CM_ "AUTOGENERATED MERGED FILE FROM MULTIPLE DBC FILES";

VERSION ""

NS_ :

BS_:

BU_: AAF AAF_Tester ABS ACU ADRV AEMC AFLS AHLS APRK AVM BCM CAMERA CGW CLU CUBIS DATC DI_BOX Dummy ECS EMS EPB ESC EVP FATC FPCM FRONT_RADAR HUD IAP IBOX LCA LDWS_LKAS LPI LVR MDPS MTS ODS OPI PGS PSB REA SAS SCC SMK SNV SPAS TCU TMU TPMS _4WD

VAL_TABLE_
    SIG_GROUP_
    SIG_VALTYPE_
    SIGTYPE_VALTYPE_
    BO_TX_BU_
    BA_DEF_REL_
    BA_REL_
    BA_DEF_DEF_REL_
    BU_SG_REL_
    BU_EV_REL_
    BU_BO_REL_
    SG_MUL_VAL_

BS_:

BU_: XXX CAMERA FRONT_RADAR ADRV APRK

BO_ 53 ACCELERATOR: 32 XXX
 SG_ CHECKSUM : 0|16@1+ (1,0) [0|65535] "" XXX
 SG_ COUNTER : 16|8@1+ (1,0) [0|255] "" XXX
 SG_ GEAR : 192|3@1+ (1,0) [0|7] "" XXX
 SG_ ACCELERATOR_PEDAL : 40|8@1+ (1,0) [0|255] "" XXX

BO_ 64 GEAR_ALT: 32 XXX
 SG_ CHECKSUM : 0|16@1+ (1,0) [0|65535] "" XXX
 SG_ COUNTER : 16|8@1+ (1,0) [0|255] "" XXX
 SG_ GEAR : 32|3@1+ (1,0) [0|7] "" XXX

BO_ 69 GEAR: 24 XXX
 SG_ CHECKSUM : 0|16@1+ (1,0) [0|65535] "" XXX
 SG_ COUNTER : 16|8@1+ (1,0) [0|255] "" XXX
 SG_ GEAR : 44|3@1+ (1,0) [0|7] "" XXX

BO_ 80 LKAS: 16 XXX
 SG_ STEER_REQ : 52|1@1+ (1,0) [0|1] "" XXX
 SG_ TORQUE_REQUEST : 41|11@1+ (1,-1024) [0|4095] "" XXX
 SG_ LKA_ICON : 38|2@1+ (1,0) [0|255] "" XXX
 SG_ NEW_SIGNAL_1 : 27|2@1+ (1,0) [0|255] "" XXX
 SG_ LFA_BUTTON : 56|1@1+ (1,0) [0|255] "" XXX
 SG_ COUNTER : 16|8@1+ (1,0) [0|255] "" XXX
 SG_ CHECKSUM : 0|16@1+ (1,0) [0|65535] "" XXX
 SG_ STEER_MODE : 65|3@1+ (1,0) [0|1] "" XXX
 SG_ LKA_WARNING : 32|1@1+ (1,0) [0|1] "" XXX
 SG_ LKA_ASSIST : 62|1@1+ (1,0) [0|1] "" XXX
 SG_ LKA_MODE : 24|3@1+ (1,0) [0|7] "" XXX
 SG_ NEW_SIGNAL_2 : 70|2@0+ (1,0) [0|3] "" XXX
 SG_ HAS_LANE_SAFETY : 80|1@0+ (1,0) [0|1] "" XXX
 SG_ NEW_SIGNAL_3 : 111|8@0+ (1,0) [0|255] "" XXX
 SG_ FCA_SYSWARN : 40|1@0+ (1,0) [0|1] "" XXX

BO_ 81 ADRV_0x51: 32 ADRV
 SG_ COUNTER : 16|8@1+ (1,0) [0|255] "" XXX
 SG_ CHECKSUM : 0|16@1+ (1,0) [0|65535] "" XXX

BO_ 96 ESP_STATUS: 32 XXX
 SG_ CHECKSUM : 0|16@1+ (1,0) [0|65535] "" XXX
 SG_ COUNTER : 16|8@1+ (1,0) [0|255] "" XXX
 SG_ TRACTION_AND_STABILITY_CONTROL : 42|3@1+ (1,0) [0|63] "" XXX
 SG_ BRAKE_PRESSURE : 128|10@1+ (1,0) [0|65535] "" XXX
 SG_ BRAKE_PRESSED : 148|1@1+ (1,0) [0|3] "" XXX

BO_ 101 BRAKE: 32 XXX
 SG_ CHECKSUM : 0|16@1+ (1,0) [0|65535] "" XXX
 SG_ COUNTER : 16|8@1+ (1,0) [0|255] "" XXX
 SG_ BRAKE_POSITION : 40|16@1- (1,0) [0|65535] "" XXX
 SG_ BRAKE_PRESSED : 57|1@1+ (1,0) [0|3] "" XXX

BO_ 112 GEAR_ALT_2: 32 XXX
 SG_ CHECKSUM : 0|16@1+ (1,0) [0|65535] "" XXX
 SG_ COUNTER : 16|8@1+ (1,0) [0|255] "" XXX
 SG_ GEAR : 60|3@1+ (1,0) [0|7] "" XXX

BO_ 160 WHEEL_SPEEDS: 24 XXX
 SG_ CHECKSUM : 0|16@1+ (1,0) [0|65535] "" XXX
 SG_ COUNTER : 16|8@1+ (1,0) [0|255] "" XXX
 SG_ MOVING_FORWARD : 56|1@0+ (1,0) [0|1] "" XXX
 SG_ MOVING_BACKWARD : 57|1@0+ (1,0) [0|1] "" XXX
 SG_ MOVING_FORWARD2 : 58|1@0+ (1,0) [0|1] "" XXX
 SG_ MOVING_BACKWARD2 : 59|1@0+ (1,0) [0|1] "" XXX
 SG_ WHEEL_SPEED_1 : 64|16@1+ (0.03125,0) [0|65535] "kph" XXX
 SG_ WHEEL_SPEED_2 : 80|16@1+ (0.03125,0) [0|65535] "kph" XXX
 SG_ WHEEL_SPEED_3 : 96|16@1+ (0.03125,0) [0|65535] "kph" XXX
 SG_ WHEEL_SPEED_4 : 112|16@1+ (0.03125,0) [0|65535] "kph" XXX

BO_ 234 MDPS: 24 XXX
 SG_ CHECKSUM : 0|16@1+ (1,0) [0|65535] "" XXX
 SG_ COUNTER : 16|8@1+ (1,0) [0|255] "" XXX
 SG_ LKA_ACTIVE : 48|1@0+ (1,0) [0|16777215] "" XXX
 SG_ LKA_FAULT : 54|1@0+ (1,0) [0|1] "" XXX
 SG_ STEERING_OUT_TORQUE : 64|12@1+ (0.1,-204.8) [0|65535] "" XXX
 SG_ STEERING_COL_TORQUE : 80|13@1+ (1,-4095) [0|4095] "" XXX
 SG_ STEERING_ANGLE : 96|16@1- (-0.1,0) [0|255] "deg" XXX
 SG_ STEERING_ANGLE_2 : 128|16@1- (-0.1,0) [0|65535] "deg" XXX

BO_ 256 ACCELERATOR_BRAKE_ALT: 32 XXX
 SG_ CHECKSUM : 0|16@1+ (1,0) [0|65535] "" XXX
 SG_ COUNTER : 16|8@1+ (1,0) [0|255] "" XXX
 SG_ BRAKE_PRESSED : 32|1@1+ (1,0) [0|1] "" XXX
 SG_ ACCELERATOR_PEDAL_PRESSED : 176|1@1+ (1,0) [0|1] "" XXX

BO_ 261 ACCELERATOR_ALT: 32 XXX
 SG_ CHECKSUM : 0|16@1+ (1,0) [0|65535] "" XXX
 SG_ COUNTER : 16|8@1+ (1,0) [0|255] "" XXX
 SG_ ACCELERATOR_PEDAL : 103|10@1+ (0.25,0) [0|1022] "" XXX

BO_ 272 LKAS_ALT: 32 XXX
 SG_ STEER_REQ : 52|1@1+ (1,0) [0|1] "" XXX
 SG_ TORQUE_REQUEST : 41|11@1+ (1,-1024) [0|4095] "" XXX
 SG_ LKA_ICON : 38|2@1+ (1,0) [0|255] "" XXX
 SG_ NEW_SIGNAL_1 : 27|2@1+ (1,0) [0|255] "" XXX
 SG_ LFA_BUTTON : 56|1@1+ (1,0) [0|255] "" XXX
 SG_ COUNTER : 16|8@1+ (1,0) [0|255] "" XXX
 SG_ CHECKSUM : 0|16@1+ (1,0) [0|65535] "" XXX
 SG_ STEER_MODE : 65|3@1+ (1,0) [0|1] "" XXX
 SG_ LKA_WARNING : 32|1@1+ (1,0) [0|1] "" XXX
 SG_ LKA_ASSIST : 62|1@1+ (1,0) [0|1] "" XXX
 SG_ LKA_MODE : 24|3@1+ (1,0) [0|7] "" XXX
 SG_ NEW_SIGNAL_2 : 70|2@0+ (1,0) [0|3] "" XXX
 SG_ HAS_LANE_SAFETY : 80|1@0+ (1,0) [0|1] "" XXX
 SG_ NEW_SIGNAL_3 : 111|8@0+ (1,0) [0|255] "" XXX
 SG_ FCA_SYSWARN : 40|1@0+ (1,0) [0|1] "" XXX

BO_ 293 STEERING_SENSORS: 16 XXX
 SG_ CHECKSUM : 0|16@1+ (1,0) [0|65535] "" XXX
 SG_ COUNTER : 16|8@1+ (1,0) [0|255] "" XXX
 SG_ STEERING_RATE : 40|8@1+ (4,0) [0|1016] "deg/s" XXX
 SG_ STEERING_ANGLE : 24|16@1- (-0.1,0) [0|255] "deg" XXX

BO_ 298 LFA: 16 ADRV
 SG_ STEER_REQ : 52|1@1+ (1,0) [0|1] "" XXX
 SG_ TORQUE_REQUEST : 41|11@1+ (1,-1024) [0|4095] "" XXX
 SG_ LKA_ICON : 38|2@1+ (1,0) [0|255] "" XXX
 SG_ NEW_SIGNAL_1 : 27|2@1+ (1,0) [0|255] "" XXX
 SG_ LFA_BUTTON : 56|1@1+ (1,0) [0|255] "" XXX
 SG_ COUNTER : 16|8@1+ (1,0) [0|255] "" XXX
 SG_ CHECKSUM : 0|16@1+ (1,0) [0|65535] "" XXX
 SG_ STEER_MODE : 65|3@1+ (1,0) [0|1] "" XXX
 SG_ LKA_WARNING : 32|1@1+ (1,0) [0|1] "" XXX
 SG_ LKA_ASSIST : 62|1@1+ (1,0) [0|1] "" XXX
 SG_ LKA_MODE : 24|3@1+ (1,0) [0|7] "" XXX
 SG_ NEW_SIGNAL_2 : 70|2@0+ (1,0) [0|3] "" XXX
 SG_ HAS_LANE_SAFETY : 80|1@0+ (1,0) [0|1] "" XXX
 SG_ NEW_SIGNAL_3 : 111|8@0+ (1,0) [0|255] "" XXX

BO_ 304 GEAR_SHIFTER: 16 XXX
 SG_ CHECKSUM : 0|16@1+ (1,0) [0|65535] "" XXX
 SG_ COUNTER : 16|8@1+ (1,0) [0|255] "" XXX
 SG_ PARK_BUTTON : 32|2@1+ (1,0) [0|3] "" XXX
 SG_ GEAR : 64|3@1+ (1,0) [0|7] "" XXX
 SG_ KNOB_POSITION : 40|3@1+ (1,0) [0|3] "" XXX

BO_ 357 SPAS1: 24 APRK
 SG_ CHECKSUM : 0|16@1+ (1,0) [0|65535] "" XXX
 SG_ COUNTER : 16|8@1+ (1,0) [0|0] "" XXX
 SG_ NEW_SIGNAL_1 : 96|16@1- (0.1,0) [0|0] "" XXX
 SG_ NEW_SIGNAL_2 : 90|3@1+ (1,0) [0|0] "" XXX

BO_ 362 SPAS2: 32 APRK
 SG_ CHECKSUM : 0|16@1+ (1,0) [0|65535] "" XXX
 SG_ COUNTER : 16|8@1+ (1,0) [0|0] "" XXX
 SG_ BLINKER_CONTROL : 133|3@1+ (1,0) [0|0] "" XXX

BO_ 373 TCS: 24 XXX
 SG_ CHECKSUM : 0|16@1+ (1,0) [0|65535] "" XXX
 SG_ COUNTER : 16|8@1+ (1,0) [0|255] "" XXX
 SG_ NEW_SIGNAL_1 : 80|1@0+ (1,0) [0|1] "" XXX
 SG_ NEW_SIGNAL_2 : 74|1@0+ (1,0) [0|1] "" XXX
 SG_ NEW_SIGNAL_3 : 76|1@0+ (1,0) [0|1] "" XXX
 SG_ NEW_SIGNAL_4 : 24|7@1+ (1,0) [0|127] "" XXX
 SG_ aBasis : 32|11@1+ (0.01,-10.23) [0|7] "m/s^2" XXX
 SG_ NEW_SIGNAL_5 : 72|1@0+ (1,0) [0|1] "" XXX
 SG_ NEW_SIGNAL_6 : 128|4@1+ (1,0) [0|15] "" XXX
 SG_ NEW_SIGNAL_7 : 135|2@0+ (1,0) [0|3] "" XXX
 SG_ PROBABLY_EQUIP : 136|2@1+ (1,0) [0|3] "" XXX
 SG_ AEB_EQUIP_MAYBE : 96|1@0+ (1,0) [0|1] "" XXX
 SG_ EQUIP_MAYBE : 64|1@0+ (1,0) [0|1] "" XXX
 SG_ DriverBraking : 81|1@0+ (1,0) [0|1] "" XXX
 SG_ DriverBrakingLowSens : 84|1@1+ (1,0) [0|1] "" XXX
 SG_ ACC_REQ : 68|1@0+ (1,0) [0|1] "" XXX
 SG_ ACCEL_REF_ACC : 48|11@1- (1,0) [0|1023] "" XXX
 SG_ ACCEnable : 67|2@0+ (1,0) [0|3] "" XXX

BO_ 352 ADRV_0x160: 16 ADRV
 SG_ CHECKSUM : 0|16@1+ (1,0) [0|65535] "" XXX
 SG_ COUNTER : 16|8@1+ (1,0) [0|255] "" XXX
 SG_ SET_ME_FF : 64|8@1+ (1,0) [0|255] "" XXX
 SG_ SET_ME_FC : 72|8@1+ (1,0) [0|255] "" XXX
 SG_ SET_ME_2 : 56|8@1+ (1,0) [0|1] "" XXX
 SG_ AEB_SETTING : 24|2@1+ (1,0) [0|255] "" XXX
 SG_ SET_ME_9 : 80|8@1+ (1,0) [0|255] "" XXX

BO_ 384 CAM_0x180: 32 CAMERA
 SG_ CHECKSUM : 0|16@1+ (1,0) [0|65535] "" XXX
 SG_ COUNTER : 16|8@1+ (1,0) [0|255] "" XXX

BO_ 385 CAM_0x181: 32 CAMERA
 SG_ CHECKSUM : 0|16@1+ (1,0) [0|65535] "" XXX
 SG_ COUNTER : 16|8@1+ (1,0) [0|255] "" XXX

BO_ 386 CAM_0x182: 32 CAMERA
 SG_ CHECKSUM : 0|16@1+ (1,0) [0|65535] "" XXX
 SG_ COUNTER : 16|8@1+ (1,0) [0|255] "" XXX

BO_ 387 CAM_0x183: 32 CAMERA
 SG_ CHECKSUM : 0|16@1+ (1,0) [0|65535] "" XXX
 SG_ COUNTER : 16|8@1+ (1,0) [0|255] "" XXX

BO_ 388 CAM_0x184: 32 CAMERA
 SG_ CHECKSUM : 0|16@1+ (1,0) [0|65535] "" XXX
 SG_ COUNTER : 16|8@1+ (1,0) [0|255] "" XXX

BO_ 389 CAM_0x185: 8 CAMERA
 SG_ CHECKSUM : 0|16@1+ (1,0) [0|65535] "" XXX
 SG_ COUNTER : 16|8@1+ (1,0) [0|255] "" XXX

BO_ 416 SCC_CONTROL: 32 ADRV
 SG_ CHECKSUM : 0|16@1+ (1,0) [0|65535] "" XXX
 SG_ NEW_SIGNAL_1 : 64|2@1+ (1,0) [0|3] "" XXX
 SG_ NEW_SIGNAL_8 : 170|4@1+ (1,0) [0|15] "" XXX
 SG_ ZEROS : 215|48@0+ (1,0) [0|281474976710655] "" XXX
 SG_ ZEROS_3 : 191|7@0+ (1,0) [0|127] "" XXX
 SG_ ZEROS_4 : 183|4@0+ (1,0) [0|63] "" XXX
 SG_ ZEROS_6 : 119|16@0+ (1,0) [0|65535] "" XXX
 SG_ ZEROS_8 : 95|5@0+ (1,0) [0|31] "" XXX
 SG_ NEW_SIGNAL_3 : 109|2@0+ (1,0) [0|1] "" XXX
 SG_ SET_ME_TMP_64 : 55|8@0+ (1,0) [0|63] "" XXX
 SG_ SET_ME_2 : 105|3@1+ (1,0) [0|7] "" XXX
 SG_ NEW_SIGNAL_6 : 104|1@0+ (1,0) [0|1] "" XXX
 SG_ COUNTER : 16|8@1+ (1,0) [0|255] "" XXX
 SG_ ZEROS_9 : 71|5@1+ (1,0) [0|15] "" XXX
 SG_ ZEROS_10 : 111|2@0+ (1,0) [0|3] "" XXX
 SG_ SET_ME_3 : 45|2@0+ (1,0) [0|3] "" XXX
 SG_ ObjValid : 46|1@0+ (1,0) [0|3] "" XXX
 SG_ NEW_SIGNAL_2 : 168|2@1+ (1,0) [0|3] "" XXX
 SG_ OBJ_STATUS : 176|3@1+ (1,0) [0|7] "" XXX
 SG_ ACC_ObjDist : 24|11@1+ (0.1,0) [0|204.7] "m" XXX
 SG_ ZEROS_5 : 77|11@1+ (1,0) [0|2047] "" XXX
 SG_ DISTANCE_SETTING : 88|3@1+ (1,0) [0|3] "" XXX
 SG_ ZEROS_2 : 207|5@0+ (1,0) [0|63] "" XXX
 SG_ CRUISE_STANDSTILL : 76|1@1+ (1,0) [0|1] "" XXX
 SG_ aReqRaw : 140|11@1+ (0.01,-10.23) [-10.23|10.24] "m/s^2" XXX
 SG_ aReqValue : 128|11@1+ (0.01,-10.23) [-10.23|10.24] "m/s^2" XXX
 SG_ ZEROS_7 : 63|8@0+ (1,0) [0|255] "" XXX
 SG_ ACCMode : 68|3@1+ (1,0) [0|7] "" XXX
 SG_ ACC_ObjRelSpd : 35|9@1+ (0.1,-16.4) [-16.4|34.7] "m/s" XXX
 SG_ JerkLowerLimit : 166|7@0+ (0.1,0) [0|12.7] "m/s^3" XXX
 SG_ StopReq : 184|1@0+ (1,0) [0|1] "" XXX
 SG_ NEW_SIGNAL_15 : 192|11@1+ (0.1,0) [0|204.7] "m" XXX
 SG_ VSetDis : 103|8@0+ (1,0) [0|255] "km/h or mph" XXX
 SG_ MainMode_ACC : 66|1@1+ (1,0) [0|1] "" XXX
 SG_ JerkUpperLimit : 158|7@0+ (0.1,0) [0|0] "" XXX

BO_ 426 CRUISE_BUTTONS_ALT: 16 XXX
 SG_ CHECKSUM : 0|16@1+ (1,0) [0|65535] "" XXX
 SG_ COUNTER : 16|8@1+ (1,0) [0|255] "" XXX
 SG_ NEW_SIGNAL_1 : 24|4@1+ (1,0) [0|15] "" XXX
 SG_ SET_ME_1 : 28|2@1+ (1,0) [0|3] "" XXX
 SG_ DISTANCE_UNIT : 30|1@1+ (1,0) [0|1] "" XXX
 SG_ NEW_SIGNAL_2 : 31|3@1+ (1,0) [0|7] "" XXX
 SG_ ADAPTIVE_CRUISE_MAIN_BTN : 34|1@1+ (1,0) [0|1] "" XXX
 SG_ NEW_SIGNAL_3 : 35|1@1+ (1,0) [0|1] "" XXX
 SG_ LFA_BTN : 39|1@1+ (1,0) [0|1] "" XXX
 SG_ CRUISE_BUTTONS : 36|3@1+ (1,0) [0|4] "" XXX
 SG_ NEW_SIGNAL_4 : 40|1@1+ (1,0) [0|1] "" XXX
 SG_ NORMAL_CRUISE_MAIN_BTN : 41|1@1+ (1,0) [0|1] "" XXX
 SG_ NEW_SIGNAL_5 : 42|2@1+ (1,0) [0|3] "" XXX
 SG_ SET_ME_2 : 44|3@1+ (1,0) [0|7] "" XXX
 SG_ NEW_SIGNAL_6 : 47|1@1+ (1,0) [0|1] "" XXX
 SG_ BYTE6 : 48|8@1+ (1,0) [0|255] "" XXX
 SG_ BYTE7 : 56|8@1+ (1,0) [0|255] "" XXX
 SG_ BYTE8 : 64|8@1+ (1,0) [0|255] "" XXX
 SG_ BYTE9 : 72|8@1+ (1,0) [0|255] "" XXX
 SG_ BYTE10 : 80|8@1+ (1,0) [0|255] "" XXX
 SG_ BYTE11 : 88|8@1+ (1,0) [0|255] "" XXX
 SG_ BYTE12 : 96|8@1+ (1,0) [0|255] "" XXX
 SG_ BYTE13 : 104|8@1+ (1,0) [0|255] "" XXX
 SG_ BYTE14 : 112|8@1+ (1,0) [0|255] "" XXX
 SG_ BYTE15 : 120|8@1+ (1,0) [0|255] "" XXX

BO_ 438 CAM_0x1b6: 32 CAMERA
 SG_ CHECKSUM : 0|16@1+ (1,0) [0|65535] "" XXX
 SG_ COUNTER : 16|8@1+ (1,0) [0|255] "" XXX

BO_ 439 CAM_0x1b7: 32 CAMERA
 SG_ CHECKSUM : 0|16@1+ (1,0) [0|65535] "" XXX
 SG_ COUNTER : 16|8@1+ (1,0) [0|255] "" XXX

BO_ 440 CAM_0x1b8: 32 CAMERA
 SG_ CHECKSUM : 0|16@1+ (1,0) [0|65535] "" XXX
 SG_ COUNTER : 16|8@1+ (1,0) [0|255] "" XXX

BO_ 441 CAM_0x1b9: 32 CAMERA
 SG_ CHECKSUM : 0|16@1+ (1,0) [0|65535] "" XXX
 SG_ COUNTER : 16|8@1+ (1,0) [0|255] "" XXX

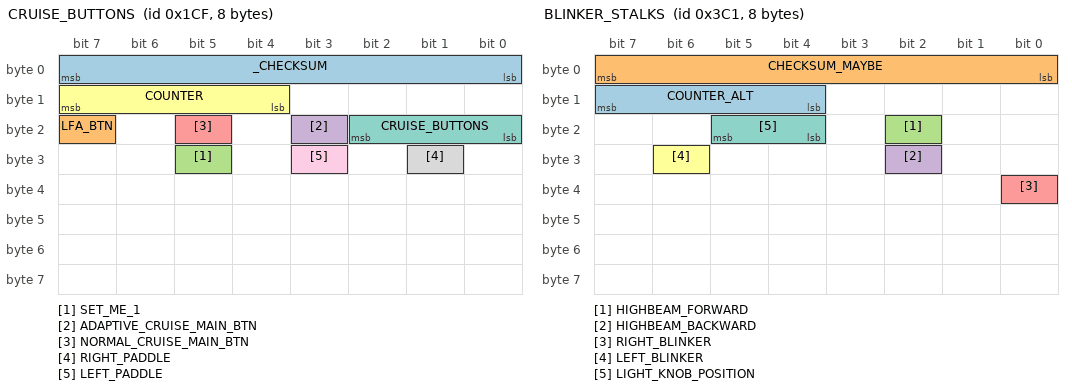
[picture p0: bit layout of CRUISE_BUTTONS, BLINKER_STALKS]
BO_ 463 CRUISE_BUTTONS: 8 XXX
 SG_ _CHECKSUM : 0|8@1+ (1,0) [0|65535] "" XXX
 SG_ LFA_BTN : 23|1@1+ (1,0) [0|1] "" XXX
 SG_ SET_ME_1 : 29|1@1+ (1,0) [0|1] "" XXX
 SG_ ADAPTIVE_CRUISE_MAIN_BTN : 19|1@1+ (1,0) [0|1] "" XXX
 SG_ NORMAL_CRUISE_MAIN_BTN : 21|1@1+ (1,0) [0|1] "" XXX
 SG_ COUNTER : 12|4@1+ (1,0) [0|255] "" XXX
 SG_ CRUISE_BUTTONS : 16|3@1+ (1,0) [0|3] "" XXX
 SG_ RIGHT_PADDLE : 25|1@1+ (1,0) [0|1] "" XXX
 SG_ LEFT_PADDLE : 27|1@1+ (1,0) [0|1] "" XXX

BO_ 474 ADRV_0x1da: 32 ADRV
 SG_ CHECKSUM : 0|16@1+ (1,0) [0|65535] "" XXX
 SG_ COUNTER : 16|8@1+ (1,0) [0|255] "" XXX
 SG_ SET_ME_22 : 31|8@0+ (1,0) [0|255] "" XXX
 SG_ SET_ME_41 : 47|8@0+ (1,0) [0|255] "" XXX

BO_ 480 LFAHDA_CLUSTER: 16 ADRV
 SG_ CHECKSUM : 0|16@1+ (1,0) [0|65535] "" XXX
 SG_ COUNTER : 16|8@1+ (1,0) [0|255] "" XXX
 SG_ HDA_ICON : 31|1@1+ (1,0) [0|1] "" XXX
 SG_ LFA_ICON : 47|2@1+ (1,0) [0|3] "" XXX
 SG_ NEW_SIGNAL_1 : 32|3@1+ (1,0) [0|7] "" XXX
 SG_ NEW_SIGNAL_2 : 30|1@0+ (1,0) [0|1] "" XXX
 SG_ NEW_SIGNAL_3 : 49|1@0+ (1,0) [0|1] "" XXX
 SG_ NEW_SIGNAL_4 : 24|1@0+ (1,0) [0|1] "" XXX

BO_ 490 ADRV_0x1ea: 32 ADRV
 SG_ CHECKSUM : 0|16@1+ (1,0) [0|65535] "" XXX
 SG_ COUNTER : 16|8@1+ (1,0) [0|255] "" XXX
 SG_ SET_ME_1C : 31|8@0+ (1,0) [0|255] "" XXX
 SG_ NEW_SIGNAL_1 : 32|2@1+ (1,0) [0|3] "" XXX
 SG_ NEW_SIGNAL_2 : 47|2@0+ (1,0) [0|3] "" XXX
 SG_ NEW_SIGNAL_3 : 55|8@0+ (1,0) [0|255] "" XXX
 SG_ NEW_SIGNAL_4 : 64|6@1+ (1,0) [0|31] "" XXX
 SG_ NEW_SIGNAL_5 : 72|2@1+ (1,0) [0|3] "" XXX
 SG_ NEW_SIGNAL_6 : 75|5@1+ (1,0) [0|31] "" XXX
 SG_ NEW_SIGNAL_7 : 80|5@1+ (1,0) [0|31] "" XXX
 SG_ NEW_SIGNAL_8 : 88|7@1+ (1,0) [0|127] "" XXX
 SG_ NEW_SIGNAL_9 : 96|1@0+ (1,0) [0|1] "" XXX
 SG_ NEW_SIGNAL_10 : 143|5@0+ (1,0) [0|31] "" XXX
 SG_ NEW_SIGNAL_11 : 144|3@1+ (1,0) [0|7] "" XXX
 SG_ NEW_SIGNAL_12 : 152|6@1+ (1,0) [0|63] "" XXX
 SG_ NEW_SIGNAL_13 : 160|1@0+ (1,0) [0|1] "" XXX
 SG_ NEW_SIGNAL_14 : 163|5@1+ (1,0) [0|31] "" XXX
 SG_ NEW_SIGNAL_15 : 175|4@0+ (1,0) [0|63] "" XXX
 SG_ NEW_SIGNAL_16 : 168|3@1+ (1,0) [0|7] "" XXX
 SG_ NEW_SIGNAL_17 : 176|2@1+ (1,0) [0|3] "" XXX
 SG_ NEW_SIGNAL_18 : 184|1@0+ (1,0) [0|1] "" XXX
 SG_ NEW_SIGNAL_19 : 208|3@1+ (1,0) [0|7] "" XXX
 SG_ NEW_SIGNAL_20 : 212|1@0+ (1,0) [0|1] "" XXX
 SG_ SET_ME_FF : 120|8@1+ (1,0) [0|255] "" XXX
 SG_ SET_ME_TMP_F : 232|5@1+ (1,0) [0|31] "" XXX
 SG_ SET_ME_TMP_F_2 : 240|5@1+ (1,0) [0|31] "" XXX

BO_ 507 CAM_0x1fb: 32 CAMERA
 SG_ CHECKSUM : 0|16@1+ (1,0) [0|65535] "" XXX
 SG_ COUNTER : 16|8@1+ (1,0) [0|255] "" XXX

BO_ 512 ADRV_0x200: 8 ADRV
 SG_ CHECKSUM : 0|16@1+ (1,0) [0|65535] "" XXX
 SG_ COUNTER : 16|8@1+ (1,0) [0|255] "" XXX
 SG_ SET_ME_E1 : 24|8@1+ (1,0) [0|255] "" XXX
 SG_ SET_ME_3A : 32|8@1+ (1,0) [0|255] "" XXX

BO_ 513 RADAR_0x201: 32 FRONT_RADAR
 SG_ CHECKSUM : 0|16@1+ (1,0) [0|65535] "" XXX
 SG_ COUNTER : 16|8@1+ (1,0) [0|255] "" XXX

BO_ 528 RADAR_0x210: 32 FRONT_RADAR
 SG_ CHECKSUM : 0|16@1+ (1,0) [0|65535] "" XXX
 SG_ COUNTER : 16|8@1+ (1,0) [0|255] "" XXX

BO_ 529 RADAR_0x211: 32 FRONT_RADAR
 SG_ CHECKSUM : 0|16@1+ (1,0) [0|65535] "" XXX
 SG_ COUNTER : 16|8@1+ (1,0) [0|255] "" XXX

BO_ 530 RADAR_0x212: 32 FRONT_RADAR
 SG_ CHECKSUM : 0|16@1+ (1,0) [0|65535] "" XXX
 SG_ COUNTER : 16|8@1+ (1,0) [0|255] "" XXX

BO_ 531 RADAR_0x213: 32 FRONT_RADAR
 SG_ CHECKSUM : 0|16@1+ (1,0) [0|65535] "" XXX
 SG_ COUNTER : 16|8@1+ (1,0) [0|255] "" XXX

BO_ 532 RADAR_0x214: 32 FRONT_RADAR
 SG_ CHECKSUM : 0|16@1+ (1,0) [0|65535] "" XXX
 SG_ COUNTER : 16|8@1+ (1,0) [0|255] "" XXX

BO_ 533 RADAR_0x215: 32 FRONT_RADAR
 SG_ CHECKSUM : 0|16@1+ (1,0) [0|65535] "" XXX
 SG_ COUNTER : 16|8@1+ (1,0) [0|255] "" XXX

BO_ 534 RADAR_0x216: 32 FRONT_RADAR
 SG_ CHECKSUM : 0|16@1+ (1,0) [0|65535] "" XXX
 SG_ COUNTER : 16|8@1+ (1,0) [0|255] "" XXX

BO_ 535 RADAR_0x217: 32 FRONT_RADAR
 SG_ CHECKSUM : 0|16@1+ (1,0) [0|65535] "" XXX
 SG_ COUNTER : 16|8@1+ (1,0) [0|255] "" XXX

BO_ 536 RADAR_0x218: 32 FRONT_RADAR
 SG_ CHECKSUM : 0|16@1+ (1,0) [0|65535] "" XXX
 SG_ COUNTER : 16|8@1+ (1,0) [0|255] "" XXX

BO_ 537 RADAR_0x219: 32 FRONT_RADAR
 SG_ CHECKSUM : 0|16@1+ (1,0) [0|65535] "" XXX
 SG_ COUNTER : 16|8@1+ (1,0) [0|255] "" XXX

BO_ 538 RADAR_0x21a: 32 FRONT_RADAR
 SG_ CHECKSUM : 0|16@1+ (1,0) [0|65535] "" XXX
 SG_ COUNTER : 16|8@1+ (1,0) [0|255] "" XXX

BO_ 539 RADAR_0x21b: 32 FRONT_RADAR
 SG_ CHECKSUM : 0|16@1+ (1,0) [0|65535] "" XXX
 SG_ COUNTER : 16|8@1+ (1,0) [0|255] "" XXX

BO_ 540 RADAR_0x21c: 32 FRONT_RADAR
 SG_ CHECKSUM : 0|16@1+ (1,0) [0|65535] "" XXX
 SG_ COUNTER : 16|8@1+ (1,0) [0|255] "" XXX

BO_ 541 RADAR_0x21d: 32 FRONT_RADAR
 SG_ CHECKSUM : 0|16@1+ (1,0) [0|65535] "" XXX
 SG_ COUNTER : 16|8@1+ (1,0) [0|255] "" XXX

BO_ 542 RADAR_0x21e: 32 FRONT_RADAR
 SG_ CHECKSUM : 0|16@1+ (1,0) [0|65535] "" XXX
 SG_ COUNTER : 16|8@1+ (1,0) [0|255] "" XXX

BO_ 543 RADAR_0x21f: 32 FRONT_RADAR
 SG_ CHECKSUM : 0|16@1+ (1,0) [0|65535] "" XXX
 SG_ COUNTER : 16|8@1+ (1,0) [0|255] "" XXX

BO_ 576 RADAR_0x240: 16 FRONT_RADAR
 SG_ CHECKSUM : 0|16@1+ (1,0) [0|65535] "" XXX
 SG_ COUNTER : 16|8@1+ (1,0) [0|255] "" XXX

BO_ 593 RADAR_0x251: 16 FRONT_RADAR
 SG_ CHECKSUM : 0|16@1+ (1,0) [0|65535] "" XXX
 SG_ COUNTER : 16|8@1+ (1,0) [0|255] "" XXX

BO_ 674 CAM_0x2a2: 32 CAMERA
 SG_ CHECKSUM : 0|16@1+ (1,0) [0|65535] "" XXX
 SG_ COUNTER : 16|8@1+ (1,0) [0|255] "" XXX

BO_ 675 CAM_0x2a3: 32 CAMERA
 SG_ CHECKSUM : 0|16@1+ (1,0) [0|65535] "" XXX
 SG_ COUNTER : 16|8@1+ (1,0) [0|255] "" XXX

BO_ 676 CAM_0x2a4: 24 XXX
 SG_ CHECKSUM : 0|16@1+ (1,0) [0|65535] "" XXX
 SG_ COUNTER : 16|8@1+ (1,0) [0|255] "" XXX
 SG_ BYTE3 : 24|8@1+ (1,0) [0|255] "" XXX
 SG_ BYTE4 : 32|8@1+ (1,0) [0|255] "" XXX
 SG_ BYTE5 : 40|8@1+ (1,0) [0|255] "" XXX
 SG_ BYTE6 : 48|8@1+ (1,0) [0|255] "" XXX
 SG_ LEFT_LANE_LINE : 56|2@1+ (1,0) [0|3] "" XXX
 SG_ SET_ME_0 : 58|2@1+ (1,0) [0|3] "" XXX
 SG_ RIGHT_LANE_LINE : 60|2@1+ (1,0) [0|3] "" XXX
 SG_ SET_ME_0_2 : 62|2@1+ (1,0) [0|3] "" XXX
 SG_ BYTE8 : 64|8@1+ (1,0) [0|255] "" XXX
 SG_ BYTE9 : 72|8@1+ (1,0) [0|255] "" XXX
 SG_ BYTE10 : 80|8@1+ (1,0) [0|255] "" XXX
 SG_ BYTE11 : 88|8@1+ (1,0) [0|255] "" XXX
 SG_ BYTE12 : 96|8@1+ (1,0) [0|255] "" XXX
 SG_ BYTE13 : 104|8@1+ (1,0) [0|255] "" XXX
 SG_ BYTE14 : 112|8@1+ (1,0) [0|255] "" XXX
 SG_ BYTE15 : 120|8@1+ (1,0) [0|255] "" XXX
 SG_ BYTE16 : 128|8@1+ (1,0) [0|255] "" XXX
 SG_ BYTE17 : 136|8@1+ (1,0) [0|255] "" XXX
 SG_ BYTE18 : 144|8@1+ (1,0) [0|255] "" XXX
 SG_ BYTE19 : 152|8@1+ (1,0) [0|255] "" XXX
 SG_ BYTE20 : 160|8@1+ (1,0) [0|255] "" XXX
 SG_ BYTE21 : 168|8@1+ (1,0) [0|255] "" XXX
 SG_ BYTE22 : 176|8@1+ (1,0) [0|255] "" XXX
 SG_ BYTE23 : 184|8@1+ (1,0) [0|255] "" XXX

BO_ 699 CAM_0x2bb: 32 CAMERA
 SG_ CHECKSUM : 0|16@1+ (1,0) [0|65535] "" XXX
 SG_ COUNTER : 16|8@1+ (1,0) [0|255] "" XXX

BO_ 700 CAM_0x2bc: 32 CAMERA
 SG_ CHECKSUM : 0|16@1+ (1,0) [0|65535] "" XXX
 SG_ COUNTER : 16|8@1+ (1,0) [0|255] "" XXX

BO_ 701 CAM_0x2bd: 32 CAMERA
 SG_ CHECKSUM : 0|16@1+ (1,0) [0|65535] "" XXX
 SG_ COUNTER : 16|8@1+ (1,0) [0|255] "" XXX

BO_ 702 CAM_0x2be: 32 CAMERA
 SG_ CHECKSUM : 0|16@1+ (1,0) [0|65535] "" XXX
 SG_ COUNTER : 16|8@1+ (1,0) [0|255] "" XXX

BO_ 736 MANUAL_SPEED_LIMIT_ASSIST: 32 XXX
 SG_ CHECKSUM : 0|16@1+ (1,0) [0|65535] "" XXX
 SG_ COUNTER : 16|8@1+ (1,0) [0|255] "" XXX
 SG_ MSLA_STATUS : 26|2@1+ (1,0) [0|3] "" XXX
 SG_ MSLA_ENABLED : 38|1@1+ (1,0) [0|1] "" XXX
 SG_ MAX_SPEED : 55|8@0+ (1,0) [0|255] "" XXX
 SG_ MAX_SPEED_COPY : 144|8@1+ (1,0) [0|255] "" XXX

BO_ 837 ADRV_0x345: 8 ADRV
 SG_ CHECKSUM : 0|16@1+ (1,0) [0|65535] "" XXX
 SG_ COUNTER : 16|8@1+ (1,0) [0|255] "" XXX
 SG_ SET_ME_15 : 24|8@1+ (1,0) [0|255] "" XXX

BO_ 866 CAM_0x362: 32 CAMERA
 SG_ CHECKSUM : 0|16@1+ (1,0) [0|65535] "" XXX
 SG_ COUNTER : 16|8@1+ (1,0) [0|255] "" XXX
 SG_ BYTE3 : 24|8@1+ (1,0) [0|255] "" XXX
 SG_ BYTE4 : 32|8@1+ (1,0) [0|255] "" XXX
 SG_ BYTE5 : 40|8@1+ (1,0) [0|255] "" XXX
 SG_ BYTE6 : 48|8@1+ (1,0) [0|255] "" XXX
 SG_ LEFT_LANE_LINE : 56|2@1+ (1,0) [0|3] "" XXX
 SG_ SET_ME_0 : 58|2@1+ (1,0) [0|3] "" XXX
 SG_ RIGHT_LANE_LINE : 60|2@1+ (1,0) [0|3] "" XXX
 SG_ SET_ME_0_2 : 62|2@1+ (1,0) [0|3] "" XXX
 SG_ BYTE8 : 64|8@1+ (1,0) [0|255] "" XXX
 SG_ BYTE9 : 72|8@1+ (1,0) [0|255] "" XXX
 SG_ BYTE10 : 80|8@1+ (1,0) [0|255] "" XXX
 SG_ BYTE11 : 88|8@1+ (1,0) [0|255] "" XXX
 SG_ BYTE12 : 96|8@1+ (1,0) [0|255] "" XXX
 SG_ BYTE13 : 104|8@1+ (1,0) [0|255] "" XXX
 SG_ BYTE14 : 112|8@1+ (1,0) [0|255] "" XXX
 SG_ BYTE15 : 120|8@1+ (1,0) [0|255] "" XXX
 SG_ BYTE16 : 128|8@1+ (1,0) [0|255] "" XXX
 SG_ BYTE17 : 136|8@1+ (1,0) [0|255] "" XXX
 SG_ BYTE18 : 144|8@1+ (1,0) [0|255] "" XXX
 SG_ BYTE19 : 152|8@1+ (1,0) [0|255] "" XXX
 SG_ BYTE20 : 160|8@1+ (1,0) [0|255] "" XXX
 SG_ BYTE21 : 168|8@1+ (1,0) [0|255] "" XXX
 SG_ BYTE22 : 176|8@1+ (1,0) [0|255] "" XXX
 SG_ BYTE23 : 184|8@1+ (1,0) [0|255] "" XXX
 SG_ BYTE24 : 192|8@1+ (1,0) [0|255] "" XXX
 SG_ BYTE25 : 200|8@1+ (1,0) [0|255] "" XXX
 SG_ BYTE26 : 208|8@1+ (1,0) [0|255] "" XXX
 SG_ BYTE27 : 216|8@1+ (1,0) [0|255] "" XXX
 SG_ BYTE28 : 224|8@1+ (1,0) [0|255] "" XXX
 SG_ BYTE29 : 232|8@1+ (1,0) [0|255] "" XXX
 SG_ BYTE30 : 240|8@1+ (1,0) [0|255] "" XXX
 SG_ BYTE31 : 248|8@1+ (1,0) [0|255] "" XXX

BO_ 961 BLINKER_STALKS: 8 XXX
 SG_ COUNTER_ALT : 15|4@0+ (1,0) [0|15] "" XXX
 SG_ CHECKSUM_MAYBE : 7|8@0+ (1,0) [0|255] "" XXX
 SG_ HIGHBEAM_FORWARD : 18|1@0+ (1,0) [0|1] "" XXX
 SG_ HIGHBEAM_BACKWARD : 26|1@0+ (1,0) [0|1] "" XXX
 SG_ RIGHT_BLINKER : 32|1@0+ (1,0) [0|1] "" XXX
 SG_ LEFT_BLINKER : 30|1@0+ (1,0) [0|1] "" XXX
 SG_ LIGHT_KNOB_POSITION : 21|2@0+ (1,0) [0|3] "" XXX

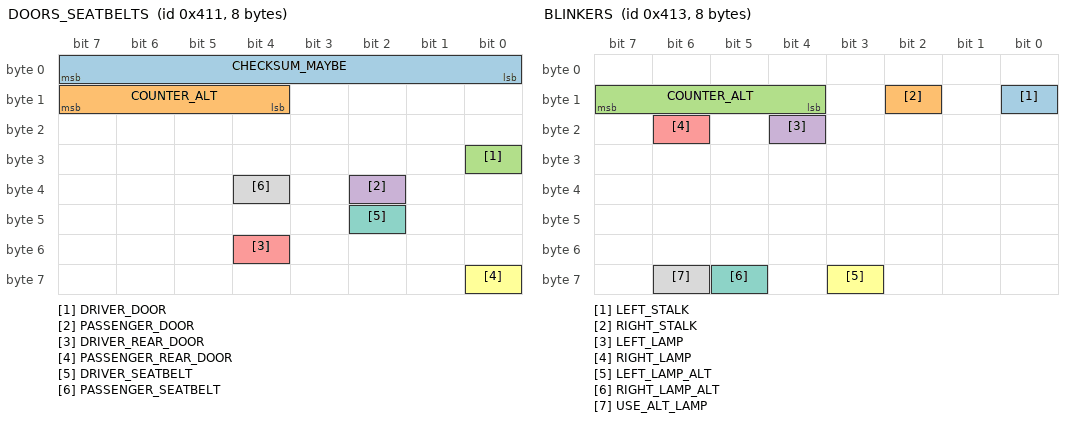
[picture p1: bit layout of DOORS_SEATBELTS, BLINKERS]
BO_ 1041 DOORS_SEATBELTS: 8 XXX
 SG_ CHECKSUM_MAYBE : 7|8@0+ (1,0) [0|65535] "" XXX
 SG_ COUNTER_ALT : 15|4@0+ (1,0) [0|15] "" XXX
 SG_ DRIVER_DOOR : 24|1@1+ (1,0) [0|1] "" XXX
 SG_ PASSENGER_DOOR : 34|1@0+ (1,0) [0|1] "" XXX
 SG_ DRIVER_REAR_DOOR : 52|1@0+ (1,0) [0|1] "" XXX
 SG_ PASSENGER_REAR_DOOR : 56|1@0+ (1,0) [0|1] "" XXX
 SG_ DRIVER_SEATBELT : 42|1@0+ (1,0) [0|1] "" XXX
 SG_ PASSENGER_SEATBELT : 36|1@0+ (1,0) [0|1] "" XXX

BO_ 1043 BLINKERS: 8 XXX
 SG_ LEFT_STALK : 8|1@0+ (1,0) [0|1] "" XXX
 SG_ RIGHT_STALK : 10|1@0+ (1,0) [0|1] "" XXX
 SG_ COUNTER_ALT : 15|4@0+ (1,0) [0|15] "" XXX
 SG_ LEFT_LAMP : 20|1@0+ (1,0) [0|1] "" XXX
 SG_ RIGHT_LAMP : 22|1@0+ (1,0) [0|1] "" XXX
 SG_ LEFT_LAMP_ALT : 59|1@0+ (1,0) [0|1] "" XXX
 SG_ RIGHT_LAMP_ALT : 61|1@0+ (1,0) [0|1] "" XXX
 SG_ USE_ALT_LAMP : 62|1@0+ (1,0) [0|1] "" XXX

BO_ 1240 CLUSTER_INFO: 8 XXX
 SG_ DISTANCE_UNIT : 0|1@1+ (1,0) [0|1] "" XXX

BO_ 442 BLINDSPOTS_REAR_CORNERS: 24 XXX
 SG_ COUNTER : 16|8@1+ (1,0) [0|255] "" XXX
 SG_ CHECKSUM : 0|16@1+ (1,0) [0|65535] "" XXX
 SG_ NEW_SIGNAL_2 : 96|1@0+ (1,0) [0|1] "" XXX
 SG_ COLLISION_AVOIDANCE_ACTIVE : 68|1@0+ (1,0) [0|1] "" XXX
 SG_ LEFT_MB : 30|1@0+ (1,0) [0|3] "" XXX
 SG_ LEFT_BLOCKED : 24|1@0+ (1,0) [0|1] "" XXX
 SG_ MORE_LEFT_PROB : 32|1@1+ (1,0) [0|3] "" XXX
 SG_ FL_INDICATOR : 46|6@0+ (1,0) [0|1] "" XXX
 SG_ FR_INDICATOR : 54|6@0+ (1,0) [0|63] "" XXX
 SG_ RIGHT_BLOCKED : 64|1@0+ (1,0) [0|1] "" XXX
 SG_ FL_INDICATOR_ALT : 138|1@0+ (1,0) [0|1] "" XXX
 SG_ FR_INDICATOR_ALT : 141|1@0+ (1,0) [0|1] "" XXX

BO_ 874 BLINDSPOTS_FRONT_CORNER_2: 16 XXX
 SG_ COUNTER : 16|8@1+ (1,0) [0|255] "" XXX
 SG_ CHECKSUM : 0|16@1+ (1,0) [0|65535] "" XXX

BO_ 485 BLINDSPOTS_FRONT_CORNER_1: 16 XXX
 SG_ COUNTER : 16|8@1+ (1,0) [0|255] "" XXX
 SG_ CHECKSUM : 0|16@1+ (1,0) [0|65535] "" XXX
 SG_ NEW_SIGNAL_1 : 108|2@0+ (1,0) [0|3] "" XXX
 SG_ NEW_SIGNAL_2 : 96|1@0+ (1,0) [0|1] "" XXX
 SG_ NEW_SIGNAL_3 : 88|1@0+ (1,0) [0|1] "" XXX
 SG_ NEW_SIGNAL_4 : 80|1@0+ (1,0) [0|1] "" XXX
 SG_ NEW_SIGNAL_5 : 31|2@0+ (1,0) [0|3] "" XXX
 SG_ REVERSING : 24|1@0+ (1,0) [0|1] "" XXX
 SG_ NEW_SIGNAL_7 : 32|2@1+ (1,0) [0|3] "" XXX
 SG_ NEW_SIGNAL_8 : 47|8@0+ (1,0) [0|255] "" XXX
 SG_ NEW_SIGNAL_9 : 55|8@0+ (1,0) [0|255] "" XXX

BO_ 506 CLUSTER_SPEED_LIMIT: 32 XXX
 SG_ SPEED_LIMIT_3 : 119|8@0+ (1,0) [0|255] "" XXX
 SG_ SPEED_LIMIT_2 : 47|7@0+ (1,0) [0|255] "" XXX
 SG_ SPEED_LIMIT_1 : 39|7@0+ (1,0) [0|255] "" XXX
 SG_ SPEED_CHANGE_BLINKING : 129|1@1+ (1,0) [0|3] "" XXX
 SG_ CHIME_2 : 122|2@1+ (1,0) [0|7] "" XXX
 SG_ CHIME_1 : 133|1@0+ (1,0) [0|1] "" XXX
 SG_ ARROW_DOWN : 120|1@0+ (1,0) [0|1] "" XXX
 SG_ ARROW_UP : 121|1@0+ (1,0) [0|1] "" XXX
 SG_ SECONDARY_LIMIT_1 : 79|8@0+ (1,0) [0|127] "" XXX
 SG_ SECONDARY_LIMIT_2 : 103|8@0+ (1,0) [0|127] "" XXX
 SG_ SCHOOL_ZONE : 155|1@0+ (1,0) [0|1] "" XXX

BO_ 1144 DRIVE_MODE: 8 XXX
 SG_ DRIVE_MODE : 0|16@1+ (1,-61611) [0|61611] "" XXX
 SG_ DRIVE_MODE2 : 28|3@1+ (1,0) [1|3] "" XXX

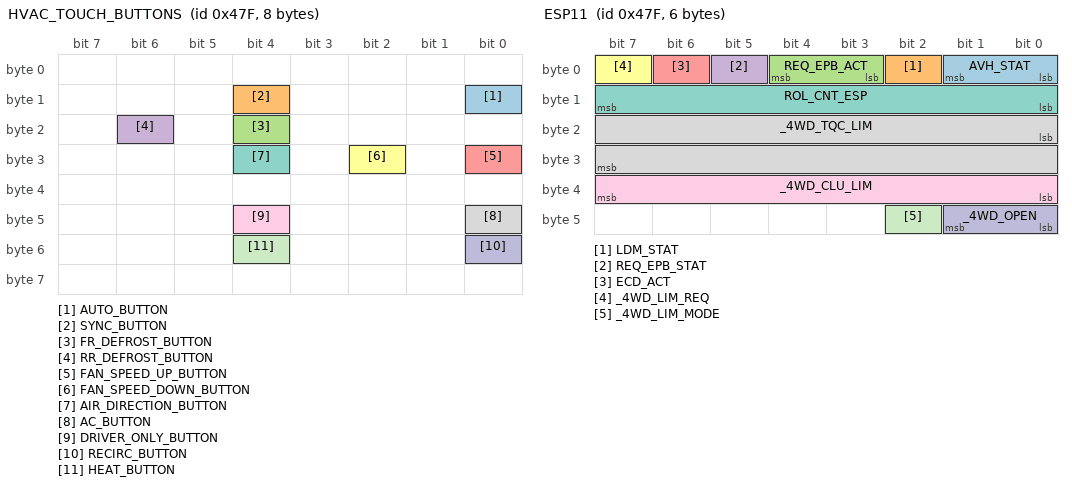
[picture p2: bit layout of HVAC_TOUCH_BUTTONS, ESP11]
BO_ 1151 HVAC_TOUCH_BUTTONS: 8 XXX
 SG_ AUTO_BUTTON : 8|1@0+ (1,0) [0|1] "" XXX
 SG_ SYNC_BUTTON : 12|1@0+ (1,0) [0|1] "" XXX
 SG_ FR_DEFROST_BUTTON : 20|1@0+ (1,0) [0|1] "" XXX
 SG_ RR_DEFROST_BUTTON : 22|1@0+ (1,0) [0|1] "" XXX
 SG_ FAN_SPEED_UP_BUTTON : 24|1@0+ (1,0) [0|1] "" XXX
 SG_ FAN_SPEED_DOWN_BUTTON : 26|1@0+ (1,0) [0|1] "" XXX
 SG_ AIR_DIRECTION_BUTTON : 28|1@0+ (1,0) [0|1] "" XXX
 SG_ AC_BUTTON : 40|1@0+ (1,0) [0|1] "" XXX
 SG_ DRIVER_ONLY_BUTTON : 44|1@0+ (1,0) [0|1] "" XXX
 SG_ RECIRC_BUTTON : 48|1@0+ (1,0) [0|1] "" XXX
 SG_ HEAT_BUTTON : 52|1@0+ (1,0) [0|1] "" XXX

BO_ 1259 LOCAL_TIME2: 8 XXX
 SG_ HOURS : 15|5@0+ (1,0) [0|31] "" XXX
 SG_ MINUTES : 21|6@0+ (1,0) [0|63] "" XXX
 SG_ SECONDS : 24|6@1+ (1,0) [0|63] "" XXX
 SG_ NEW_SIGNAL_3 : 39|1@0+ (1,0) [0|1] "" XXX

BO_ 1264 LOCAL_TIME: 8 XXX
 SG_ HOURS : 12|5@0+ (1,0) [0|31] "" XXX
 SG_ MINUTES : 21|6@0+ (1,0) [0|63] "" XXX
 SG_ SECONDS : 31|8@0+ (1,0) [0|59] "" XXX

CM_ 272 "Alternative LKAS message, used on cars such as 2023 Ioniq 6, 2nd gen Kona. Matches LKAS except size is 32 bytes";
VAL_TABLE_
 SIG_GROUP_
 SIG_VALTYPE_
 SIGTYPE_VALTYPE_
 BO_TX_BU_
 BA_DEF_REL_
 BA_REL_
 BA_DEF_DEF_REL_
 BU_SG_REL_
 BU_EV_REL_
 BU_BO_REL_
 SG_MUL_VAL_

BS_:

BU_: IAP ODS _4WD BCM HUD DATC MDPS AAF_Tester AEMC SMK _4WD EPB CUBIS MTS TMU EVP CGW TPMS LPI DI_BOX SPAS EMS LCA TCU IBOX FATC AFLS FPCM SCC AHLS AVM ABS SNV OPI PGS SAS AAF Dummy LDWS_LKAS LVR ESC PSB CLU ECS ACU REA

BO_ 387 REA11: 8 REA
 SG_ CF_EndBst_PwmDuH : 0|1@1+ (1.0,0.0) [0.0|1.0] ""  EMS
 SG_ CF_EndBst_PwmDuL : 1|1@1+ (1.0,0.0) [0.0|1.0] ""  EMS
 SG_ CF_EndBst_PwmFqOutRng : 2|1@1+ (1.0,0.0) [0.0|1.0] ""  EMS
 SG_ CF_EndBst_HbriOverCur : 3|1@1+ (1.0,0.0) [0.0|1.0] ""  EMS
 SG_ CF_EndBst_HbriOverTemp : 4|1@1+ (1.0,0.0) [0.0|1.0] ""  EMS
 SG_ CF_EndBst_PosSnsKOR : 6|1@1+ (1.0,0.0) [0.0|1.0] ""  EMS
 SG_ CF_EndBst_PosSnsOSOR : 7|1@1+ (1.0,0.0) [0.0|1.0] ""  EMS
 SG_ CF_EndBst_EepFlt : 8|1@1+ (1.0,0.0) [0.0|1.0] ""  EMS
 SG_ CF_EndBst_RomFlt : 9|1@1+ (1.0,0.0) [0.0|1.0] ""  EMS
 SG_ CF_EndBst_RamFlt : 10|1@1+ (1.0,0.0) [0.0|1.0] ""  EMS
 SG_ CF_EndBst_CanFlt : 11|1@1+ (1.0,0.0) [0.0|1.0] ""  EMS
 SG_ CF_EndBst_AgH : 12|1@1+ (1.0,0.0) [0.0|1.0] ""  EMS
 SG_ CF_EndBst_AgL : 13|1@1+ (1.0,0.0) [0.0|1.0] ""  EMS
 SG_ CF_EndBst_ORVol : 14|1@1+ (1.0,0.0) [0.0|1.0] ""  EMS
 SG_ CR_EndBst_ActPos : 16|16@1+ (0.117,0.0) [1.989|118.053] ""  EMS
 SG_ CR_EndBst_DemPos : 32|16@1+ (0.117,0.0) [0.0|119.691] ""  EMS
 SG_ CR_EndBst_HbriPwr : 48|16@1+ (0.045,0.0) [0.0|99.99] "%"  EMS

BO_ 1151 ESP11: 6 ESC
 SG_ AVH_STAT : 0|2@1+ (1.0,0.0) [0.0|3.0] ""  EMS,EPB,TCU
 SG_ LDM_STAT : 2|1@1+ (1.0,0.0) [0.0|1.0] ""  EPB,TCU
 SG_ REQ_EPB_ACT : 3|2@1+ (1.0,0.0) [0.0|3.0] ""  EPB,TCU
 SG_ REQ_EPB_STAT : 5|1@1+ (1.0,0.0) [0.0|1.0] ""  EPB
 SG_ ECD_ACT : 6|1@1+ (1.0,0.0) [0.0|1.0] ""  EPB
 SG_ _4WD_LIM_REQ : 7|1@1+ (1.0,0.0) [0.0|1.0] ""  _4WD,EMS
 SG_ ROL_CNT_ESP : 8|8@1+ (1.0,0.0) [0.0|255.0] ""  EPB,TCU
 SG_ _4WD_TQC_LIM : 16|16@1+ (1.0,0.0) [0.0|65535.0] "Nm"  _4WD,EMS
 SG_ _4WD_CLU_LIM : 32|8@1+ (0.390625,0.0) [0.0|99.609375] "%"  _4WD,EMS
 SG_ _4WD_OPEN : 40|2@1+ (1.0,0.0) [0.0|3.0] ""  _4WD,EMS
 SG_ _4WD_LIM_MODE : 42|1@1+ (1.0,0.0) [0.0|1.0] ""  _4WD

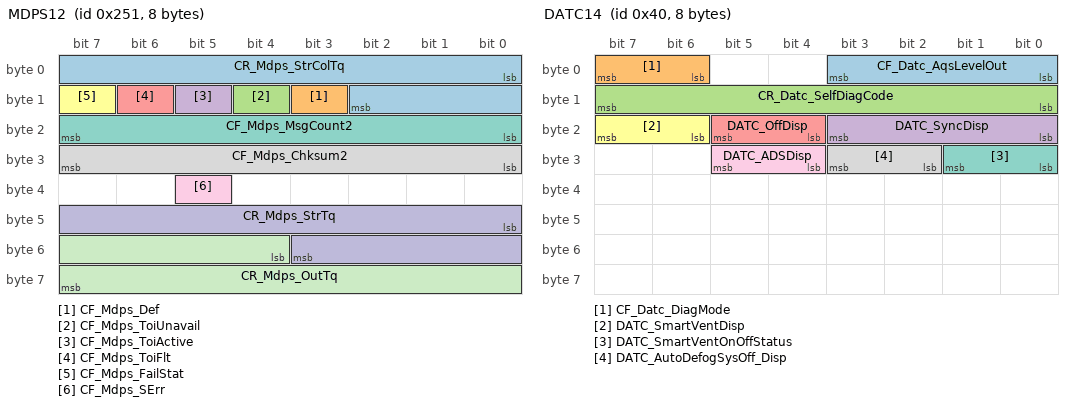
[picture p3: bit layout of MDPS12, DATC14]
BO_ 593 MDPS12: 8 MDPS
 SG_ CR_Mdps_StrColTq : 0|11@1+ (1.0,-1024.0) [-1024.0|1024.0] ""  LDWS_LKAS
 SG_ CF_Mdps_Def : 11|1@1+ (1.0,0.0) [0.0|1.0] ""  ESC
 SG_ CF_Mdps_ToiUnavail : 12|1@1+ (1.0,0.0) [0.0|1.0] ""  LDWS_LKAS
 SG_ CF_Mdps_ToiActive : 13|1@1+ (1.0,0.0) [0.0|1.0] ""  LDWS_LKAS
 SG_ CF_Mdps_ToiFlt : 14|1@1+ (1.0,0.0) [0.0|1.0] ""  LDWS_LKAS
 SG_ CF_Mdps_FailStat : 15|1@1+ (1.0,0.0) [0.0|1.0] ""  LDWS_LKAS
 SG_ CF_Mdps_MsgCount2 : 16|8@1+ (1.0,0.0) [0.0|255.0] ""  ESC,LDWS_LKAS
 SG_ CF_Mdps_Chksum2 : 24|8@1+ (1.0,0.0) [0.0|255.0] ""  ESC,LDWS_LKAS
 SG_ CF_Mdps_SErr : 37|1@1+ (1.0,0.0) [0.0|1.0] ""  ESC
 SG_ CR_Mdps_StrTq : 40|12@1+ (0.01,-20.48) [-20.48|20.47] "Nm"  ESC
 SG_ CR_Mdps_OutTq : 52|12@1+ (0.1,-204.8) [-204.8|204.7] ""  ESC,LDWS_LKAS

BO_ 64 DATC14: 8 DATC
 SG_ CF_Datc_AqsLevelOut : 0|4@1+ (1.0,0.0) [0.0|3.0] ""  CLU
 SG_ CF_Datc_DiagMode : 6|2@1+ (1.0,0.0) [0.0|3.0] ""  CLU
 SG_ CR_Datc_SelfDiagCode : 8|8@1+ (1.0,-1.0) [0.0|254.0] ""  CLU
 SG_ DATC_SyncDisp : 16|4@1+ (1.0,0.0) [0.0|3.0] ""  CLU
 SG_ DATC_OffDisp : 20|2@1+ (1.0,0.0) [0.0|3.0] ""  CLU
 SG_ DATC_SmartVentDisp : 22|2@1+ (1.0,0.0) [0.0|3.0] ""  CLU
 SG_ DATC_SmartVentOnOffStatus : 24|2@1+ (1.0,0.0) [0.0|3.0] ""  CLU
 SG_ DATC_AutoDefogSysOff_Disp : 26|2@1+ (1.0,0.0) [0.0|3.0] ""  CLU
 SG_ DATC_ADSDisp : 28|2@1+ (1.0,0.0) [0.0|3.0] ""  CLU

BO_ 512 EMS20: 6 EMS
 SG_ FCO : 0|16@1+ (0.128,0.0) [0.0|8388.48] "ul"  CLU,CUBIS,FPCM,IBOX
 SG_ CF_Ems_PumpTPres : 16|8@1+ (3.137254902,0.0) [0.0|800.0] "kPa"  FPCM,IBOX
 SG_ Split_Stat : 32|1@1+ (1.0,0.0) [0.0|1.0] ""  FPCM

BO_ 357 S_MDPS12: 8 XXX
 SG_ NEW_SIGNAL_1 : 0|12@1+ (1,0) [0|4095] "" XXX
 SG_ NEW_SIGNAL_2 : 12|12@1+ (1,0) [0|4095] "" XXX
 SG_ Counter : 48|4@1+ (1,0) [0|15] "" XXX
 SG_ Checksum : 63|8@0+ (1,0) [0|255] "" XXX

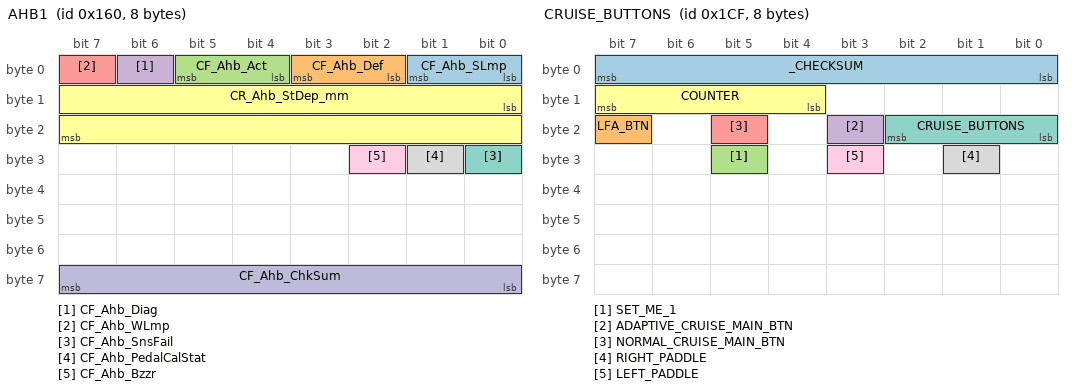
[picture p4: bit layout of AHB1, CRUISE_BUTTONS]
BO_ 352 AHB1: 8 iBAU
 SG_ CF_Ahb_SLmp : 0|2@1+ (1,0) [0|3] "" CLU
 SG_ CF_Ahb_Def : 2|2@1+ (1,0) [0|3] "" CGW
 SG_ CF_Ahb_Act : 4|2@1+ (1,0) [0|3] "" Vector__XXX
 SG_ CF_Ahb_Diag : 6|1@1+ (1,0) [0|1] "" Vector__XXX
 SG_ CF_Ahb_WLmp : 7|1@1+ (1,0) [0|1] "" CLU
 SG_ CR_Ahb_StDep_mm : 8|16@1- (0.1,0) [-3276.8|3276.7] "mm" Vector__XXX
 SG_ CF_Ahb_SnsFail : 24|1@1+ (1,0) [0|1] "" Vector__XXX
 SG_ CF_Ahb_PedalCalStat : 25|1@1+ (1,0) [0|1] "" Vector__XXX
 SG_ CF_Ahb_Bzzr : 26|1@1+ (1,0) [0|1] "" Vector__XXX
 SG_ CF_Ahb_ChkSum : 56|8@1+ (1,0) [0|255] "" Vector__XXX

BO_ 304 YRS11: 8 ACU
 SG_ CR_Yrs_Yr : 0|16@1+ (0.005,-163.84) [-163.84|163.83] "deg/s" CGW,iBAU
 SG_ CR_Yrs_LatAc : 16|16@1+ (0.000127465,-4.17677312) [-4.17677312|4.17651819] "g" iBAU
 SG_ CF_Yrs_YrStat : 32|4@1+ (1,0) [0|15] "" iBAU
 SG_ CF_Yrs_LatAcStat : 36|4@1+ (1,0) [0|15] "" iBAU
 SG_ CF_Yrs_MCUStat : 40|4@1+ (1,0) [0|15] "" iBAU
 SG_ CR_Yrs_MsgCnt1 : 48|4@1+ (1,0) [0|15] "" iBAU
 SG_ CR_Yrs_Crc1 : 56|8@1+ (1,0) [0|255] "" iBAU

CM_ "BO_ E_EMS11: All (plug-in) hybrids use this gas signal: CR_Vcu_AccPedDep_Pos, and all EVs use the Accel_Pedal_Pos signal. See hyundai/values.py for a specific car list";

BO_ 53 ACCELERATOR: 32 XXX
 SG_ CHECKSUM : 0|16@1+ (1,0) [0|65535] "" XXX
 SG_ COUNTER : 16|8@1+ (1,0) [0|255] "" XXX
 SG_ GEAR : 192|3@1+ (1,0) [0|7] "" XXX
 SG_ ACCELERATOR_PEDAL : 40|8@1+ (1,0) [0|255] "" XXX

BO_ 64 GEAR_ALT: 32 XXX
 SG_ CHECKSUM : 0|16@1+ (1,0) [0|65535] "" XXX
 SG_ COUNTER : 16|8@1+ (1,0) [0|255] "" XXX
 SG_ GEAR : 32|3@1+ (1,0) [0|7] "" XXX

BO_ 69 GEAR: 24 XXX
 SG_ CHECKSUM : 0|16@1+ (1,0) [0|65535] "" XXX
 SG_ COUNTER : 16|8@1+ (1,0) [0|255] "" XXX
 SG_ GEAR : 44|3@1+ (1,0) [0|7] "" XXX

BO_ 80 LKAS: 16 XXX
 SG_ STEER_REQ : 52|1@1+ (1,0) [0|1] "" XXX
 SG_ TORQUE_REQUEST : 41|11@1+ (1,-1024) [0|4095] "" XXX
 SG_ LKA_ICON : 38|2@1+ (1,0) [0|255] "" XXX
 SG_ NEW_SIGNAL_1 : 27|2@1+ (1,0) [0|255] "" XXX
 SG_ LFA_BUTTON : 56|1@1+ (1,0) [0|255] "" XXX
 SG_ COUNTER : 16|8@1+ (1,0) [0|255] "" XXX
 SG_ CHECKSUM : 0|16@1+ (1,0) [0|65535] "" XXX
 SG_ STEER_MODE : 65|3@1+ (1,0) [0|1] "" XXX
 SG_ LKA_WARNING : 32|1@1+ (1,0) [0|1] "" XXX
 SG_ LKA_ASSIST : 62|1@1+ (1,0) [0|1] "" XXX
 SG_ LKA_MODE : 24|3@1+ (1,0) [0|7] "" XXX
 SG_ NEW_SIGNAL_2 : 70|2@0+ (1,0) [0|3] "" XXX
 SG_ HAS_LANE_SAFETY : 80|1@0+ (1,0) [0|1] "" XXX
 SG_ NEW_SIGNAL_3 : 111|8@0+ (1,0) [0|255] "" XXX
 SG_ FCA_SYSWARN : 40|1@0+ (1,0) [0|1] "" XXX

BO_ 81 ADRV_0x51: 32 ADRV
 SG_ COUNTER : 16|8@1+ (1,0) [0|255] "" XXX
 SG_ CHECKSUM : 0|16@1+ (1,0) [0|65535] "" XXX

BO_ 96 ESP_STATUS: 32 XXX
 SG_ CHECKSUM : 0|16@1+ (1,0) [0|65535] "" XXX
 SG_ COUNTER : 16|8@1+ (1,0) [0|255] "" XXX
 SG_ TRACTION_AND_STABILITY_CONTROL : 42|3@1+ (1,0) [0|63] "" XXX
 SG_ BRAKE_PRESSURE : 128|10@1+ (1,0) [0|65535] "" XXX
 SG_ BRAKE_PRESSED : 148|1@1+ (1,0) [0|3] "" XXX

BO_ 101 BRAKE: 32 XXX
 SG_ CHECKSUM : 0|16@1+ (1,0) [0|65535] "" XXX
 SG_ COUNTER : 16|8@1+ (1,0) [0|255] "" XXX
 SG_ BRAKE_POSITION : 40|16@1- (1,0) [0|65535] "" XXX
 SG_ BRAKE_PRESSED : 57|1@1+ (1,0) [0|3] "" XXX

BO_ 112 GEAR_ALT_2: 32 XXX
 SG_ CHECKSUM : 0|16@1+ (1,0) [0|65535] "" XXX
 SG_ COUNTER : 16|8@1+ (1,0) [0|255] "" XXX
 SG_ GEAR : 60|3@1+ (1,0) [0|7] "" XXX

BO_ 160 WHEEL_SPEEDS: 24 XXX
 SG_ CHECKSUM : 0|16@1+ (1,0) [0|65535] "" XXX
 SG_ COUNTER : 16|8@1+ (1,0) [0|255] "" XXX
 SG_ MOVING_FORWARD : 56|1@0+ (1,0) [0|1] "" XXX
 SG_ MOVING_BACKWARD : 57|1@0+ (1,0) [0|1] "" XXX
 SG_ MOVING_FORWARD2 : 58|1@0+ (1,0) [0|1] "" XXX
 SG_ MOVING_BACKWARD2 : 59|1@0+ (1,0) [0|1] "" XXX
 SG_ WHEEL_SPEED_1 : 64|16@1+ (0.03125,0) [0|65535] "kph" XXX
 SG_ WHEEL_SPEED_2 : 80|16@1+ (0.03125,0) [0|65535] "kph" XXX
 SG_ WHEEL_SPEED_3 : 96|16@1+ (0.03125,0) [0|65535] "kph" XXX
 SG_ WHEEL_SPEED_4 : 112|16@1+ (0.03125,0) [0|65535] "kph" XXX

BO_ 234 MDPS: 24 XXX
 SG_ CHECKSUM : 0|16@1+ (1,0) [0|65535] "" XXX
 SG_ COUNTER : 16|8@1+ (1,0) [0|255] "" XXX
 SG_ LKA_ACTIVE : 48|1@0+ (1,0) [0|16777215] "" XXX
 SG_ LKA_FAULT : 54|1@0+ (1,0) [0|1] "" XXX
 SG_ STEERING_OUT_TORQUE : 64|12@1+ (0.1,-204.8) [0|65535] "" XXX
 SG_ STEERING_COL_TORQUE : 80|13@1+ (1,-4095) [0|4095] "" XXX
 SG_ STEERING_ANGLE : 96|16@1- (-0.1,0) [0|255] "deg" XXX
 SG_ STEERING_ANGLE_2 : 128|16@1- (-0.1,0) [0|65535] "deg" XXX

BO_ 256 RADAR_POINTS_METADATA_0x100: 64 RADAR
 SG_ SIGNAL_1 : 0|32@1+ (1,0) [0|255] "" XXX
 SG_ SIGNAL_2 : 32|32@1+ (1,0) [0|65535] "" XXX
 SG_ SIGNAL_3 : 64|4@1+ (1,0) [0|15] "" XXX
 SG_ SIGNAL_4 : 68|4@1+ (1,0) [0|15] "" XXX
 SG_ RADAR_POINT_COUNT : 72|8@1+ (1,0) [0|255] "" XXX
 SG_ SIGNAL_6 : 80|7@1+ (0.015625,0) [0|3] "" XXX
 SG_ SIGNAL_7 : 87|1@1+ (1,0) [0|1] "" XXX
 SG_ SIGNAL_8 : 88|3@1+ (1,0) [0|7] "" XXX
 SG_ SIGNAL_9 : 91|5@1+ (0.0625,0) [0|31] "" XXX
 SG_ SIGNAL_10 : 96|8@1+ (1,0) [0|255] "" XXX
 SG_ SIGNAL_11 : 104|7@1+ (0.015625,0) [0|127] "" XXX
 SG_ SIGNAL_12 : 111|2@1+ (1,0) [0|65535] "" XXX
 SG_ SIGNAL_13 : 113|7@1+ (0.015625,0) [0|127] "" XXX
 SG_ SIGNAL_14 : 120|7@1+ (0.015625,0) [0|127] "" XXX
 SG_ SIGNAL_15 : 127|3@1+ (1,0) [0|3] "" XXX
 SG_ SIGNAL_16 : 130|2@1+ (1,0) [0|3] "" XXX
 SG_ SIGNAL_17 : 133|2@0+ (1,0) [0|3] "" XXX
 SG_ SIGNAL_18 : 134|1@0+ (1,0) [0|3] "" XXX
 SG_ SIGNAL_19 : 135|3@1+ (1,0) [0|3] "" XXX
 SG_ SIGNAL_20 : 138|8@1+ (1,0) [0|63] "" XXX
 SG_ SIGNAL_21 : 146|2@1+ (1,0) [0|3] "" XXX
 SG_ SIGNAL_22 : 148|1@1+ (1,0) [0|3] "" XXX
 SG_ SIGNAL_23 : 149|4@1+ (1,0) [0|7] "" XXX
 SG_ SIGNAL_24 : 153|1@1+ (1,0) [0|3] "" XXX
 SG_ SIGNAL_25 : 154|2@1+ (1,0) [0|3] "" XXX
 SG_ SIGNAL_26 : 157|2@0+ (1,0) [0|3] "" XXX
 SG_ SIGNAL_27 : 158|7@1+ (0.125,0) [0|3] "" XXX
 SG_ SIGNAL_28 : 165|7@1+ (0.015625,0) [0|31] "" XXX
 SG_ SIGNAL_29 : 172|7@1+ (0.125,0) [0|3] "" XXX
 SG_ SIGNAL_30 : 179|7@1+ (0.015625,0) [0|1] "" XXX
 SG_ SIGNAL_31 : 186|4@1+ (1,0) [0|7] "" XXX
 SG_ SIGNAL_32 : 190|14@1+ (0.015625,0) [0|15] "" XXX
 SG_ SIGNAL_33 : 204|11@1+ (0.03125,0) [0|8191] "" XXX
 SG_ SIGNAL_34 : 215|2@1+ (1,0) [0|3] "" XXX
 SG_ SIGNAL_35 : 217|7@1+ (1,0) [0|127] "" XXX
 SG_ SIGNAL_36 : 224|6@1+ (1,0) [0|63] "" XXX
 SG_ SIGNAL_37 : 230|6@1+ (0.2,0) [0|31] "" XXX
 SG_ SIGNAL_38 : 236|6@1+ (0.2,0) [0|7] "" XXX
 SG_ SIGNAL_39 : 242|8@1+ (1,-90) [0|255] "" XXX
 SG_ SIGNAL_40 : 250|6@1+ (1,0) [0|63] "" XXX
 SG_ SIGNAL_41 : 256|8@1+ (0.25,0) [0|255] "" XXX
 SG_ SIGNAL_42 : 264|3@1+ (1,0) [0|3] "" XXX
 SG_ SIGNAL_43 : 267|12@1+ (0.01,0) [0|31] "" XXX
 SG_ SIGNAL_44 : 279|32@1+ (1,0) [0|63] "" XXX
 SG_ SIGNAL_45 : 311|1@1+ (1,0) [0|1] "" XXX
 SG_ SIGNAL_46 : 312|2@1+ (1,0) [0|3] "" XXX
 SG_ SIGNAL_47 : 314|32@1+ (1,0) [0|255] "" XXX
 SG_ SIGNAL_48 : 346|6@1+ (1,0) [0|63] "" XXX
 SG_ SIGNAL_49 : 352|7@1+ (0.25,0) [0|127] "" XXX
 SG_ SIGNAL_50 : 359|6@1+ (0.03125,0) [0|31] "" XXX
 SG_ SIGNAL_51 : 365|10@1+ (0.125,0) [0|3] "" XXX
 SG_ SIGNAL_52 : 375|10@1+ (0.125,0) [0|63] "" XXX
 SG_ SIGNAL_53 : 385|7@1+ (1,0) [0|127] "" XXX
 SG_ SIGNAL_54 : 392|7@1+ (1,0) [0|127] "" XXX
 SG_ SIGNAL_55 : 399|8@1+ (0.00390625,0) [0|31] "" XXX
 SG_ SIGNAL_56 : 407|10@1+ (0.125,0) [0|63] "" XXX
 SG_ SIGNAL_57 : 417|1@1+ (1,0) [0|3] "" XXX
 SG_ SIGNAL_58 : 418|1@1+ (1,0) [0|3] "" XXX

BO_ 261 ACCELERATOR_ALT: 32 XXX
 SG_ CHECKSUM : 0|16@1+ (1,0) [0|65535] "" XXX
 SG_ COUNTER : 16|8@1+ (1,0) [0|255] "" XXX
 SG_ ACCELERATOR_PEDAL : 103|10@1+ (0.25,0) [0|1022] "" XXX

BO_ 272 LKAS_ALT: 32 XXX
 SG_ STEER_REQ : 52|1@1+ (1,0) [0|1] "" XXX
 SG_ TORQUE_REQUEST : 41|11@1+ (1,-1024) [0|4095] "" XXX
 SG_ LKA_ICON : 38|2@1+ (1,0) [0|255] "" XXX
 SG_ NEW_SIGNAL_1 : 27|2@1+ (1,0) [0|255] "" XXX
 SG_ LFA_BUTTON : 56|1@1+ (1,0) [0|255] "" XXX
 SG_ COUNTER : 16|8@1+ (1,0) [0|255] "" XXX
 SG_ CHECKSUM : 0|16@1+ (1,0) [0|65535] "" XXX
 SG_ STEER_MODE : 65|3@1+ (1,0) [0|1] "" XXX
 SG_ LKA_WARNING : 32|1@1+ (1,0) [0|1] "" XXX
 SG_ LKA_ASSIST : 62|1@1+ (1,0) [0|1] "" XXX
 SG_ LKA_MODE : 24|3@1+ (1,0) [0|7] "" XXX
 SG_ NEW_SIGNAL_2 : 70|2@0+ (1,0) [0|3] "" XXX
 SG_ HAS_LANE_SAFETY : 80|1@0+ (1,0) [0|1] "" XXX
 SG_ NEW_SIGNAL_3 : 111|8@0+ (1,0) [0|255] "" XXX
 SG_ FCA_SYSWARN : 40|1@0+ (1,0) [0|1] "" XXX

BO_ 293 STEERING_SENSORS: 16 XXX
 SG_ CHECKSUM : 0|16@1+ (1,0) [0|65535] "" XXX
 SG_ COUNTER : 16|8@1+ (1,0) [0|255] "" XXX
 SG_ STEERING_RATE : 40|8@1+ (4,0) [0|1016] "deg/s" XXX
 SG_ STEERING_ANGLE : 24|16@1- (-0.1,0) [0|255] "deg" XXX

BO_ 298 LFA: 16 ADRV
 SG_ STEER_REQ : 52|1@1+ (1,0) [0|1] "" XXX
 SG_ TORQUE_REQUEST : 41|11@1+ (1,-1024) [0|4095] "" XXX
 SG_ LKA_ICON : 38|2@1+ (1,0) [0|255] "" XXX
 SG_ NEW_SIGNAL_1 : 27|2@1+ (1,0) [0|255] "" XXX
 SG_ LFA_BUTTON : 56|1@1+ (1,0) [0|255] "" XXX
 SG_ COUNTER : 16|8@1+ (1,0) [0|255] "" XXX
 SG_ CHECKSUM : 0|16@1+ (1,0) [0|65535] "" XXX
 SG_ STEER_MODE : 65|3@1+ (1,0) [0|1] "" XXX
 SG_ LKA_WARNING : 32|1@1+ (1,0) [0|1] "" XXX
 SG_ LKA_ASSIST : 62|1@1+ (1,0) [0|1] "" XXX
 SG_ LKA_MODE : 24|3@1+ (1,0) [0|7] "" XXX
 SG_ NEW_SIGNAL_2 : 70|2@0+ (1,0) [0|3] "" XXX
 SG_ HAS_LANE_SAFETY : 80|1@0+ (1,0) [0|1] "" XXX
 SG_ NEW_SIGNAL_3 : 111|8@0+ (1,0) [0|255] "" XXX

BO_ 304 GEAR_SHIFTER: 16 XXX
 SG_ CHECKSUM : 0|16@1+ (1,0) [0|65535] "" XXX
 SG_ COUNTER : 16|8@1+ (1,0) [0|255] "" XXX
 SG_ PARK_BUTTON : 32|2@1+ (1,0) [0|3] "" XXX
 SG_ GEAR : 64|3@1+ (1,0) [0|7] "" XXX
 SG_ KNOB_POSITION : 40|3@1+ (1,0) [0|3] "" XXX

BO_ 352 ADRV_0x160: 16 ADRV
 SG_ CHECKSUM : 0|16@1+ (1,0) [0|65535] "" XXX
 SG_ COUNTER : 16|8@1+ (1,0) [0|255] "" XXX
 SG_ SET_ME_FF : 64|8@1+ (1,0) [0|255] "" XXX
 SG_ SET_ME_FC : 72|8@1+ (1,0) [0|255] "" XXX
 SG_ SET_ME_2 : 56|8@1+ (1,0) [0|1] "" XXX
 SG_ AEB_SETTING : 24|2@1+ (1,0) [0|255] "" XXX
 SG_ SET_ME_9 : 80|8@1+ (1,0) [0|255] "" XXX

BO_ 357 SPAS1: 24 APRK
 SG_ CHECKSUM : 0|16@1+ (1,0) [0|65535] "" XXX
 SG_ COUNTER : 16|8@1+ (1,0) [0|0] "" XXX
 SG_ NEW_SIGNAL_1 : 96|16@1- (0.1,0) [0|0] "" XXX
 SG_ NEW_SIGNAL_2 : 90|3@1+ (1,0) [0|0] "" XXX

BO_ 362 SPAS2: 32 APRK
 SG_ CHECKSUM : 0|16@1+ (1,0) [0|65535] "" XXX
 SG_ COUNTER : 16|8@1+ (1,0) [0|0] "" XXX
 SG_ BLINKER_CONTROL : 133|3@1+ (1,0) [0|0] "" XXX

BO_ 373 TCS: 24 XXX
 SG_ CHECKSUM : 0|16@1+ (1,0) [0|65535] "" XXX
 SG_ COUNTER : 16|8@1+ (1,0) [0|255] "" XXX
 SG_ NEW_SIGNAL_1 : 80|1@0+ (1,0) [0|1] "" XXX
 SG_ NEW_SIGNAL_2 : 74|1@0+ (1,0) [0|1] "" XXX
 SG_ NEW_SIGNAL_3 : 76|1@0+ (1,0) [0|1] "" XXX
 SG_ NEW_SIGNAL_4 : 24|7@1+ (1,0) [0|127] "" XXX
 SG_ aBasis : 32|11@1+ (0.01,-10.23) [0|7] "m/s^2" XXX
 SG_ NEW_SIGNAL_5 : 72|1@0+ (1,0) [0|1] "" XXX
 SG_ NEW_SIGNAL_6 : 128|4@1+ (1,0) [0|15] "" XXX
 SG_ NEW_SIGNAL_7 : 135|2@0+ (1,0) [0|3] "" XXX
 SG_ PROBABLY_EQUIP : 136|2@1+ (1,0) [0|3] "" XXX
 SG_ AEB_EQUIP_MAYBE : 96|1@0+ (1,0) [0|1] "" XXX
 SG_ EQUIP_MAYBE : 64|1@0+ (1,0) [0|1] "" XXX
 SG_ DriverBraking : 81|1@0+ (1,0) [0|1] "" XXX
 SG_ DriverBrakingLowSens : 84|1@1+ (1,0) [0|1] "" XXX
 SG_ ACC_REQ : 68|1@0+ (1,0) [0|1] "" XXX
 SG_ ACCEL_REF_ACC : 48|11@1- (1,0) [0|1023] "" XXX
 SG_ ACCEnable : 67|2@0+ (1,0) [0|3] "" XXX

BO_ 384 CAM_0x180: 32 CAMERA
 SG_ CHECKSUM : 0|16@1+ (1,0) [0|65535] "" XXX
 SG_ COUNTER : 16|8@1+ (1,0) [0|255] "" XXX

BO_ 385 CAM_0x181: 32 CAMERA
 SG_ CHECKSUM : 0|16@1+ (1,0) [0|65535] "" XXX
 SG_ COUNTER : 16|8@1+ (1,0) [0|255] "" XXX

BO_ 386 CAM_0x182: 32 CAMERA
 SG_ CHECKSUM : 0|16@1+ (1,0) [0|65535] "" XXX
 SG_ COUNTER : 16|8@1+ (1,0) [0|255] "" XXX

BO_ 387 CAM_0x183: 32 CAMERA
 SG_ CHECKSUM : 0|16@1+ (1,0) [0|65535] "" XXX
 SG_ COUNTER : 16|8@1+ (1,0) [0|255] "" XXX

BO_ 388 CAM_0x184: 32 CAMERA
 SG_ CHECKSUM : 0|16@1+ (1,0) [0|65535] "" XXX
 SG_ COUNTER : 16|8@1+ (1,0) [0|255] "" XXX

BO_ 389 CAM_0x185: 8 CAMERA
 SG_ CHECKSUM : 0|16@1+ (1,0) [0|65535] "" XXX
 SG_ COUNTER : 16|8@1+ (1,0) [0|255] "" XXX

BO_ 416 SCC_CONTROL: 32 ADRV
 SG_ CHECKSUM : 0|16@1+ (1,0) [0|65535] "" XXX
 SG_ NEW_SIGNAL_1 : 64|2@1+ (1,0) [0|3] "" XXX
 SG_ NEW_SIGNAL_8 : 170|4@1+ (1,0) [0|15] "" XXX
 SG_ ZEROS : 215|48@0+ (1,0) [0|281474976710655] "" XXX
 SG_ ZEROS_3 : 191|7@0+ (1,0) [0|127] "" XXX
 SG_ ZEROS_4 : 183|4@0+ (1,0) [0|63] "" XXX
 SG_ ZEROS_6 : 119|16@0+ (1,0) [0|65535] "" XXX
 SG_ ZEROS_8 : 95|5@0+ (1,0) [0|31] "" XXX
 SG_ NEW_SIGNAL_3 : 109|2@0+ (1,0) [0|1] "" XXX
 SG_ SET_ME_TMP_64 : 55|8@0+ (1,0) [0|63] "" XXX
 SG_ SET_ME_2 : 105|3@1+ (1,0) [0|7] "" XXX
 SG_ NEW_SIGNAL_6 : 104|1@0+ (1,0) [0|1] "" XXX
 SG_ COUNTER : 16|8@1+ (1,0) [0|255] "" XXX
 SG_ ZEROS_9 : 71|5@1+ (1,0) [0|15] "" XXX
 SG_ ZEROS_10 : 111|2@0+ (1,0) [0|3] "" XXX
 SG_ SET_ME_3 : 45|2@0+ (1,0) [0|3] "" XXX
 SG_ ObjValid : 46|1@0+ (1,0) [0|3] "" XXX
 SG_ NEW_SIGNAL_2 : 168|2@1+ (1,0) [0|3] "" XXX
 SG_ OBJ_STATUS : 176|3@1+ (1,0) [0|7] "" XXX
 SG_ ACC_ObjDist : 24|11@1+ (0.1,0) [0|204.7] "m" XXX
 SG_ ZEROS_5 : 77|11@1+ (1,0) [0|2047] "" XXX
 SG_ DISTANCE_SETTING : 88|3@1+ (1,0) [0|3] "" XXX
 SG_ ZEROS_2 : 207|5@0+ (1,0) [0|63] "" XXX
 SG_ CRUISE_STANDSTILL : 76|1@1+ (1,0) [0|1] "" XXX
 SG_ aReqRaw : 140|11@1+ (0.01,-10.23) [-10.23|10.24] "m/s^2" XXX
 SG_ aReqValue : 128|11@1+ (0.01,-10.23) [-10.23|10.24] "m/s^2" XXX
 SG_ ZEROS_7 : 63|8@0+ (1,0) [0|255] "" XXX
 SG_ ACCMode : 68|3@1+ (1,0) [0|7] "" XXX
 SG_ ACC_ObjRelSpd : 35|9@1+ (0.1,-16.4) [-16.4|34.7] "m/s" XXX
 SG_ JerkLowerLimit : 166|7@0+ (0.1,0) [0|12.7] "m/s^3" XXX
 SG_ StopReq : 184|1@0+ (1,0) [0|1] "" XXX
 SG_ NEW_SIGNAL_15 : 192|11@1+ (0.1,0) [0|204.7] "m" XXX
 SG_ VSetDis : 103|8@0+ (1,0) [0|255] "km/h or mph" XXX
 SG_ MainMode_ACC : 66|1@1+ (1,0) [0|1] "" XXX
 SG_ JerkUpperLimit : 158|7@0+ (0.1,0) [0|0] "" XXX

BO_ 426 CRUISE_BUTTONS_ALT: 16 XXX
 SG_ CHECKSUM : 0|16@1+ (1,0) [0|65535] "" XXX
 SG_ COUNTER : 16|8@1+ (1,0) [0|255] "" XXX
 SG_ NEW_SIGNAL_1 : 24|4@1+ (1,0) [0|15] "" XXX
 SG_ SET_ME_1 : 28|2@1+ (1,0) [0|3] "" XXX
 SG_ DISTANCE_UNIT : 30|1@1+ (1,0) [0|1] "" XXX
 SG_ NEW_SIGNAL_2 : 31|3@1+ (1,0) [0|7] "" XXX
 SG_ ADAPTIVE_CRUISE_MAIN_BTN : 34|1@1+ (1,0) [0|1] "" XXX
 SG_ NEW_SIGNAL_3 : 35|1@1+ (1,0) [0|1] "" XXX
 SG_ LFA_BTN : 39|1@1+ (1,0) [0|1] "" XXX
 SG_ CRUISE_BUTTONS : 36|3@1+ (1,0) [0|4] "" XXX
 SG_ NEW_SIGNAL_4 : 40|1@1+ (1,0) [0|1] "" XXX
 SG_ NORMAL_CRUISE_MAIN_BTN : 41|1@1+ (1,0) [0|1] "" XXX
 SG_ NEW_SIGNAL_5 : 42|2@1+ (1,0) [0|3] "" XXX
 SG_ SET_ME_2 : 44|3@1+ (1,0) [0|7] "" XXX
 SG_ NEW_SIGNAL_6 : 47|1@1+ (1,0) [0|1] "" XXX
 SG_ BYTE6 : 48|8@1+ (1,0) [0|255] "" XXX
 SG_ BYTE7 : 56|8@1+ (1,0) [0|255] "" XXX
 SG_ BYTE8 : 64|8@1+ (1,0) [0|255] "" XXX
 SG_ BYTE9 : 72|8@1+ (1,0) [0|255] "" XXX
 SG_ BYTE10 : 80|8@1+ (1,0) [0|255] "" XXX
 SG_ BYTE11 : 88|8@1+ (1,0) [0|255] "" XXX
 SG_ BYTE12 : 96|8@1+ (1,0) [0|255] "" XXX
 SG_ BYTE13 : 104|8@1+ (1,0) [0|255] "" XXX
 SG_ BYTE14 : 112|8@1+ (1,0) [0|255] "" XXX
 SG_ BYTE15 : 120|8@1+ (1,0) [0|255] "" XXX

BO_ 438 CAM_0x1b6: 32 CAMERA
 SG_ CHECKSUM : 0|16@1+ (1,0) [0|65535] "" XXX
 SG_ COUNTER : 16|8@1+ (1,0) [0|255] "" XXX

BO_ 439 CAM_0x1b7: 32 CAMERA
 SG_ CHECKSUM : 0|16@1+ (1,0) [0|65535] "" XXX
 SG_ COUNTER : 16|8@1+ (1,0) [0|255] "" XXX

BO_ 440 CAM_0x1b8: 32 CAMERA
 SG_ CHECKSUM : 0|16@1+ (1,0) [0|65535] "" XXX
 SG_ COUNTER : 16|8@1+ (1,0) [0|255] "" XXX

BO_ 441 CAM_0x1b9: 32 CAMERA
 SG_ CHECKSUM : 0|16@1+ (1,0) [0|65535] "" XXX
 SG_ COUNTER : 16|8@1+ (1,0) [0|255] "" XXX

BO_ 442 BLINDSPOTS_REAR_CORNERS: 24 XXX
 SG_ COUNTER : 16|8@1+ (1,0) [0|255] "" XXX
 SG_ CHECKSUM : 0|16@1+ (1,0) [0|65535] "" XXX
 SG_ NEW_SIGNAL_2 : 96|1@0+ (1,0) [0|1] "" XXX
 SG_ COLLISION_AVOIDANCE_ACTIVE : 68|1@0+ (1,0) [0|1] "" XXX
 SG_ LEFT_MB : 30|1@0+ (1,0) [0|3] "" XXX
 SG_ LEFT_BLOCKED : 24|1@0+ (1,0) [0|1] "" XXX
 SG_ MORE_LEFT_PROB : 32|1@1+ (1,0) [0|3] "" XXX
 SG_ FL_INDICATOR : 46|6@0+ (1,0) [0|1] "" XXX
 SG_ FR_INDICATOR : 54|6@0+ (1,0) [0|63] "" XXX
 SG_ RIGHT_BLOCKED : 64|1@0+ (1,0) [0|1] "" XXX
 SG_ FL_INDICATOR_ALT : 138|1@0+ (1,0) [0|1] "" XXX
 SG_ FR_INDICATOR_ALT : 141|1@0+ (1,0) [0|1] "" XXX

BO_ 463 CRUISE_BUTTONS: 8 XXX
 SG_ _CHECKSUM : 0|8@1+ (1,0) [0|65535] "" XXX
 SG_ LFA_BTN : 23|1@1+ (1,0) [0|1] "" XXX
 SG_ SET_ME_1 : 29|1@1+ (1,0) [0|1] "" XXX
 SG_ ADAPTIVE_CRUISE_MAIN_BTN : 19|1@1+ (1,0) [0|1] "" XXX
 SG_ NORMAL_CRUISE_MAIN_BTN : 21|1@1+ (1,0) [0|1] "" XXX
 SG_ COUNTER : 12|4@1+ (1,0) [0|255] "" XXX
 SG_ CRUISE_BUTTONS : 16|3@1+ (1,0) [0|3] "" XXX
 SG_ RIGHT_PADDLE : 25|1@1+ (1,0) [0|1] "" XXX
 SG_ LEFT_PADDLE : 27|1@1+ (1,0) [0|1] "" XXX

BO_ 474 ADRV_0x1da: 32 ADRV
 SG_ CHECKSUM : 0|16@1+ (1,0) [0|65535] "" XXX
 SG_ COUNTER : 16|8@1+ (1,0) [0|255] "" XXX
 SG_ SET_ME_22 : 31|8@0+ (1,0) [0|255] "" XXX
 SG_ SET_ME_41 : 47|8@0+ (1,0) [0|255] "" XXX

BO_ 480 LFAHDA_CLUSTER: 16 ADRV
 SG_ CHECKSUM : 0|16@1+ (1,0) [0|65535] "" XXX
 SG_ COUNTER : 16|8@1+ (1,0) [0|255] "" XXX
 SG_ HDA_ICON : 31|1@1+ (1,0) [0|1] "" XXX
 SG_ LFA_ICON : 47|2@1+ (1,0) [0|3] "" XXX
 SG_ NEW_SIGNAL_1 : 32|3@1+ (1,0) [0|7] "" XXX
 SG_ NEW_SIGNAL_2 : 30|1@0+ (1,0) [0|1] "" XXX
 SG_ NEW_SIGNAL_3 : 49|1@0+ (1,0) [0|1] "" XXX
 SG_ NEW_SIGNAL_4 : 24|1@0+ (1,0) [0|1] "" XXX

BO_ 485 BLINDSPOTS_FRONT_CORNER_1: 16 XXX
 SG_ COUNTER : 16|8@1+ (1,0) [0|255] "" XXX
 SG_ CHECKSUM : 0|16@1+ (1,0) [0|65535] "" XXX
 SG_ NEW_SIGNAL_1 : 108|2@0+ (1,0) [0|3] "" XXX
 SG_ NEW_SIGNAL_2 : 96|1@0+ (1,0) [0|1] "" XXX
 SG_ NEW_SIGNAL_3 : 88|1@0+ (1,0) [0|1] "" XXX
 SG_ NEW_SIGNAL_4 : 80|1@0+ (1,0) [0|1] "" XXX
 SG_ NEW_SIGNAL_5 : 31|2@0+ (1,0) [0|3] "" XXX
 SG_ REVERSING : 24|1@0+ (1,0) [0|1] "" XXX
 SG_ NEW_SIGNAL_7 : 32|2@1+ (1,0) [0|3] "" XXX
 SG_ NEW_SIGNAL_8 : 47|8@0+ (1,0) [0|255] "" XXX
 SG_ NEW_SIGNAL_9 : 55|8@0+ (1,0) [0|255] "" XXX

BO_ 490 ADRV_0x1ea: 32 ADRV
 SG_ CHECKSUM : 0|16@1+ (1,0) [0|65535] "" XXX
 SG_ COUNTER : 16|8@1+ (1,0) [0|255] "" XXX
 SG_ SET_ME_1C : 31|8@0+ (1,0) [0|255] "" XXX
 SG_ NEW_SIGNAL_1 : 32|2@1+ (1,0) [0|3] "" XXX
 SG_ NEW_SIGNAL_2 : 47|2@0+ (1,0) [0|3] "" XXX
 SG_ NEW_SIGNAL_3 : 55|8@0+ (1,0) [0|255] "" XXX
 SG_ NEW_SIGNAL_4 : 64|6@1+ (1,0) [0|31] "" XXX
 SG_ NEW_SIGNAL_5 : 72|2@1+ (1,0) [0|3] "" XXX
 SG_ NEW_SIGNAL_6 : 75|5@1+ (1,0) [0|31] "" XXX
 SG_ NEW_SIGNAL_7 : 80|5@1+ (1,0) [0|31] "" XXX
 SG_ NEW_SIGNAL_8 : 88|7@1+ (1,0) [0|127] "" XXX
 SG_ NEW_SIGNAL_9 : 96|1@0+ (1,0) [0|1] "" XXX
 SG_ NEW_SIGNAL_10 : 143|5@0+ (1,0) [0|31] "" XXX
 SG_ NEW_SIGNAL_11 : 144|3@1+ (1,0) [0|7] "" XXX
 SG_ NEW_SIGNAL_12 : 152|6@1+ (1,0) [0|63] "" XXX
 SG_ NEW_SIGNAL_13 : 160|1@0+ (1,0) [0|1] "" XXX
 SG_ NEW_SIGNAL_14 : 163|5@1+ (1,0) [0|31] "" XXX
 SG_ NEW_SIGNAL_15 : 175|4@0+ (1,0) [0|63] "" XXX
 SG_ NEW_SIGNAL_16 : 168|3@1+ (1,0) [0|7] "" XXX
 SG_ NEW_SIGNAL_17 : 176|2@1+ (1,0) [0|3] "" XXX
 SG_ NEW_SIGNAL_18 : 184|1@0+ (1,0) [0|1] "" XXX
 SG_ NEW_SIGNAL_19 : 208|3@1+ (1,0) [0|7] "" XXX
 SG_ NEW_SIGNAL_20 : 212|1@0+ (1,0) [0|1] "" XXX
 SG_ SET_ME_FF : 120|8@1+ (1,0) [0|255] "" XXX
 SG_ SET_ME_TMP_F : 232|5@1+ (1,0) [0|31] "" XXX
 SG_ SET_ME_TMP_F_2 : 240|5@1+ (1,0) [0|31] "" XXX

BO_ 506 CLUSTER_SPEED_LIMIT: 32 XXX
 SG_ SPEED_LIMIT_3 : 119|8@0+ (1,0) [0|255] "" XXX
 SG_ SPEED_LIMIT_2 : 47|7@0+ (1,0) [0|255] "" XXX
 SG_ SPEED_LIMIT_1 : 39|7@0+ (1,0) [0|255] "" XXX
 SG_ SPEED_CHANGE_BLINKING : 129|1@1+ (1,0) [0|3] "" XXX
 SG_ CHIME_2 : 122|2@1+ (1,0) [0|7] "" XXX
 SG_ CHIME_1 : 133|1@0+ (1,0) [0|1] "" XXX
 SG_ ARROW_DOWN : 120|1@0+ (1,0) [0|1] "" XXX
 SG_ ARROW_UP : 121|1@0+ (1,0) [0|1] "" XXX
 SG_ SECONDARY_LIMIT_1 : 79|8@0+ (1,0) [0|127] "" XXX
 SG_ SECONDARY_LIMIT_2 : 103|8@0+ (1,0) [0|127] "" XXX
 SG_ SCHOOL_ZONE : 155|1@0+ (1,0) [0|1] "" XXX

BO_ 507 CAM_0x1fb: 32 CAMERA
 SG_ CHECKSUM : 0|16@1+ (1,0) [0|65535] "" XXX
 SG_ COUNTER : 16|8@1+ (1,0) [0|255] "" XXX

BO_ 512 RADAR_POINTS_METADATA_0x200: 64 RADAR
 SG_ SIGNAL_1 : 0|32@1+ (1,0) [0|255] "" XXX
 SG_ SIGNAL_2 : 32|32@1+ (1,0) [0|65535] "" XXX
 SG_ SIGNAL_3 : 64|4@1+ (1,0) [0|15] "" XXX
 SG_ SIGNAL_4 : 68|4@1+ (1,0) [0|15] "" XXX
 SG_ RADAR_POINT_COUNT : 72|8@1+ (1,0) [0|255] "" XXX
 SG_ SIGNAL_6 : 80|7@1+ (0.015625,0) [0|3] "" XXX
 SG_ SIGNAL_7 : 87|1@1+ (1,0) [0|1] "" XXX
 SG_ SIGNAL_8 : 88|3@1+ (1,0) [0|7] "" XXX
 SG_ SIGNAL_9 : 91|5@1+ (0.0625,0) [0|31] "" XXX
 SG_ SIGNAL_10 : 96|8@1+ (1,0) [0|255] "" XXX
 SG_ SIGNAL_11 : 104|7@1+ (0.015625,0) [0|127] "" XXX
 SG_ SIGNAL_12 : 111|2@1+ (1,0) [0|65535] "" XXX
 SG_ SIGNAL_13 : 113|7@1+ (0.015625,0) [0|127] "" XXX
 SG_ SIGNAL_14 : 120|7@1+ (0.015625,0) [0|127] "" XXX
 SG_ SIGNAL_15 : 127|3@1+ (1,0) [0|3] "" XXX
 SG_ SIGNAL_16 : 130|2@1+ (1,0) [0|3] "" XXX
 SG_ SIGNAL_17 : 133|2@0+ (1,0) [0|3] "" XXX
 SG_ SIGNAL_18 : 134|1@0+ (1,0) [0|3] "" XXX
 SG_ SIGNAL_19 : 135|3@1+ (1,0) [0|3] "" XXX
 SG_ SIGNAL_20 : 138|8@1+ (1,0) [0|63] "" XXX
 SG_ SIGNAL_21 : 146|2@1+ (1,0) [0|3] "" XXX
 SG_ SIGNAL_22 : 148|1@1+ (1,0) [0|3] "" XXX
 SG_ SIGNAL_23 : 149|4@1+ (1,0) [0|7] "" XXX
 SG_ SIGNAL_24 : 153|1@1+ (1,0) [0|3] "" XXX
 SG_ SIGNAL_25 : 154|2@1+ (1,0) [0|3] "" XXX
 SG_ SIGNAL_26 : 157|2@0+ (1,0) [0|3] "" XXX
 SG_ SIGNAL_27 : 158|7@1+ (0.125,0) [0|3] "" XXX
 SG_ SIGNAL_28 : 165|7@1+ (0.015625,0) [0|31] "" XXX
 SG_ SIGNAL_29 : 172|7@1+ (0.125,0) [0|3] "" XXX
 SG_ SIGNAL_30 : 179|7@1+ (0.015625,0) [0|1] "" XXX
 SG_ SIGNAL_31 : 186|4@1+ (1,0) [0|7] "" XXX
 SG_ SIGNAL_32 : 190|14@1+ (0.015625,0) [0|15] "" XXX
 SG_ SIGNAL_33 : 204|11@1+ (0.03125,0) [0|8191] "" XXX
 SG_ SIGNAL_34 : 215|2@1+ (1,0) [0|3] "" XXX
 SG_ SIGNAL_35 : 217|7@1+ (1,0) [0|127] "" XXX
 SG_ SIGNAL_36 : 224|6@1+ (1,0) [0|63] "" XXX
 SG_ SIGNAL_37 : 230|6@1+ (0.2,0) [0|31] "" XXX
 SG_ SIGNAL_38 : 236|6@1+ (0.2,0) [0|7] "" XXX
 SG_ SIGNAL_39 : 242|8@1+ (1,-90) [0|255] "" XXX
 SG_ SIGNAL_40 : 250|6@1+ (1,0) [0|63] "" XXX
 SG_ SIGNAL_41 : 256|8@1+ (0.25,0) [0|255] "" XXX
 SG_ SIGNAL_42 : 264|3@1+ (1,0) [0|3] "" XXX
 SG_ SIGNAL_43 : 267|12@1+ (0.01,0) [0|31] "" XXX
 SG_ SIGNAL_44 : 279|32@1+ (1,0) [0|63] "" XXX
 SG_ SIGNAL_45 : 311|1@1+ (1,0) [0|1] "" XXX
 SG_ SIGNAL_46 : 312|2@1+ (1,0) [0|3] "" XXX
 SG_ SIGNAL_47 : 314|32@1+ (1,0) [0|255] "" XXX
 SG_ SIGNAL_48 : 346|6@1+ (1,0) [0|63] "" XXX
 SG_ SIGNAL_49 : 352|7@1+ (0.25,0) [0|127] "" XXX
 SG_ SIGNAL_50 : 359|6@1+ (0.03125,0) [0|31] "" XXX
 SG_ SIGNAL_51 : 365|10@1+ (0.125,0) [0|3] "" XXX
 SG_ SIGNAL_52 : 375|10@1+ (0.125,0) [0|63] "" XXX
 SG_ SIGNAL_53 : 385|7@1+ (1,0) [0|127] "" XXX
 SG_ SIGNAL_54 : 392|7@1+ (1,0) [0|127] "" XXX
 SG_ SIGNAL_55 : 399|8@1+ (0.00390625,0) [0|31] "" XXX
 SG_ SIGNAL_56 : 407|10@1+ (0.125,0) [0|63] "" XXX
 SG_ SIGNAL_57 : 417|1@1+ (1,0) [0|3] "" XXX
 SG_ SIGNAL_58 : 418|1@1+ (1,0) [0|3] "" XXX

BO_ 513 RADAR_POINTS_0x201: 64 RADAR
 SG_ MESSAGE_ID : 0|5@1+ (1,0) [0|31] "" XXX
 SG_ LAYOUT_ID : 5|2@1+ (1,0) [0|3] "" XXX
 SG_ POINT_1_DISTANCE : 7|14@1+ (0.015625,0) [0|255.984375] "" XXX
 SG_ POINT_1_SIGNAL_2 : 21|2@1+ (1,0) [0|3] "" XXX
 SG_ POINT_1_SIGNAL_3 : 23|8@1+ (0.001953125,-0.248046875) [-0.248046875|0.25] "" XXX
 SG_ POINT_1_REL_VELOCITY : 31|13@1+ (0.03125,-66) [-66|189.96875] "" XXX
 SG_ POINT_1_SIGNAL_5 : 44|2@1+ (1,0) [0|3] "" XXX
 SG_ POINT_1_SIGNAL_6 : 46|2@1+ (1,0) [0|3] "" XXX
 SG_ POINT_1_AZIMUTH : 48|12@1+ (0.001953125,-3.998046875) [-3.998046875|4.0] "" XXX
 SG_ POINT_1_SIGNAL_8 : 60|2@1+ (1,0) [0|3] "" XXX
 SG_ POINT_1_SIGNAL_9 : 62|1@1+ (1,0) [0|1] "" XXX
 SG_ POINT_1_SIGNAL_10 : 63|7@1+ (1,0) [0|127] "" XXX
 SG_ POINT_1_SIGNAL_11 : 70|1@1+ (1,0) [0|1] "" XXX
 SG_ POINT_1_SIGNAL_12 : 71|6@1+ (1,0) [0|63] "" XXX
 SG_ POINT_1_SIGNAL_13 : 77|2@1+ (1,0) [0|3] "" XXX
 SG_ POINT_1_SIGNAL_14 : 79|8@1+ (0.001953125,-0.248046875) [-0.248046875|0.25] "" XXX
 SG_ POINT_1_SIGNAL_15 : 87|1@1+ (1,0) [0|1] "" XXX
 SG_ POINT_1_SIGNAL_16 : 88|2@1+ (1,0) [0|3] "" XXX
 SG_ POINT_1_SIGNAL_17 : 90|3@1+ (1,0) [0|7] "" XXX
 SG_ POINT_1_SIGNAL_18 : 93|6@1+ (1,0) [0|63] "" XXX
 SG_ POINT_1_SIGNAL_19 : 99|8@1+ (1,0) [0|255] "" XXX
 SG_ POINT_1_SIGNAL_20 : 107|1@1+ (1,0) [0|1] "" XXX
 SG_ POINT_2_DISTANCE : 108|14@1+ (0.015625,0) [0|255.984375] "" XXX
 SG_ POINT_2_SIGNAL_2 : 122|2@1+ (1,0) [0|3] "" XXX
 SG_ POINT_2_SIGNAL_3 : 124|8@1+ (0.001953125,-0.248046875) [-0.248046875|0.25] "" XXX
 SG_ POINT_2_REL_VELOCITY : 132|13@1+ (0.03125,-66) [-66|189.96875] "" XXX
 SG_ POINT_2_SIGNAL_5 : 145|2@1+ (1,0) [0|3] "" XXX
 SG_ POINT_2_SIGNAL_6 : 147|2@1+ (1,0) [0|3] "" XXX
 SG_ POINT_2_AZIMUTH : 149|12@1+ (0.001953125,-3.998046875) [-3.998046875|4.0] "" XXX
 SG_ POINT_2_SIGNAL_8 : 161|2@1+ (1,0) [0|3] "" XXX
 SG_ POINT_2_SIGNAL_9 : 163|1@1+ (1,0) [0|1] "" XXX
 SG_ POINT_2_SIGNAL_10 : 164|7@1+ (1,0) [0|127] "" XXX
 SG_ POINT_2_SIGNAL_11 : 171|1@1+ (1,0) [0|1] "" XXX
 SG_ POINT_2_SIGNAL_12 : 172|6@1+ (1,0) [0|63] "" XXX
 SG_ POINT_2_SIGNAL_13 : 178|2@1+ (1,0) [0|3] "" XXX
 SG_ POINT_2_SIGNAL_14 : 180|8@1+ (0.001953125,-0.248046875) [-0.248046875|0.25] "" XXX
 SG_ POINT_2_SIGNAL_15 : 188|1@1+ (1,0) [0|1] "" XXX
 SG_ POINT_2_SIGNAL_16 : 189|2@1+ (1,0) [0|3] "" XXX
 SG_ POINT_2_SIGNAL_17 : 191|3@1+ (1,0) [0|7] "" XXX
 SG_ POINT_2_SIGNAL_18 : 194|6@1+ (1,0) [0|63] "" XXX
 SG_ POINT_2_SIGNAL_19 : 200|8@1+ (1,0) [0|255] "" XXX
 SG_ POINT_2_SIGNAL_20 : 208|1@1+ (1,0) [0|1] "" XXX
 SG_ POINT_3_DISTANCE : 209|14@1+ (0.015625,0) [0|255.984375] "" XXX
 SG_ POINT_3_SIGNAL_2 : 223|2@1+ (1,0) [0|3] "" XXX
 SG_ POINT_3_SIGNAL_3 : 225|8@1+ (0.001953125,-0.248046875) [-0.248046875|0.25] "" XXX
 SG_ POINT_3_REL_VELOCITY : 233|13@1+ (0.03125,-66) [-66|189.96875] "" XXX
 SG_ POINT_3_SIGNAL_5 : 246|2@1+ (1,0) [0|3] "" XXX
 SG_ POINT_3_SIGNAL_6 : 248|2@1+ (1,0) [0|3] "" XXX
 SG_ POINT_3_AZIMUTH : 250|12@1+ (0.001953125,-3.998046875) [-3.998046875|4.0] "" XXX
 SG_ POINT_3_SIGNAL_8 : 262|2@1+ (1,0) [0|3] "" XXX
 SG_ POINT_3_SIGNAL_9 : 264|1@1+ (1,0) [0|1] "" XXX
 SG_ POINT_3_SIGNAL_10 : 265|7@1+ (1,0) [0|127] "" XXX
 SG_ POINT_3_SIGNAL_11 : 272|1@1+ (1,0) [0|1] "" XXX
 SG_ POINT_3_SIGNAL_12 : 273|6@1+ (1,0) [0|63] "" XXX
 SG_ POINT_3_SIGNAL_13 : 279|2@1+ (1,0) [0|3] "" XXX
 SG_ POINT_3_SIGNAL_14 : 281|8@1+ (0.001953125,-0.248046875) [-0.248046875|0.25] "" XXX
 SG_ POINT_3_SIGNAL_15 : 289|1@1+ (1,0) [0|1] "" XXX
 SG_ POINT_3_SIGNAL_16 : 290|2@1+ (1,0) [0|3] "" XXX
 SG_ POINT_3_SIGNAL_17 : 292|3@1+ (1,0) [0|7] "" XXX
 SG_ POINT_3_SIGNAL_18 : 295|6@1+ (1,0) [0|63] "" XXX
 SG_ POINT_3_SIGNAL_19 : 301|8@1+ (1,0) [0|255] "" XXX
 SG_ POINT_3_SIGNAL_20 : 309|1@1+ (1,0) [0|1] "" XXX
 SG_ POINT_4_DISTANCE : 310|14@1+ (0.015625,0) [0|255.984375] "" XXX
 SG_ POINT_4_SIGNAL_2 : 324|2@1+ (1,0) [0|3] "" XXX
 SG_ POINT_4_SIGNAL_3 : 326|8@1+ (0.001953125,-0.248046875) [-0.248046875|0.25] "" XXX
 SG_ POINT_4_REL_VELOCITY : 334|13@1+ (0.03125,-66) [-66|189.96875] "" XXX
 SG_ POINT_4_SIGNAL_5 : 347|2@1+ (1,0) [0|3] "" XXX
 SG_ POINT_4_SIGNAL_6 : 349|2@1+ (1,0) [0|3] "" XXX
 SG_ POINT_4_AZIMUTH : 351|12@1+ (0.001953125,-3.998046875) [-3.998046875|4.0] "" XXX
 SG_ POINT_4_SIGNAL_8 : 363|2@1+ (1,0) [0|3] "" XXX
 SG_ POINT_4_SIGNAL_9 : 365|1@1+ (1,0) [0|1] "" XXX
 SG_ POINT_4_SIGNAL_10 : 366|7@1+ (1,0) [0|127] "" XXX
 SG_ POINT_4_SIGNAL_11 : 373|1@1+ (1,0) [0|1] "" XXX
 SG_ POINT_4_SIGNAL_12 : 374|6@1+ (1,0) [0|63] "" XXX
 SG_ POINT_4_SIGNAL_13 : 380|2@1+ (1,0) [0|3] "" XXX
 SG_ POINT_4_SIGNAL_14 : 382|8@1+ (0.001953125,-0.248046875) [-0.248046875|0.25] "" XXX
 SG_ POINT_4_SIGNAL_15 : 390|1@1+ (1,0) [0|1] "" XXX
 SG_ POINT_4_SIGNAL_16 : 391|2@1+ (1,0) [0|3] "" XXX
 SG_ POINT_4_SIGNAL_17 : 393|3@1+ (1,0) [0|7] "" XXX
 SG_ POINT_4_SIGNAL_18 : 396|6@1+ (1,0) [0|63] "" XXX
 SG_ POINT_4_SIGNAL_19 : 402|8@1+ (1,0) [0|255] "" XXX
 SG_ POINT_4_SIGNAL_20 : 410|1@1+ (1,0) [0|1] "" XXX
 SG_ POINT_5_DISTANCE : 411|14@1+ (0.015625,0) [0|255.984375] "" XXX
 SG_ POINT_5_SIGNAL_2 : 425|2@1+ (1,0) [0|3] "" XXX
 SG_ POINT_5_SIGNAL_3 : 427|8@1+ (0.001953125,-0.248046875) [-0.248046875|0.25] "" XXX
 SG_ POINT_5_REL_VELOCITY : 435|13@1+ (0.03125,-66) [-66|189.96875] "" XXX
 SG_ POINT_5_SIGNAL_5 : 448|2@1+ (1,0) [0|3] "" XXX
 SG_ POINT_5_SIGNAL_6 : 450|2@1+ (1,0) [0|3] "" XXX
 SG_ POINT_5_AZIMUTH : 452|12@1+ (0.001953125,-3.998046875) [-3.998046875|4.0] "" XXX
 SG_ POINT_5_SIGNAL_8 : 464|2@1+ (1,0) [0|3] "" XXX
 SG_ POINT_5_SIGNAL_9 : 466|1@1+ (1,0) [0|1] "" XXX
 SG_ POINT_5_SIGNAL_10 : 467|7@1+ (1,0) [0|127] "" XXX
 SG_ POINT_5_SIGNAL_11 : 474|1@1+ (1,0) [0|1] "" XXX
 SG_ POINT_5_SIGNAL_12 : 475|6@1+ (1,0) [0|63] "" XXX
 SG_ POINT_5_SIGNAL_13 : 481|2@1+ (1,0) [0|3] "" XXX
 SG_ POINT_5_SIGNAL_14 : 483|8@1+ (0.001953125,-0.248046875) [-0.248046875|0.25] "" XXX
 SG_ POINT_5_SIGNAL_15 : 491|1@1+ (1,0) [0|1] "" XXX
 SG_ POINT_5_SIGNAL_16 : 492|2@1+ (1,0) [0|3] "" XXX
 SG_ POINT_5_SIGNAL_17 : 494|3@1+ (1,0) [0|7] "" XXX
 SG_ POINT_5_SIGNAL_18 : 497|6@1+ (1,0) [0|63] "" XXX
 SG_ POINT_5_SIGNAL_19 : 503|8@1+ (1,0) [0|255] "" XXX
 SG_ POINT_5_SIGNAL_20 : 511|1@1+ (1,0) [0|1] "" XXX

BO_ 528 RADAR_0x210: 32 FRONT_RADAR
 SG_ CHECKSUM : 0|16@1+ (1,0) [0|65535] "" XXX
 SG_ COUNTER : 16|8@1+ (1,0) [0|255] "" XXX

BO_ 529 RADAR_0x211: 32 FRONT_RADAR
 SG_ CHECKSUM : 0|16@1+ (1,0) [0|65535] "" XXX
 SG_ COUNTER : 16|8@1+ (1,0) [0|255] "" XXX

BO_ 530 RADAR_0x212: 32 FRONT_RADAR
 SG_ CHECKSUM : 0|16@1+ (1,0) [0|65535] "" XXX
 SG_ COUNTER : 16|8@1+ (1,0) [0|255] "" XXX

BO_ 531 RADAR_0x213: 32 FRONT_RADAR
 SG_ CHECKSUM : 0|16@1+ (1,0) [0|65535] "" XXX
 SG_ COUNTER : 16|8@1+ (1,0) [0|255] "" XXX

BO_ 532 RADAR_0x214: 32 FRONT_RADAR
 SG_ CHECKSUM : 0|16@1+ (1,0) [0|65535] "" XXX
 SG_ COUNTER : 16|8@1+ (1,0) [0|255] "" XXX

BO_ 533 RADAR_0x215: 32 FRONT_RADAR
 SG_ CHECKSUM : 0|16@1+ (1,0) [0|65535] "" XXX
 SG_ COUNTER : 16|8@1+ (1,0) [0|255] "" XXX

BO_ 534 RADAR_0x216: 32 FRONT_RADAR
 SG_ CHECKSUM : 0|16@1+ (1,0) [0|65535] "" XXX
 SG_ COUNTER : 16|8@1+ (1,0) [0|255] "" XXX

BO_ 535 RADAR_0x217: 32 FRONT_RADAR
 SG_ CHECKSUM : 0|16@1+ (1,0) [0|65535] "" XXX
 SG_ COUNTER : 16|8@1+ (1,0) [0|255] "" XXX

BO_ 536 RADAR_0x218: 32 FRONT_RADAR
 SG_ CHECKSUM : 0|16@1+ (1,0) [0|65535] "" XXX
 SG_ COUNTER : 16|8@1+ (1,0) [0|255] "" XXX

BO_ 537 RADAR_0x219: 32 FRONT_RADAR
 SG_ CHECKSUM : 0|16@1+ (1,0) [0|65535] "" XXX
 SG_ COUNTER : 16|8@1+ (1,0) [0|255] "" XXX

BO_ 538 RADAR_0x21a: 32 FRONT_RADAR
 SG_ CHECKSUM : 0|16@1+ (1,0) [0|65535] "" XXX
 SG_ COUNTER : 16|8@1+ (1,0) [0|255] "" XXX

BO_ 539 RADAR_0x21b: 32 FRONT_RADAR
 SG_ CHECKSUM : 0|16@1+ (1,0) [0|65535] "" XXX
 SG_ COUNTER : 16|8@1+ (1,0) [0|255] "" XXX

BO_ 540 RADAR_0x21c: 32 FRONT_RADAR
 SG_ CHECKSUM : 0|16@1+ (1,0) [0|65535] "" XXX
 SG_ COUNTER : 16|8@1+ (1,0) [0|255] "" XXX

BO_ 541 RADAR_0x21d: 32 FRONT_RADAR
 SG_ CHECKSUM : 0|16@1+ (1,0) [0|65535] "" XXX
 SG_ COUNTER : 16|8@1+ (1,0) [0|255] "" XXX

BO_ 542 RADAR_0x21e: 32 FRONT_RADAR
 SG_ CHECKSUM : 0|16@1+ (1,0) [0|65535] "" XXX
 SG_ COUNTER : 16|8@1+ (1,0) [0|255] "" XXX

BO_ 543 RADAR_0x21f: 32 FRONT_RADAR
 SG_ CHECKSUM : 0|16@1+ (1,0) [0|65535] "" XXX
 SG_ COUNTER : 16|8@1+ (1,0) [0|255] "" XXX

BO_ 576 RADAR_0x240: 16 FRONT_RADAR
 SG_ CHECKSUM : 0|16@1+ (1,0) [0|65535] "" XXX
 SG_ COUNTER : 16|8@1+ (1,0) [0|255] "" XXX

BO_ 593 RADAR_0x251: 16 FRONT_RADAR
 SG_ CHECKSUM : 0|16@1+ (1,0) [0|65535] "" XXX
 SG_ COUNTER : 16|8@1+ (1,0) [0|255] "" XXX

BO_ 674 CAM_0x2a2: 32 CAMERA
 SG_ CHECKSUM : 0|16@1+ (1,0) [0|65535] "" XXX
 SG_ COUNTER : 16|8@1+ (1,0) [0|255] "" XXX

BO_ 675 CAM_0x2a3: 32 CAMERA
 SG_ CHECKSUM : 0|16@1+ (1,0) [0|65535] "" XXX
 SG_ COUNTER : 16|8@1+ (1,0) [0|255] "" XXX

BO_ 676 CAM_0x2a4: 24 XXX
 SG_ CHECKSUM : 0|16@1+ (1,0) [0|65535] "" XXX
 SG_ COUNTER : 16|8@1+ (1,0) [0|255] "" XXX
 SG_ BYTE3 : 24|8@1+ (1,0) [0|255] "" XXX
 SG_ BYTE4 : 32|8@1+ (1,0) [0|255] "" XXX
 SG_ BYTE5 : 40|8@1+ (1,0) [0|255] "" XXX
 SG_ BYTE6 : 48|8@1+ (1,0) [0|255] "" XXX
 SG_ LEFT_LANE_LINE : 56|2@1+ (1,0) [0|3] "" XXX
 SG_ SET_ME_0 : 58|2@1+ (1,0) [0|3] "" XXX
 SG_ RIGHT_LANE_LINE : 60|2@1+ (1,0) [0|3] "" XXX
 SG_ SET_ME_0_2 : 62|2@1+ (1,0) [0|3] "" XXX
 SG_ BYTE8 : 64|8@1+ (1,0) [0|255] "" XXX
 SG_ BYTE9 : 72|8@1+ (1,0) [0|255] "" XXX
 SG_ BYTE10 : 80|8@1+ (1,0) [0|255] "" XXX
 SG_ BYTE11 : 88|8@1+ (1,0) [0|255] "" XXX
 SG_ BYTE12 : 96|8@1+ (1,0) [0|255] "" XXX
 SG_ BYTE13 : 104|8@1+ (1,0) [0|255] "" XXX
 SG_ BYTE14 : 112|8@1+ (1,0) [0|255] "" XXX
 SG_ BYTE15 : 120|8@1+ (1,0) [0|255] "" XXX
 SG_ BYTE16 : 128|8@1+ (1,0) [0|255] "" XXX
 SG_ BYTE17 : 136|8@1+ (1,0) [0|255] "" XXX
 SG_ BYTE18 : 144|8@1+ (1,0) [0|255] "" XXX
 SG_ BYTE19 : 152|8@1+ (1,0) [0|255] "" XXX
 SG_ BYTE20 : 160|8@1+ (1,0) [0|255] "" XXX
 SG_ BYTE21 : 168|8@1+ (1,0) [0|255] "" XXX
 SG_ BYTE22 : 176|8@1+ (1,0) [0|255] "" XXX
 SG_ BYTE23 : 184|8@1+ (1,0) [0|255] "" XXX

BO_ 699 CAM_0x2bb: 32 CAMERA
 SG_ CHECKSUM : 0|16@1+ (1,0) [0|65535] "" XXX
 SG_ COUNTER : 16|8@1+ (1,0) [0|255] "" XXX

BO_ 700 CAM_0x2bc: 32 CAMERA
 SG_ CHECKSUM : 0|16@1+ (1,0) [0|65535] "" XXX
 SG_ COUNTER : 16|8@1+ (1,0) [0|255] "" XXX

BO_ 701 CAM_0x2bd: 32 CAMERA
 SG_ CHECKSUM : 0|16@1+ (1,0) [0|65535] "" XXX
 SG_ COUNTER : 16|8@1+ (1,0) [0|255] "" XXX

BO_ 702 CAM_0x2be: 32 CAMERA
 SG_ CHECKSUM : 0|16@1+ (1,0) [0|65535] "" XXX
 SG_ COUNTER : 16|8@1+ (1,0) [0|255] "" XXX

BO_ 736 MANUAL_SPEED_LIMIT_ASSIST: 32 XXX
 SG_ CHECKSUM : 0|16@1+ (1,0) [0|65535] "" XXX
 SG_ COUNTER : 16|8@1+ (1,0) [0|255] "" XXX
 SG_ MSLA_STATUS : 26|2@1+ (1,0) [0|3] "" XXX
 SG_ MSLA_ENABLED : 38|1@1+ (1,0) [0|1] "" XXX
 SG_ MAX_SPEED : 55|8@0+ (1,0) [0|255] "" XXX
 SG_ MAX_SPEED_COPY : 144|8@1+ (1,0) [0|255] "" XXX

BO_ 837 ADRV_0x345: 8 ADRV
 SG_ CHECKSUM : 0|16@1+ (1,0) [0|65535] "" XXX
 SG_ COUNTER : 16|8@1+ (1,0) [0|255] "" XXX
 SG_ SET_ME_15 : 24|8@1+ (1,0) [0|255] "" XXX

BO_ 866 CAM_0x362: 32 CAMERA
 SG_ CHECKSUM : 0|16@1+ (1,0) [0|65535] "" XXX
 SG_ COUNTER : 16|8@1+ (1,0) [0|255] "" XXX
 SG_ BYTE3 : 24|8@1+ (1,0) [0|255] "" XXX
 SG_ BYTE4 : 32|8@1+ (1,0) [0|255] "" XXX
 SG_ BYTE5 : 40|8@1+ (1,0) [0|255] "" XXX
 SG_ BYTE6 : 48|8@1+ (1,0) [0|255] "" XXX
 SG_ LEFT_LANE_LINE : 56|2@1+ (1,0) [0|3] "" XXX
 SG_ SET_ME_0 : 58|2@1+ (1,0) [0|3] "" XXX
 SG_ RIGHT_LANE_LINE : 60|2@1+ (1,0) [0|3] "" XXX
 SG_ SET_ME_0_2 : 62|2@1+ (1,0) [0|3] "" XXX
 SG_ BYTE8 : 64|8@1+ (1,0) [0|255] "" XXX
 SG_ BYTE9 : 72|8@1+ (1,0) [0|255] "" XXX
 SG_ BYTE10 : 80|8@1+ (1,0) [0|255] "" XXX
 SG_ BYTE11 : 88|8@1+ (1,0) [0|255] "" XXX
 SG_ BYTE12 : 96|8@1+ (1,0) [0|255] "" XXX
 SG_ BYTE13 : 104|8@1+ (1,0) [0|255] "" XXX
 SG_ BYTE14 : 112|8@1+ (1,0) [0|255] "" XXX
 SG_ BYTE15 : 120|8@1+ (1,0) [0|255] "" XXX
 SG_ BYTE16 : 128|8@1+ (1,0) [0|255] "" XXX
 SG_ BYTE17 : 136|8@1+ (1,0) [0|255] "" XXX
 SG_ BYTE18 : 144|8@1+ (1,0) [0|255] "" XXX
 SG_ BYTE19 : 152|8@1+ (1,0) [0|255] "" XXX
 SG_ BYTE20 : 160|8@1+ (1,0) [0|255] "" XXX
 SG_ BYTE21 : 168|8@1+ (1,0) [0|255] "" XXX
 SG_ BYTE22 : 176|8@1+ (1,0) [0|255] "" XXX
 SG_ BYTE23 : 184|8@1+ (1,0) [0|255] "" XXX
 SG_ BYTE24 : 192|8@1+ (1,0) [0|255] "" XXX
 SG_ BYTE25 : 200|8@1+ (1,0) [0|255] "" XXX
 SG_ BYTE26 : 208|8@1+ (1,0) [0|255] "" XXX
 SG_ BYTE27 : 216|8@1+ (1,0) [0|255] "" XXX
 SG_ BYTE28 : 224|8@1+ (1,0) [0|255] "" XXX
 SG_ BYTE29 : 232|8@1+ (1,0) [0|255] "" XXX
 SG_ BYTE30 : 240|8@1+ (1,0) [0|255] "" XXX
 SG_ BYTE31 : 248|8@1+ (1,0) [0|255] "" XXX

BO_ 874 BLINDSPOTS_FRONT_CORNER_2: 16 XXX
 SG_ COUNTER : 16|8@1+ (1,0) [0|255] "" XXX
 SG_ CHECKSUM : 0|16@1+ (1,0) [0|65535] "" XXX

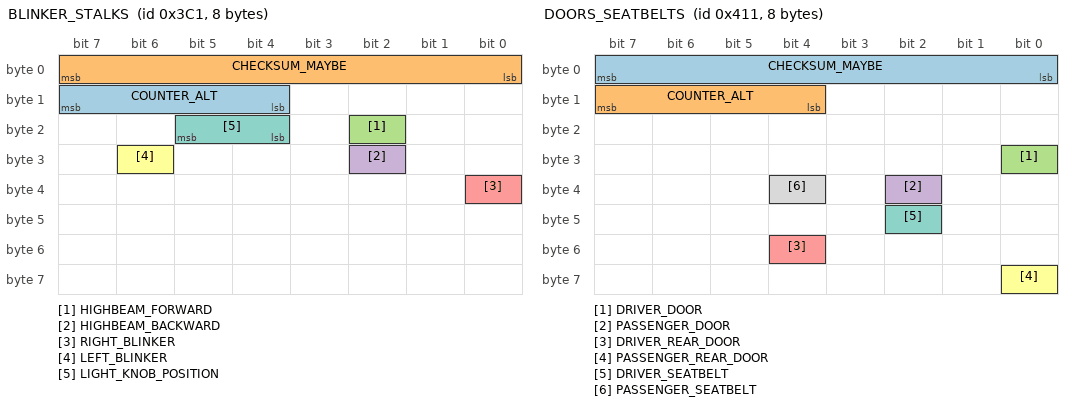
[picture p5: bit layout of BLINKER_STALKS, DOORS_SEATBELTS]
BO_ 961 BLINKER_STALKS: 8 XXX
 SG_ COUNTER_ALT : 15|4@0+ (1,0) [0|15] "" XXX
 SG_ CHECKSUM_MAYBE : 7|8@0+ (1,0) [0|255] "" XXX
 SG_ HIGHBEAM_FORWARD : 18|1@0+ (1,0) [0|1] "" XXX
 SG_ HIGHBEAM_BACKWARD : 26|1@0+ (1,0) [0|1] "" XXX
 SG_ RIGHT_BLINKER : 32|1@0+ (1,0) [0|1] "" XXX
 SG_ LEFT_BLINKER : 30|1@0+ (1,0) [0|1] "" XXX
 SG_ LIGHT_KNOB_POSITION : 21|2@0+ (1,0) [0|3] "" XXX

BO_ 1041 DOORS_SEATBELTS: 8 XXX
 SG_ CHECKSUM_MAYBE : 7|8@0+ (1,0) [0|65535] "" XXX
 SG_ COUNTER_ALT : 15|4@0+ (1,0) [0|15] "" XXX
 SG_ DRIVER_DOOR : 24|1@1+ (1,0) [0|1] "" XXX
 SG_ PASSENGER_DOOR : 34|1@0+ (1,0) [0|1] "" XXX
 SG_ DRIVER_REAR_DOOR : 52|1@0+ (1,0) [0|1] "" XXX
 SG_ PASSENGER_REAR_DOOR : 56|1@0+ (1,0) [0|1] "" XXX
 SG_ DRIVER_SEATBELT : 42|1@0+ (1,0) [0|1] "" XXX
 SG_ PASSENGER_SEATBELT : 36|1@0+ (1,0) [0|1] "" XXX

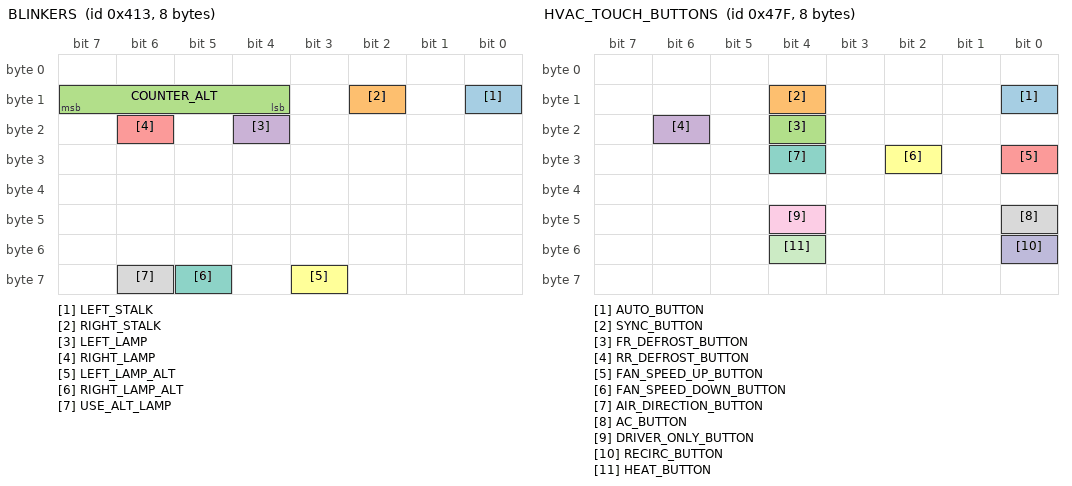
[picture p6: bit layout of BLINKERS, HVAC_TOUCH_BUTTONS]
BO_ 1043 BLINKERS: 8 XXX
 SG_ LEFT_STALK : 8|1@0+ (1,0) [0|1] "" XXX
 SG_ RIGHT_STALK : 10|1@0+ (1,0) [0|1] "" XXX
 SG_ COUNTER_ALT : 15|4@0+ (1,0) [0|15] "" XXX
 SG_ LEFT_LAMP : 20|1@0+ (1,0) [0|1] "" XXX
 SG_ RIGHT_LAMP : 22|1@0+ (1,0) [0|1] "" XXX
 SG_ LEFT_LAMP_ALT : 59|1@0+ (1,0) [0|1] "" XXX
 SG_ RIGHT_LAMP_ALT : 61|1@0+ (1,0) [0|1] "" XXX
 SG_ USE_ALT_LAMP : 62|1@0+ (1,0) [0|1] "" XXX

BO_ 1144 DRIVE_MODE: 8 XXX
 SG_ DRIVE_MODE : 0|16@1+ (1,-61611) [0|61611] "" XXX
 SG_ DRIVE_MODE2 : 28|3@1+ (1,0) [1|3] "" XXX

BO_ 1151 HVAC_TOUCH_BUTTONS: 8 XXX
 SG_ AUTO_BUTTON : 8|1@0+ (1,0) [0|1] "" XXX
 SG_ SYNC_BUTTON : 12|1@0+ (1,0) [0|1] "" XXX
 SG_ FR_DEFROST_BUTTON : 20|1@0+ (1,0) [0|1] "" XXX
 SG_ RR_DEFROST_BUTTON : 22|1@0+ (1,0) [0|1] "" XXX
 SG_ FAN_SPEED_UP_BUTTON : 24|1@0+ (1,0) [0|1] "" XXX
 SG_ FAN_SPEED_DOWN_BUTTON : 26|1@0+ (1,0) [0|1] "" XXX
 SG_ AIR_DIRECTION_BUTTON : 28|1@0+ (1,0) [0|1] "" XXX
 SG_ AC_BUTTON : 40|1@0+ (1,0) [0|1] "" XXX
 SG_ DRIVER_ONLY_BUTTON : 44|1@0+ (1,0) [0|1] "" XXX
 SG_ RECIRC_BUTTON : 48|1@0+ (1,0) [0|1] "" XXX
 SG_ HEAT_BUTTON : 52|1@0+ (1,0) [0|1] "" XXX

BO_ 1240 CLUSTER_INFO: 8 XXX
 SG_ DISTANCE_UNIT : 0|1@1+ (1,0) [0|1] "" XXX

BO_ 1259 LOCAL_TIME2: 8 XXX
 SG_ HOURS : 15|5@0+ (1,0) [0|31] "" XXX
 SG_ MINUTES : 21|6@0+ (1,0) [0|63] "" XXX
 SG_ SECONDS : 24|6@1+ (1,0) [0|63] "" XXX
 SG_ NEW_SIGNAL_3 : 39|1@0+ (1,0) [0|1] "" XXX

BO_ 1264 LOCAL_TIME: 8 XXX
 SG_ HOURS : 12|5@0+ (1,0) [0|31] "" XXX
 SG_ MINUTES : 21|6@0+ (1,0) [0|63] "" XXX
 SG_ SECONDS : 31|8@0+ (1,0) [0|59] "" XXX

VAL_ 1041 DRIVER_DOOR 0 "Closed" 1 "Opened";
VAL_ 1041 DRIVER_REAR_DOOR 0 "Closed" 1 "Opened";
VAL_ 1041 DRIVER_SEATBELT 0 "Unlatched" 1 "Latched";
VAL_ 1041 PASSENGER_DOOR 0 "Closed" 1 "Opened";
VAL_ 1041 PASSENGER_REAR_DOOR 0 "Closed" 1 "Opened";
VAL_ 1041 PASSENGER_SEATBELT 0 "Unlatched" 1 "Latched";
VAL_ 112 GEAR 0 "P" 5 "D" 6 "N" 7 "R" ;
VAL_ 1144 DRIVE_MODE2 3 "Set Sport" 1 "Set Normal" 2 "Set Eco";
VAL_ 1240 DISTANCE_UNIT 1 "Miles" 0 "Kilometers";
VAL_ 234 LKA_FAULT 0 "ok" 1 "lka fault" ;
VAL_ 272 LKA_ICON 0 "hidden" 1 "grey" 2 "green" 3 "flashing green" ;
VAL_ 272 LKA_MODE 1 "warning only" 2 "assist" 6 "off" ;
VAL_ 298 LKA_ICON 0 "hidden" 1 "grey" 2 "green" 3 "flashing green" ;
VAL_ 298 LKA_MODE 1 "warning only" 2 "assist" 6 "off" ;
VAL_ 304 GEAR 1 "P" 2 "R" 3 "N" 4 "D" ;
VAL_ 304 KNOB_POSITION 1 "R" 2 "N (on R side)" 3 "Centered" 4 "N (on D side)" 5 "D";
VAL_ 304 PARK_BUTTON 1 "Pressed" 2 "Not Pressed";
VAL_ 352 AEB_SETTING 1 "off" 2 "warning only" 3 "active assist" ;
VAL_ 362 BLINKER_CONTROL 1 "hazards" 2 "hazards button backlight" 3 "left blinkers" 4 "right blinkers";
VAL_ 373 ACCEnable 0 "SCC ready" 1 "SCC temp fault" 2 "SCC permanent fault" 3 "SCC permanent fault, communication issue";
VAL_ 416 ACCMode 0 "off" 1 "enabled" 2 "driver_override" 3 "off_maybe_fault" 4 "cancelled" ;
VAL_ 426 CRUISE_BUTTONS 0 "none" 1 "res_accel" 2 "set_decel" 3 "gap_distance" 4 "pause_resume" ;
VAL_ 463 CRUISE_BUTTONS 0 "none" 1 "res_accel" 2 "set_decel" 3 "gap_distance" 4 "pause_resume" ;
VAL_ 463 LEFT_PADDLE 0 "Not Pulled" 1 "Pulled";
VAL_ 463 RIGHT_PADDLE 0 "Not Pulled" 1 "Pulled";
VAL_ 53 GEAR 0 "P" 5 "D" 6 "N" 7 "R" ;
VAL_ 64 GEAR 0 "P" 5 "D" 6 "N" 7 "R" ;
VAL_ 676 LEFT_LANE_LINE 0 "Not Detected" 1 "Low Confidence" 2 "Medium Confidence" 3 "High Confidence";
VAL_ 676 RIGHT_LANE_LINE 0 "Not Detected" 1 "Low Confidence" 2 "Medium Confidence" 3 "High Confidence";
VAL_ 69 GEAR 0 "P" 5 "D" 6 "N" 7 "R" ;
VAL_ 736 MSLA_STATUS 0 "disabled" 1 "active" 2 "paused";
VAL_ 80 LKA_ICON 0 "hidden" 1 "grey" 2 "green" 3 "flashing green" ;
VAL_ 80 LKA_MODE 1 "warning only" 2 "assist" 6 "off" ;
VAL_ 866 LEFT_LANE_LINE 0 "Not Detected" 1 "Low Confidence" 2 "Medium Confidence" 3 "High Confidence";
VAL_ 866 RIGHT_LANE_LINE 0 "Not Detected" 1 "Low Confidence" 2 "Medium Confidence" 3 "High Confidence";
VAL_ 96 TRACTION_AND_STABILITY_CONTROL 0 "On" 5 "Limited" 1 "Off";

BA_
    CAT_DEF_
    CAT_
    FILTER
    BA_DEF_DEF_
    EV_DATA_
    ENVVAR_DATA_
    SGTYPE_
    SGTYPE_VAL_
    BA_DEF_SGTYPE_
    BA_SGTYPE_
    SIG_TYPE_REF_
    VAL_TABLE_
    SIG_GROUP_
    SIG_VALTYPE_
    SIGTYPE_VALTYPE_
    BO_TX_BU_
    BA_DEF_REL_
    BA_REL_
    BA_DEF_DEF_REL_
    BU_SG_REL_
    BU_EV_REL_
    BU_BO_REL_
    SG_MUL_VAL_

BS_:

BU_: XXX CAMERA FRONT_RADAR ADRV APRK

BO_ 53 ACCELERATOR: 32 XXX
 SG_ CHECKSUM : 0|16@1+ (1,0) [0|65535] "" XXX
 SG_ COUNTER : 16|8@1+ (1,0) [0|255] "" XXX
 SG_ GEAR : 192|3@1+ (1,0) [0|7] "" XXX
 SG_ ACCELERATOR_PEDAL : 40|8@1+ (1,0) [0|255] "" XXX

BO_ 64 GEAR_ALT: 32 XXX
 SG_ CHECKSUM : 0|16@1+ (1,0) [0|65535] "" XXX
 SG_ COUNTER : 16|8@1+ (1,0) [0|255] "" XXX
 SG_ GEAR : 32|3@1+ (1,0) [0|7] "" XXX

BO_ 69 GEAR: 24 XXX
 SG_ CHECKSUM : 0|16@1+ (1,0) [0|65535] "" XXX
 SG_ COUNTER : 16|8@1+ (1,0) [0|255] "" XXX
 SG_ GEAR : 44|3@1+ (1,0) [0|7] "" XXX

BO_ 80 LKAS: 16 XXX
 SG_ STEER_REQ : 52|1@1+ (1,0) [0|1] "" XXX
 SG_ TORQUE_REQUEST : 41|11@1+ (1,-1024) [0|4095] "" XXX
 SG_ LKA_ICON : 38|2@1+ (1,0) [0|255] "" XXX
 SG_ NEW_SIGNAL_1 : 27|2@1+ (1,0) [0|255] "" XXX
 SG_ LFA_BUTTON : 56|1@1+ (1,0) [0|255] "" XXX
 SG_ COUNTER : 16|8@1+ (1,0) [0|255] "" XXX
 SG_ CHECKSUM : 0|16@1+ (1,0) [0|65535] "" XXX
 SG_ STEER_MODE : 65|3@1+ (1,0) [0|1] "" XXX
 SG_ LKA_WARNING : 32|1@1+ (1,0) [0|1] "" XXX
 SG_ LKA_ASSIST : 62|1@1+ (1,0) [0|1] "" XXX
 SG_ LKA_MODE : 24|3@1+ (1,0) [0|7] "" XXX
 SG_ NEW_SIGNAL_2 : 70|2@0+ (1,0) [0|3] "" XXX
 SG_ HAS_LANE_SAFETY : 80|1@0+ (1,0) [0|1] "" XXX
 SG_ NEW_SIGNAL_3 : 111|8@0+ (1,0) [0|255] "" XXX
 SG_ FCA_SYSWARN : 40|1@0+ (1,0) [0|1] "" XXX

BO_ 81 ADRV_0x51: 32 ADRV
 SG_ COUNTER : 16|8@1+ (1,0) [0|255] "" XXX
 SG_ CHECKSUM : 0|16@1+ (1,0) [0|65535] "" XXX

BO_ 96 ESP_STATUS: 32 XXX
 SG_ CHECKSUM : 0|16@1+ (1,0) [0|65535] "" XXX
 SG_ COUNTER : 16|8@1+ (1,0) [0|255] "" XXX
 SG_ TRACTION_AND_STABILITY_CONTROL : 42|3@1+ (1,0) [0|63] "" XXX
 SG_ BRAKE_PRESSURE : 128|10@1+ (1,0) [0|65535] "" XXX
 SG_ BRAKE_PRESSED : 148|1@1+ (1,0) [0|3] "" XXX

BO_ 101 BRAKE: 32 XXX
 SG_ CHECKSUM : 0|16@1+ (1,0) [0|65535] "" XXX
 SG_ COUNTER : 16|8@1+ (1,0) [0|255] "" XXX
 SG_ BRAKE_POSITION : 40|16@1- (1,0) [0|65535] "" XXX
 SG_ BRAKE_PRESSED : 57|1@1+ (1,0) [0|3] "" XXX

BO_ 112 GEAR_ALT_2: 32 XXX
 SG_ CHECKSUM : 0|16@1+ (1,0) [0|65535] "" XXX
 SG_ COUNTER : 16|8@1+ (1,0) [0|255] "" XXX
 SG_ GEAR : 60|3@1+ (1,0) [0|7] "" XXX

BO_ 160 WHEEL_SPEEDS: 24 XXX
 SG_ CHECKSUM : 0|16@1+ (1,0) [0|65535] "" XXX
 SG_ COUNTER : 16|8@1+ (1,0) [0|255] "" XXX
 SG_ MOVING_FORWARD : 56|1@0+ (1,0) [0|1] "" XXX
 SG_ MOVING_BACKWARD : 57|1@0+ (1,0) [0|1] "" XXX
 SG_ MOVING_FORWARD2 : 58|1@0+ (1,0) [0|1] "" XXX
 SG_ MOVING_BACKWARD2 : 59|1@0+ (1,0) [0|1] "" XXX
 SG_ WHEEL_SPEED_1 : 64|16@1+ (0.03125,0) [0|65535] "kph" XXX
 SG_ WHEEL_SPEED_2 : 80|16@1+ (0.03125,0) [0|65535] "kph" XXX
 SG_ WHEEL_SPEED_3 : 96|16@1+ (0.03125,0) [0|65535] "kph" XXX
 SG_ WHEEL_SPEED_4 : 112|16@1+ (0.03125,0) [0|65535] "kph" XXX

BO_ 234 MDPS: 24 XXX
 SG_ CHECKSUM : 0|16@1+ (1,0) [0|65535] "" XXX
 SG_ COUNTER : 16|8@1+ (1,0) [0|255] "" XXX
 SG_ LKA_ACTIVE : 48|1@0+ (1,0) [0|16777215] "" XXX
 SG_ LKA_FAULT : 54|1@0+ (1,0) [0|1] "" XXX
 SG_ STEERING_OUT_TORQUE : 64|12@1+ (0.1,-204.8) [0|65535] "" XXX
 SG_ STEERING_COL_TORQUE : 80|13@1+ (1,-4095) [0|4095] "" XXX
 SG_ STEERING_ANGLE : 96|16@1- (-0.1,0) [0|255] "deg" XXX
 SG_ STEERING_ANGLE_2 : 128|16@1- (-0.1,0) [0|65535] "deg" XXX

BO_ 256 ACCELERATOR_BRAKE_ALT: 32 XXX
 SG_ CHECKSUM : 0|16@1+ (1,0) [0|65535] "" XXX
 SG_ COUNTER : 16|8@1+ (1,0) [0|255] "" XXX
 SG_ BRAKE_PRESSED : 32|1@1+ (1,0) [0|1] "" XXX
 SG_ ACCELERATOR_PEDAL_PRESSED : 176|1@1+ (1,0) [0|1] "" XXX

BO_ 261 ACCELERATOR_ALT: 32 XXX
 SG_ CHECKSUM : 0|16@1+ (1,0) [0|65535] "" XXX
 SG_ COUNTER : 16|8@1+ (1,0) [0|255] "" XXX
 SG_ ACCELERATOR_PEDAL : 103|10@1+ (0.25,0) [0|1022] "" XXX

BO_ 272 LKAS_ALT: 32 XXX
 SG_ STEER_REQ : 52|1@1+ (1,0) [0|1] "" XXX
 SG_ TORQUE_REQUEST : 41|11@1+ (1,-1024) [0|4095] "" XXX
 SG_ LKA_ICON : 38|2@1+ (1,0) [0|255] "" XXX
 SG_ NEW_SIGNAL_1 : 27|2@1+ (1,0) [0|255] "" XXX
 SG_ LFA_BUTTON : 56|1@1+ (1,0) [0|255] "" XXX
 SG_ COUNTER : 16|8@1+ (1,0) [0|255] "" XXX
 SG_ CHECKSUM : 0|16@1+ (1,0) [0|65535] "" XXX
 SG_ STEER_MODE : 65|3@1+ (1,0) [0|1] "" XXX
 SG_ LKA_WARNING : 32|1@1+ (1,0) [0|1] "" XXX
 SG_ LKA_ASSIST : 62|1@1+ (1,0) [0|1] "" XXX
 SG_ LKA_MODE : 24|3@1+ (1,0) [0|7] "" XXX
 SG_ NEW_SIGNAL_2 : 70|2@0+ (1,0) [0|3] "" XXX
 SG_ HAS_LANE_SAFETY : 80|1@0+ (1,0) [0|1] "" XXX
 SG_ NEW_SIGNAL_3 : 111|8@0+ (1,0) [0|255] "" XXX
 SG_ FCA_SYSWARN : 40|1@0+ (1,0) [0|1] "" XXX

BO_ 293 STEERING_SENSORS: 16 XXX
 SG_ CHECKSUM : 0|16@1+ (1,0) [0|65535] "" XXX
 SG_ COUNTER : 16|8@1+ (1,0) [0|255] "" XXX
 SG_ STEERING_RATE : 40|8@1+ (4,0) [0|1016] "deg/s" XXX
 SG_ STEERING_ANGLE : 24|16@1- (-0.1,0) [0|255] "deg" XXX

BO_ 298 LFA: 16 ADRV
 SG_ STEER_REQ : 52|1@1+ (1,0) [0|1] "" XXX
 SG_ TORQUE_REQUEST : 41|11@1+ (1,-1024) [0|4095] "" XXX
 SG_ LKA_ICON : 38|2@1+ (1,0) [0|255] "" XXX
 SG_ NEW_SIGNAL_1 : 27|2@1+ (1,0) [0|255] "" XXX
 SG_ LFA_BUTTON : 56|1@1+ (1,0) [0|255] "" XXX
 SG_ COUNTER : 16|8@1+ (1,0) [0|255] "" XXX
 SG_ CHECKSUM : 0|16@1+ (1,0) [0|65535] "" XXX
 SG_ STEER_MODE : 65|3@1+ (1,0) [0|1] "" XXX
 SG_ LKA_WARNING : 32|1@1+ (1,0) [0|1] "" XXX
 SG_ LKA_ASSIST : 62|1@1+ (1,0) [0|1] "" XXX
 SG_ LKA_MODE : 24|3@1+ (1,0) [0|7] "" XXX
 SG_ NEW_SIGNAL_2 : 70|2@0+ (1,0) [0|3] "" XXX
 SG_ HAS_LANE_SAFETY : 80|1@0+ (1,0) [0|1] "" XXX
 SG_ NEW_SIGNAL_3 : 111|8@0+ (1,0) [0|255] "" XXX

BO_ 304 GEAR_SHIFTER: 16 XXX
 SG_ CHECKSUM : 0|16@1+ (1,0) [0|65535] "" XXX
 SG_ COUNTER : 16|8@1+ (1,0) [0|255] "" XXX
 SG_ PARK_BUTTON : 32|2@1+ (1,0) [0|3] "" XXX
 SG_ GEAR : 64|3@1+ (1,0) [0|7] "" XXX
 SG_ KNOB_POSITION : 40|3@1+ (1,0) [0|3] "" XXX

BO_ 357 SPAS1: 24 APRK
 SG_ CHECKSUM : 0|16@1+ (1,0) [0|65535] "" XXX
 SG_ COUNTER : 16|8@1+ (1,0) [0|0] "" XXX
 SG_ NEW_SIGNAL_1 : 96|16@1- (0.1,0) [0|0] "" XXX
 SG_ NEW_SIGNAL_2 : 90|3@1+ (1,0) [0|0] "" XXX

BO_ 362 SPAS2: 32 APRK
 SG_ CHECKSUM : 0|16@1+ (1,0) [0|65535] "" XXX
 SG_ COUNTER : 16|8@1+ (1,0) [0|0] "" XXX
 SG_ BLINKER_CONTROL : 133|3@1+ (1,0) [0|0] "" XXX

BO_ 373 TCS: 24 XXX
 SG_ CHECKSUM : 0|16@1+ (1,0) [0|65535] "" XXX
 SG_ COUNTER : 16|8@1+ (1,0) [0|255] "" XXX
 SG_ NEW_SIGNAL_1 : 80|1@0+ (1,0) [0|1] "" XXX
 SG_ NEW_SIGNAL_2 : 74|1@0+ (1,0) [0|1] "" XXX
 SG_ NEW_SIGNAL_3 : 76|1@0+ (1,0) [0|1] "" XXX
 SG_ NEW_SIGNAL_4 : 24|7@1+ (1,0) [0|127] "" XXX
 SG_ aBasis : 32|11@1+ (0.01,-10.23) [0|7] "m/s^2" XXX
 SG_ NEW_SIGNAL_5 : 72|1@0+ (1,0) [0|1] "" XXX
 SG_ NEW_SIGNAL_6 : 128|4@1+ (1,0) [0|15] "" XXX
 SG_ NEW_SIGNAL_7 : 135|2@0+ (1,0) [0|3] "" XXX
 SG_ PROBABLY_EQUIP : 136|2@1+ (1,0) [0|3] "" XXX
 SG_ AEB_EQUIP_MAYBE : 96|1@0+ (1,0) [0|1] "" XXX
 SG_ EQUIP_MAYBE : 64|1@0+ (1,0) [0|1] "" XXX
 SG_ DriverBraking : 81|1@0+ (1,0) [0|1] "" XXX
 SG_ DriverBrakingLowSens : 84|1@1+ (1,0) [0|1] "" XXX
 SG_ ACC_REQ : 68|1@0+ (1,0) [0|1] "" XXX
 SG_ ACCEL_REF_ACC : 48|11@1- (1,0) [0|1023] "" XXX
 SG_ ACCEnable : 67|2@0+ (1,0) [0|3] "" XXX

BO_ 352 ADRV_0x160: 16 ADRV
 SG_ CHECKSUM : 0|16@1+ (1,0) [0|65535] "" XXX
 SG_ COUNTER : 16|8@1+ (1,0) [0|255] "" XXX
 SG_ SET_ME_FF : 64|8@1+ (1,0) [0|255] "" XXX
 SG_ SET_ME_FC : 72|8@1+ (1,0) [0|255] "" XXX
 SG_ SET_ME_2 : 56|8@1+ (1,0) [0|1] "" XXX
 SG_ AEB_SETTING : 24|2@1+ (1,0) [0|255] "" XXX
 SG_ SET_ME_9 : 80|8@1+ (1,0) [0|255] "" XXX

BO_ 384 CAM_0x180: 32 CAMERA
 SG_ CHECKSUM : 0|16@1+ (1,0) [0|65535] "" XXX
 SG_ COUNTER : 16|8@1+ (1,0) [0|255] "" XXX

BO_ 385 CAM_0x181: 32 CAMERA
 SG_ CHECKSUM : 0|16@1+ (1,0) [0|65535] "" XXX
 SG_ COUNTER : 16|8@1+ (1,0) [0|255] "" XXX

BO_ 386 CAM_0x182: 32 CAMERA
 SG_ CHECKSUM : 0|16@1+ (1,0) [0|65535] "" XXX
 SG_ COUNTER : 16|8@1+ (1,0) [0|255] "" XXX

BO_ 387 CAM_0x183: 32 CAMERA
 SG_ CHECKSUM : 0|16@1+ (1,0) [0|65535] "" XXX
 SG_ COUNTER : 16|8@1+ (1,0) [0|255] "" XXX

BO_ 388 CAM_0x184: 32 CAMERA
 SG_ CHECKSUM : 0|16@1+ (1,0) [0|65535] "" XXX
 SG_ COUNTER : 16|8@1+ (1,0) [0|255] "" XXX

BO_ 389 CAM_0x185: 8 CAMERA
 SG_ CHECKSUM : 0|16@1+ (1,0) [0|65535] "" XXX
 SG_ COUNTER : 16|8@1+ (1,0) [0|255] "" XXX

BO_ 416 SCC_CONTROL: 32 ADRV
 SG_ CHECKSUM : 0|16@1+ (1,0) [0|65535] "" XXX
 SG_ NEW_SIGNAL_1 : 64|2@1+ (1,0) [0|3] "" XXX
 SG_ NEW_SIGNAL_8 : 170|4@1+ (1,0) [0|15] "" XXX
 SG_ ZEROS : 215|48@0+ (1,0) [0|281474976710655] "" XXX
 SG_ ZEROS_3 : 191|7@0+ (1,0) [0|127] "" XXX
 SG_ ZEROS_4 : 183|4@0+ (1,0) [0|63] "" XXX
 SG_ ZEROS_6 : 119|16@0+ (1,0) [0|65535] "" XXX
 SG_ ZEROS_8 : 95|5@0+ (1,0) [0|31] "" XXX
 SG_ NEW_SIGNAL_3 : 109|2@0+ (1,0) [0|1] "" XXX
 SG_ SET_ME_TMP_64 : 55|8@0+ (1,0) [0|63] "" XXX
 SG_ SET_ME_2 : 105|3@1+ (1,0) [0|7] "" XXX
 SG_ NEW_SIGNAL_6 : 104|1@0+ (1,0) [0|1] "" XXX
 SG_ COUNTER : 16|8@1+ (1,0) [0|255] "" XXX
 SG_ ZEROS_9 : 71|5@1+ (1,0) [0|15] "" XXX
 SG_ ZEROS_10 : 111|2@0+ (1,0) [0|3] "" XXX
 SG_ SET_ME_3 : 45|2@0+ (1,0) [0|3] "" XXX
 SG_ ObjValid : 46|1@0+ (1,0) [0|3] "" XXX
 SG_ NEW_SIGNAL_2 : 168|2@1+ (1,0) [0|3] "" XXX
 SG_ OBJ_STATUS : 176|3@1+ (1,0) [0|7] "" XXX
 SG_ ACC_ObjDist : 24|11@1+ (0.1,0) [0|204.7] "m" XXX
 SG_ ZEROS_5 : 77|11@1+ (1,0) [0|2047] "" XXX
 SG_ DISTANCE_SETTING : 88|3@1+ (1,0) [0|3] "" XXX
 SG_ ZEROS_2 : 207|5@0+ (1,0) [0|63] "" XXX
 SG_ CRUISE_STANDSTILL : 76|1@1+ (1,0) [0|1] "" XXX
 SG_ aReqRaw : 140|11@1+ (0.01,-10.23) [-10.23|10.24] "m/s^2" XXX
 SG_ aReqValue : 128|11@1+ (0.01,-10.23) [-10.23|10.24] "m/s^2" XXX
 SG_ ZEROS_7 : 63|8@0+ (1,0) [0|255] "" XXX
 SG_ ACCMode : 68|3@1+ (1,0) [0|7] "" XXX
 SG_ ACC_ObjRelSpd : 35|9@1+ (0.1,-16.4) [-16.4|34.7] "m/s" XXX
 SG_ JerkLowerLimit : 166|7@0+ (0.1,0) [0|12.7] "m/s^3" XXX
 SG_ StopReq : 184|1@0+ (1,0) [0|1] "" XXX
 SG_ NEW_SIGNAL_15 : 192|11@1+ (0.1,0) [0|204.7] "m" XXX
 SG_ VSetDis : 103|8@0+ (1,0) [0|255] "km/h or mph" XXX
 SG_ MainMode_ACC : 66|1@1+ (1,0) [0|1] "" XXX
 SG_ JerkUpperLimit : 158|7@0+ (0.1,0) [0|0] "" XXX

BO_ 426 CRUISE_BUTTONS_ALT: 16 XXX
 SG_ CHECKSUM : 0|16@1+ (1,0) [0|65535] "" XXX
 SG_ COUNTER : 16|8@1+ (1,0) [0|255] "" XXX
 SG_ NEW_SIGNAL_1 : 24|4@1+ (1,0) [0|15] "" XXX
 SG_ SET_ME_1 : 28|2@1+ (1,0) [0|3] "" XXX
 SG_ DISTANCE_UNIT : 30|1@1+ (1,0) [0|1] "" XXX
 SG_ NEW_SIGNAL_2 : 31|3@1+ (1,0) [0|7] "" XXX
 SG_ ADAPTIVE_CRUISE_MAIN_BTN : 34|1@1+ (1,0) [0|1] "" XXX
 SG_ NEW_SIGNAL_3 : 35|1@1+ (1,0) [0|1] "" XXX
 SG_ LFA_BTN : 39|1@1+ (1,0) [0|1] "" XXX
 SG_ CRUISE_BUTTONS : 36|3@1+ (1,0) [0|4] "" XXX
 SG_ NEW_SIGNAL_4 : 40|1@1+ (1,0) [0|1] "" XXX
 SG_ NORMAL_CRUISE_MAIN_BTN : 41|1@1+ (1,0) [0|1] "" XXX
 SG_ NEW_SIGNAL_5 : 42|2@1+ (1,0) [0|3] "" XXX
 SG_ SET_ME_2 : 44|3@1+ (1,0) [0|7] "" XXX
 SG_ NEW_SIGNAL_6 : 47|1@1+ (1,0) [0|1] "" XXX
 SG_ BYTE6 : 48|8@1+ (1,0) [0|255] "" XXX
 SG_ BYTE7 : 56|8@1+ (1,0) [0|255] "" XXX
 SG_ BYTE8 : 64|8@1+ (1,0) [0|255] "" XXX
 SG_ BYTE9 : 72|8@1+ (1,0) [0|255] "" XXX
 SG_ BYTE10 : 80|8@1+ (1,0) [0|255] "" XXX
 SG_ BYTE11 : 88|8@1+ (1,0) [0|255] "" XXX
 SG_ BYTE12 : 96|8@1+ (1,0) [0|255] "" XXX
 SG_ BYTE13 : 104|8@1+ (1,0) [0|255] "" XXX
 SG_ BYTE14 : 112|8@1+ (1,0) [0|255] "" XXX
 SG_ BYTE15 : 120|8@1+ (1,0) [0|255] "" XXX

BO_ 438 CAM_0x1b6: 32 CAMERA
 SG_ CHECKSUM : 0|16@1+ (1,0) [0|65535] "" XXX
 SG_ COUNTER : 16|8@1+ (1,0) [0|255] "" XXX

BO_ 439 CAM_0x1b7: 32 CAMERA
 SG_ CHECKSUM : 0|16@1+ (1,0) [0|65535] "" XXX
 SG_ COUNTER : 16|8@1+ (1,0) [0|255] "" XXX

BO_ 440 CAM_0x1b8: 32 CAMERA
 SG_ CHECKSUM : 0|16@1+ (1,0) [0|65535] "" XXX
 SG_ COUNTER : 16|8@1+ (1,0) [0|255] "" XXX

BO_ 441 CAM_0x1b9: 32 CAMERA
 SG_ CHECKSUM : 0|16@1+ (1,0) [0|65535] "" XXX
 SG_ COUNTER : 16|8@1+ (1,0) [0|255] "" XXX

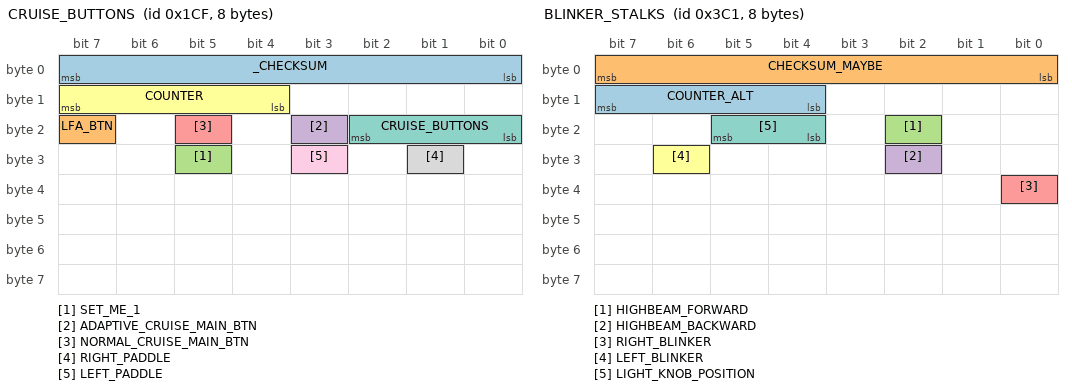
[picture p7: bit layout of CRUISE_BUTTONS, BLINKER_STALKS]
BO_ 463 CRUISE_BUTTONS: 8 XXX
 SG_ _CHECKSUM : 0|8@1+ (1,0) [0|65535] "" XXX
 SG_ LFA_BTN : 23|1@1+ (1,0) [0|1] "" XXX
 SG_ SET_ME_1 : 29|1@1+ (1,0) [0|1] "" XXX
 SG_ ADAPTIVE_CRUISE_MAIN_BTN : 19|1@1+ (1,0) [0|1] "" XXX
 SG_ NORMAL_CRUISE_MAIN_BTN : 21|1@1+ (1,0) [0|1] "" XXX
 SG_ COUNTER : 12|4@1+ (1,0) [0|255] "" XXX
 SG_ CRUISE_BUTTONS : 16|3@1+ (1,0) [0|3] "" XXX
 SG_ RIGHT_PADDLE : 25|1@1+ (1,0) [0|1] "" XXX
 SG_ LEFT_PADDLE : 27|1@1+ (1,0) [0|1] "" XXX

BO_ 474 ADRV_0x1da: 32 ADRV
 SG_ CHECKSUM : 0|16@1+ (1,0) [0|65535] "" XXX
 SG_ COUNTER : 16|8@1+ (1,0) [0|255] "" XXX
 SG_ SET_ME_22 : 31|8@0+ (1,0) [0|255] "" XXX
 SG_ SET_ME_41 : 47|8@0+ (1,0) [0|255] "" XXX

BO_ 480 LFAHDA_CLUSTER: 16 ADRV
 SG_ CHECKSUM : 0|16@1+ (1,0) [0|65535] "" XXX
 SG_ COUNTER : 16|8@1+ (1,0) [0|255] "" XXX
 SG_ HDA_ICON : 31|1@1+ (1,0) [0|1] "" XXX
 SG_ LFA_ICON : 47|2@1+ (1,0) [0|3] "" XXX
 SG_ NEW_SIGNAL_1 : 32|3@1+ (1,0) [0|7] "" XXX
 SG_ NEW_SIGNAL_2 : 30|1@0+ (1,0) [0|1] "" XXX
 SG_ NEW_SIGNAL_3 : 49|1@0+ (1,0) [0|1] "" XXX
 SG_ NEW_SIGNAL_4 : 24|1@0+ (1,0) [0|1] "" XXX

BO_ 490 ADRV_0x1ea: 32 ADRV
 SG_ CHECKSUM : 0|16@1+ (1,0) [0|65535] "" XXX
 SG_ COUNTER : 16|8@1+ (1,0) [0|255] "" XXX
 SG_ SET_ME_1C : 31|8@0+ (1,0) [0|255] "" XXX
 SG_ NEW_SIGNAL_1 : 32|2@1+ (1,0) [0|3] "" XXX
 SG_ NEW_SIGNAL_2 : 47|2@0+ (1,0) [0|3] "" XXX
 SG_ NEW_SIGNAL_3 : 55|8@0+ (1,0) [0|255] "" XXX
 SG_ NEW_SIGNAL_4 : 64|6@1+ (1,0) [0|31] "" XXX
 SG_ NEW_SIGNAL_5 : 72|2@1+ (1,0) [0|3] "" XXX
 SG_ NEW_SIGNAL_6 : 75|5@1+ (1,0) [0|31] "" XXX
 SG_ NEW_SIGNAL_7 : 80|5@1+ (1,0) [0|31] "" XXX
 SG_ NEW_SIGNAL_8 : 88|7@1+ (1,0) [0|127] "" XXX
 SG_ NEW_SIGNAL_9 : 96|1@0+ (1,0) [0|1] "" XXX
 SG_ NEW_SIGNAL_10 : 143|5@0+ (1,0) [0|31] "" XXX
 SG_ NEW_SIGNAL_11 : 144|3@1+ (1,0) [0|7] "" XXX
 SG_ NEW_SIGNAL_12 : 152|6@1+ (1,0) [0|63] "" XXX
 SG_ NEW_SIGNAL_13 : 160|1@0+ (1,0) [0|1] "" XXX
 SG_ NEW_SIGNAL_14 : 163|5@1+ (1,0) [0|31] "" XXX
 SG_ NEW_SIGNAL_15 : 175|4@0+ (1,0) [0|63] "" XXX
 SG_ NEW_SIGNAL_16 : 168|3@1+ (1,0) [0|7] "" XXX
 SG_ NEW_SIGNAL_17 : 176|2@1+ (1,0) [0|3] "" XXX
 SG_ NEW_SIGNAL_18 : 184|1@0+ (1,0) [0|1] "" XXX
 SG_ NEW_SIGNAL_19 : 208|3@1+ (1,0) [0|7] "" XXX
 SG_ NEW_SIGNAL_20 : 212|1@0+ (1,0) [0|1] "" XXX
 SG_ SET_ME_FF : 120|8@1+ (1,0) [0|255] "" XXX
 SG_ SET_ME_TMP_F : 232|5@1+ (1,0) [0|31] "" XXX
 SG_ SET_ME_TMP_F_2 : 240|5@1+ (1,0) [0|31] "" XXX

BO_ 507 CAM_0x1fb: 32 CAMERA
 SG_ CHECKSUM : 0|16@1+ (1,0) [0|65535] "" XXX
 SG_ COUNTER : 16|8@1+ (1,0) [0|255] "" XXX

BO_ 512 ADRV_0x200: 8 ADRV
 SG_ CHECKSUM : 0|16@1+ (1,0) [0|65535] "" XXX
 SG_ COUNTER : 16|8@1+ (1,0) [0|255] "" XXX
 SG_ SET_ME_E1 : 24|8@1+ (1,0) [0|255] "" XXX
 SG_ SET_ME_3A : 32|8@1+ (1,0) [0|255] "" XXX

BO_ 513 RADAR_0x201: 32 FRONT_RADAR
 SG_ CHECKSUM : 0|16@1+ (1,0) [0|65535] "" XXX
 SG_ COUNTER : 16|8@1+ (1,0) [0|255] "" XXX

BO_ 528 RADAR_0x210: 32 FRONT_RADAR
 SG_ CHECKSUM : 0|16@1+ (1,0) [0|65535] "" XXX
 SG_ COUNTER : 16|8@1+ (1,0) [0|255] "" XXX

BO_ 529 RADAR_0x211: 32 FRONT_RADAR
 SG_ CHECKSUM : 0|16@1+ (1,0) [0|65535] "" XXX
 SG_ COUNTER : 16|8@1+ (1,0) [0|255] "" XXX

BO_ 530 RADAR_0x212: 32 FRONT_RADAR
 SG_ CHECKSUM : 0|16@1+ (1,0) [0|65535] "" XXX
 SG_ COUNTER : 16|8@1+ (1,0) [0|255] "" XXX

BO_ 531 RADAR_0x213: 32 FRONT_RADAR
 SG_ CHECKSUM : 0|16@1+ (1,0) [0|65535] "" XXX
 SG_ COUNTER : 16|8@1+ (1,0) [0|255] "" XXX

BO_ 532 RADAR_0x214: 32 FRONT_RADAR
 SG_ CHECKSUM : 0|16@1+ (1,0) [0|65535] "" XXX
 SG_ COUNTER : 16|8@1+ (1,0) [0|255] "" XXX

BO_ 533 RADAR_0x215: 32 FRONT_RADAR
 SG_ CHECKSUM : 0|16@1+ (1,0) [0|65535] "" XXX
 SG_ COUNTER : 16|8@1+ (1,0) [0|255] "" XXX

BO_ 534 RADAR_0x216: 32 FRONT_RADAR
 SG_ CHECKSUM : 0|16@1+ (1,0) [0|65535] "" XXX
 SG_ COUNTER : 16|8@1+ (1,0) [0|255] "" XXX

BO_ 535 RADAR_0x217: 32 FRONT_RADAR
 SG_ CHECKSUM : 0|16@1+ (1,0) [0|65535] "" XXX
 SG_ COUNTER : 16|8@1+ (1,0) [0|255] "" XXX

BO_ 536 RADAR_0x218: 32 FRONT_RADAR
 SG_ CHECKSUM : 0|16@1+ (1,0) [0|65535] "" XXX
 SG_ COUNTER : 16|8@1+ (1,0) [0|255] "" XXX

BO_ 537 RADAR_0x219: 32 FRONT_RADAR
 SG_ CHECKSUM : 0|16@1+ (1,0) [0|65535] "" XXX
 SG_ COUNTER : 16|8@1+ (1,0) [0|255] "" XXX

BO_ 538 RADAR_0x21a: 32 FRONT_RADAR
 SG_ CHECKSUM : 0|16@1+ (1,0) [0|65535] "" XXX
 SG_ COUNTER : 16|8@1+ (1,0) [0|255] "" XXX

BO_ 539 RADAR_0x21b: 32 FRONT_RADAR
 SG_ CHECKSUM : 0|16@1+ (1,0) [0|65535] "" XXX
 SG_ COUNTER : 16|8@1+ (1,0) [0|255] "" XXX

BO_ 540 RADAR_0x21c: 32 FRONT_RADAR
 SG_ CHECKSUM : 0|16@1+ (1,0) [0|65535] "" XXX
 SG_ COUNTER : 16|8@1+ (1,0) [0|255] "" XXX

BO_ 541 RADAR_0x21d: 32 FRONT_RADAR
 SG_ CHECKSUM : 0|16@1+ (1,0) [0|65535] "" XXX
 SG_ COUNTER : 16|8@1+ (1,0) [0|255] "" XXX

BO_ 542 RADAR_0x21e: 32 FRONT_RADAR
 SG_ CHECKSUM : 0|16@1+ (1,0) [0|65535] "" XXX
 SG_ COUNTER : 16|8@1+ (1,0) [0|255] "" XXX

BO_ 543 RADAR_0x21f: 32 FRONT_RADAR
 SG_ CHECKSUM : 0|16@1+ (1,0) [0|65535] "" XXX
 SG_ COUNTER : 16|8@1+ (1,0) [0|255] "" XXX

BO_ 576 RADAR_0x240: 16 FRONT_RADAR
 SG_ CHECKSUM : 0|16@1+ (1,0) [0|65535] "" XXX
 SG_ COUNTER : 16|8@1+ (1,0) [0|255] "" XXX

BO_ 593 RADAR_0x251: 16 FRONT_RADAR
 SG_ CHECKSUM : 0|16@1+ (1,0) [0|65535] "" XXX
 SG_ COUNTER : 16|8@1+ (1,0) [0|255] "" XXX

BO_ 674 CAM_0x2a2: 32 CAMERA
 SG_ CHECKSUM : 0|16@1+ (1,0) [0|65535] "" XXX
 SG_ COUNTER : 16|8@1+ (1,0) [0|255] "" XXX

BO_ 675 CAM_0x2a3: 32 CAMERA
 SG_ CHECKSUM : 0|16@1+ (1,0) [0|65535] "" XXX
 SG_ COUNTER : 16|8@1+ (1,0) [0|255] "" XXX

BO_ 676 CAM_0x2a4: 24 XXX
 SG_ CHECKSUM : 0|16@1+ (1,0) [0|65535] "" XXX
 SG_ COUNTER : 16|8@1+ (1,0) [0|255] "" XXX
 SG_ BYTE3 : 24|8@1+ (1,0) [0|255] "" XXX
 SG_ BYTE4 : 32|8@1+ (1,0) [0|255] "" XXX
 SG_ BYTE5 : 40|8@1+ (1,0) [0|255] "" XXX
 SG_ BYTE6 : 48|8@1+ (1,0) [0|255] "" XXX
 SG_ LEFT_LANE_LINE : 56|2@1+ (1,0) [0|3] "" XXX
 SG_ SET_ME_0 : 58|2@1+ (1,0) [0|3] "" XXX
 SG_ RIGHT_LANE_LINE : 60|2@1+ (1,0) [0|3] "" XXX
 SG_ SET_ME_0_2 : 62|2@1+ (1,0) [0|3] "" XXX
 SG_ BYTE8 : 64|8@1+ (1,0) [0|255] "" XXX
 SG_ BYTE9 : 72|8@1+ (1,0) [0|255] "" XXX
 SG_ BYTE10 : 80|8@1+ (1,0) [0|255] "" XXX
 SG_ BYTE11 : 88|8@1+ (1,0) [0|255] "" XXX
 SG_ BYTE12 : 96|8@1+ (1,0) [0|255] "" XXX
 SG_ BYTE13 : 104|8@1+ (1,0) [0|255] "" XXX
 SG_ BYTE14 : 112|8@1+ (1,0) [0|255] "" XXX
 SG_ BYTE15 : 120|8@1+ (1,0) [0|255] "" XXX
 SG_ BYTE16 : 128|8@1+ (1,0) [0|255] "" XXX
 SG_ BYTE17 : 136|8@1+ (1,0) [0|255] "" XXX
 SG_ BYTE18 : 144|8@1+ (1,0) [0|255] "" XXX
 SG_ BYTE19 : 152|8@1+ (1,0) [0|255] "" XXX
 SG_ BYTE20 : 160|8@1+ (1,0) [0|255] "" XXX
 SG_ BYTE21 : 168|8@1+ (1,0) [0|255] "" XXX
 SG_ BYTE22 : 176|8@1+ (1,0) [0|255] "" XXX
 SG_ BYTE23 : 184|8@1+ (1,0) [0|255] "" XXX

BO_ 699 CAM_0x2bb: 32 CAMERA
 SG_ CHECKSUM : 0|16@1+ (1,0) [0|65535] "" XXX
 SG_ COUNTER : 16|8@1+ (1,0) [0|255] "" XXX

BO_ 700 CAM_0x2bc: 32 CAMERA
 SG_ CHECKSUM : 0|16@1+ (1,0) [0|65535] "" XXX
 SG_ COUNTER : 16|8@1+ (1,0) [0|255] "" XXX

BO_ 701 CAM_0x2bd: 32 CAMERA
 SG_ CHECKSUM : 0|16@1+ (1,0) [0|65535] "" XXX
 SG_ COUNTER : 16|8@1+ (1,0) [0|255] "" XXX

BO_ 702 CAM_0x2be: 32 CAMERA
 SG_ CHECKSUM : 0|16@1+ (1,0) [0|65535] "" XXX
 SG_ COUNTER : 16|8@1+ (1,0) [0|255] "" XXX

BO_ 736 MANUAL_SPEED_LIMIT_ASSIST: 32 XXX
 SG_ CHECKSUM : 0|16@1+ (1,0) [0|65535] "" XXX
 SG_ COUNTER : 16|8@1+ (1,0) [0|255] "" XXX
 SG_ MSLA_STATUS : 26|2@1+ (1,0) [0|3] "" XXX
 SG_ MSLA_ENABLED : 38|1@1+ (1,0) [0|1] "" XXX
 SG_ MAX_SPEED : 55|8@0+ (1,0) [0|255] "" XXX
 SG_ MAX_SPEED_COPY : 144|8@1+ (1,0) [0|255] "" XXX

BO_ 837 ADRV_0x345: 8 ADRV
 SG_ CHECKSUM : 0|16@1+ (1,0) [0|65535] "" XXX
 SG_ COUNTER : 16|8@1+ (1,0) [0|255] "" XXX
 SG_ SET_ME_15 : 24|8@1+ (1,0) [0|255] "" XXX

BO_ 866 CAM_0x362: 32 CAMERA
 SG_ CHECKSUM : 0|16@1+ (1,0) [0|65535] "" XXX
 SG_ COUNTER : 16|8@1+ (1,0) [0|255] "" XXX
 SG_ BYTE3 : 24|8@1+ (1,0) [0|255] "" XXX
 SG_ BYTE4 : 32|8@1+ (1,0) [0|255] "" XXX
 SG_ BYTE5 : 40|8@1+ (1,0) [0|255] "" XXX
 SG_ BYTE6 : 48|8@1+ (1,0) [0|255] "" XXX
 SG_ LEFT_LANE_LINE : 56|2@1+ (1,0) [0|3] "" XXX
 SG_ SET_ME_0 : 58|2@1+ (1,0) [0|3] "" XXX
 SG_ RIGHT_LANE_LINE : 60|2@1+ (1,0) [0|3] "" XXX
 SG_ SET_ME_0_2 : 62|2@1+ (1,0) [0|3] "" XXX
 SG_ BYTE8 : 64|8@1+ (1,0) [0|255] "" XXX
 SG_ BYTE9 : 72|8@1+ (1,0) [0|255] "" XXX
 SG_ BYTE10 : 80|8@1+ (1,0) [0|255] "" XXX
 SG_ BYTE11 : 88|8@1+ (1,0) [0|255] "" XXX
 SG_ BYTE12 : 96|8@1+ (1,0) [0|255] "" XXX
 SG_ BYTE13 : 104|8@1+ (1,0) [0|255] "" XXX
 SG_ BYTE14 : 112|8@1+ (1,0) [0|255] "" XXX
 SG_ BYTE15 : 120|8@1+ (1,0) [0|255] "" XXX
 SG_ BYTE16 : 128|8@1+ (1,0) [0|255] "" XXX
 SG_ BYTE17 : 136|8@1+ (1,0) [0|255] "" XXX
 SG_ BYTE18 : 144|8@1+ (1,0) [0|255] "" XXX
 SG_ BYTE19 : 152|8@1+ (1,0) [0|255] "" XXX
 SG_ BYTE20 : 160|8@1+ (1,0) [0|255] "" XXX
 SG_ BYTE21 : 168|8@1+ (1,0) [0|255] "" XXX
 SG_ BYTE22 : 176|8@1+ (1,0) [0|255] "" XXX
 SG_ BYTE23 : 184|8@1+ (1,0) [0|255] "" XXX
 SG_ BYTE24 : 192|8@1+ (1,0) [0|255] "" XXX
 SG_ BYTE25 : 200|8@1+ (1,0) [0|255] "" XXX
 SG_ BYTE26 : 208|8@1+ (1,0) [0|255] "" XXX
 SG_ BYTE27 : 216|8@1+ (1,0) [0|255] "" XXX
 SG_ BYTE28 : 224|8@1+ (1,0) [0|255] "" XXX
 SG_ BYTE29 : 232|8@1+ (1,0) [0|255] "" XXX
 SG_ BYTE30 : 240|8@1+ (1,0) [0|255] "" XXX
 SG_ BYTE31 : 248|8@1+ (1,0) [0|255] "" XXX

BO_ 961 BLINKER_STALKS: 8 XXX
 SG_ COUNTER_ALT : 15|4@0+ (1,0) [0|15] "" XXX
 SG_ CHECKSUM_MAYBE : 7|8@0+ (1,0) [0|255] "" XXX
 SG_ HIGHBEAM_FORWARD : 18|1@0+ (1,0) [0|1] "" XXX
 SG_ HIGHBEAM_BACKWARD : 26|1@0+ (1,0) [0|1] "" XXX
 SG_ RIGHT_BLINKER : 32|1@0+ (1,0) [0|1] "" XXX
 SG_ LEFT_BLINKER : 30|1@0+ (1,0) [0|1] "" XXX
 SG_ LIGHT_KNOB_POSITION : 21|2@0+ (1,0) [0|3] "" XXX

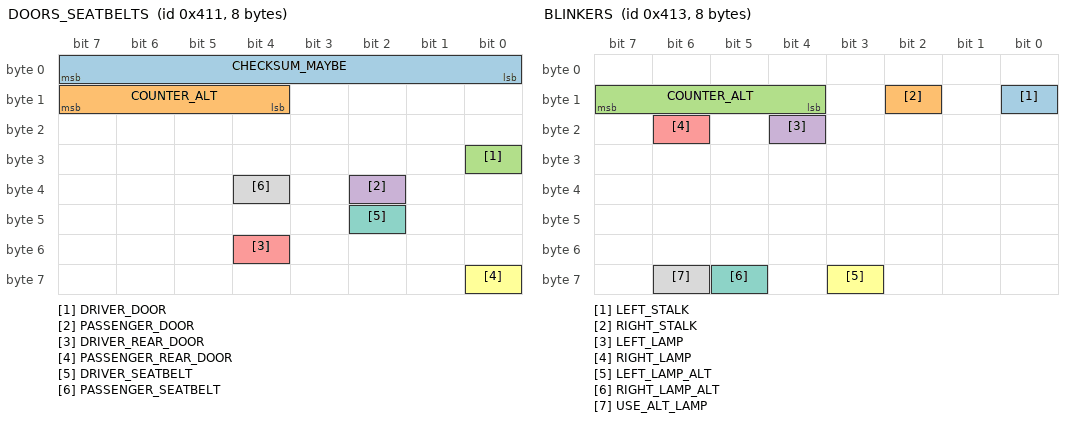
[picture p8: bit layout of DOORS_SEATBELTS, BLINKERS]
BO_ 1041 DOORS_SEATBELTS: 8 XXX
 SG_ CHECKSUM_MAYBE : 7|8@0+ (1,0) [0|65535] "" XXX
 SG_ COUNTER_ALT : 15|4@0+ (1,0) [0|15] "" XXX
 SG_ DRIVER_DOOR : 24|1@1+ (1,0) [0|1] "" XXX
 SG_ PASSENGER_DOOR : 34|1@0+ (1,0) [0|1] "" XXX
 SG_ DRIVER_REAR_DOOR : 52|1@0+ (1,0) [0|1] "" XXX
 SG_ PASSENGER_REAR_DOOR : 56|1@0+ (1,0) [0|1] "" XXX
 SG_ DRIVER_SEATBELT : 42|1@0+ (1,0) [0|1] "" XXX
 SG_ PASSENGER_SEATBELT : 36|1@0+ (1,0) [0|1] "" XXX

BO_ 1043 BLINKERS: 8 XXX
 SG_ LEFT_STALK : 8|1@0+ (1,0) [0|1] "" XXX
 SG_ RIGHT_STALK : 10|1@0+ (1,0) [0|1] "" XXX
 SG_ COUNTER_ALT : 15|4@0+ (1,0) [0|15] "" XXX
 SG_ LEFT_LAMP : 20|1@0+ (1,0) [0|1] "" XXX
 SG_ RIGHT_LAMP : 22|1@0+ (1,0) [0|1] "" XXX
 SG_ LEFT_LAMP_ALT : 59|1@0+ (1,0) [0|1] "" XXX
 SG_ RIGHT_LAMP_ALT : 61|1@0+ (1,0) [0|1] "" XXX
 SG_ USE_ALT_LAMP : 62|1@0+ (1,0) [0|1] "" XXX

BO_ 1240 CLUSTER_INFO: 8 XXX
 SG_ DISTANCE_UNIT : 0|1@1+ (1,0) [0|1] "" XXX

BO_ 442 BLINDSPOTS_REAR_CORNERS: 24 XXX
 SG_ COUNTER : 16|8@1+ (1,0) [0|255] "" XXX
 SG_ CHECKSUM : 0|16@1+ (1,0) [0|65535] "" XXX
 SG_ NEW_SIGNAL_2 : 96|1@0+ (1,0) [0|1] "" XXX
 SG_ COLLISION_AVOIDANCE_ACTIVE : 68|1@0+ (1,0) [0|1] "" XXX
 SG_ LEFT_MB : 30|1@0+ (1,0) [0|3] "" XXX
 SG_ LEFT_BLOCKED : 24|1@0+ (1,0) [0|1] "" XXX
 SG_ MORE_LEFT_PROB : 32|1@1+ (1,0) [0|3] "" XXX
 SG_ FL_INDICATOR : 46|6@0+ (1,0) [0|1] "" XXX
 SG_ FR_INDICATOR : 54|6@0+ (1,0) [0|63] "" XXX
 SG_ RIGHT_BLOCKED : 64|1@0+ (1,0) [0|1] "" XXX
 SG_ FL_INDICATOR_ALT : 138|1@0+ (1,0) [0|1] "" XXX
 SG_ FR_INDICATOR_ALT : 141|1@0+ (1,0) [0|1] "" XXX

BO_ 874 BLINDSPOTS_FRONT_CORNER_2: 16 XXX
 SG_ COUNTER : 16|8@1+ (1,0) [0|255] "" XXX
 SG_ CHECKSUM : 0|16@1+ (1,0) [0|65535] "" XXX

BO_ 485 BLINDSPOTS_FRONT_CORNER_1: 16 XXX
 SG_ COUNTER : 16|8@1+ (1,0) [0|255] "" XXX
 SG_ CHECKSUM : 0|16@1+ (1,0) [0|65535] "" XXX
 SG_ NEW_SIGNAL_1 : 108|2@0+ (1,0) [0|3] "" XXX
 SG_ NEW_SIGNAL_2 : 96|1@0+ (1,0) [0|1] "" XXX
 SG_ NEW_SIGNAL_3 : 88|1@0+ (1,0) [0|1] "" XXX
 SG_ NEW_SIGNAL_4 : 80|1@0+ (1,0) [0|1] "" XXX
 SG_ NEW_SIGNAL_5 : 31|2@0+ (1,0) [0|3] "" XXX
 SG_ REVERSING : 24|1@0+ (1,0) [0|1] "" XXX
 SG_ NEW_SIGNAL_7 : 32|2@1+ (1,0) [0|3] "" XXX
 SG_ NEW_SIGNAL_8 : 47|8@0+ (1,0) [0|255] "" XXX
 SG_ NEW_SIGNAL_9 : 55|8@0+ (1,0) [0|255] "" XXX

BO_ 506 CLUSTER_SPEED_LIMIT: 32 XXX
 SG_ SPEED_LIMIT_3 : 119|8@0+ (1,0) [0|255] "" XXX
 SG_ SPEED_LIMIT_2 : 47|7@0+ (1,0) [0|255] "" XXX
 SG_ SPEED_LIMIT_1 : 39|7@0+ (1,0) [0|255] "" XXX
 SG_ SPEED_CHANGE_BLINKING : 129|1@1+ (1,0) [0|3] "" XXX
 SG_ CHIME_2 : 122|2@1+ (1,0) [0|7] "" XXX
 SG_ CHIME_1 : 133|1@0+ (1,0) [0|1] "" XXX
 SG_ ARROW_DOWN : 120|1@0+ (1,0) [0|1] "" XXX
 SG_ ARROW_UP : 121|1@0+ (1,0) [0|1] "" XXX
 SG_ SECONDARY_LIMIT_1 : 79|8@0+ (1,0) [0|127] "" XXX
 SG_ SECONDARY_LIMIT_2 : 103|8@0+ (1,0) [0|127] "" XXX
 SG_ SCHOOL_ZONE : 155|1@0+ (1,0) [0|1] "" XXX

BO_ 1144 DRIVE_MODE: 8 XXX
 SG_ DRIVE_MODE : 0|16@1+ (1,-61611) [0|61611] "" XXX
 SG_ DRIVE_MODE2 : 28|3@1+ (1,0) [1|3] "" XXX

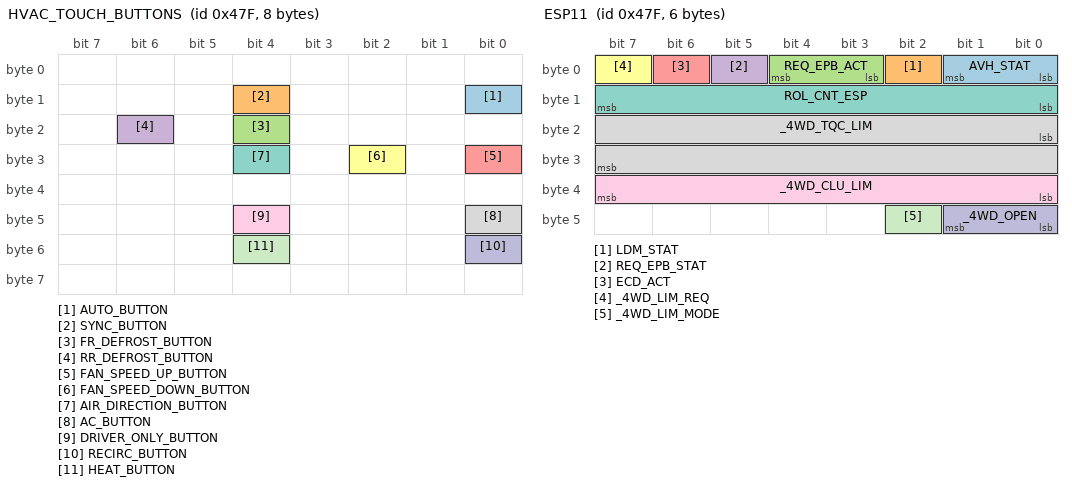
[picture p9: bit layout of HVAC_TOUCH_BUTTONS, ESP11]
BO_ 1151 HVAC_TOUCH_BUTTONS: 8 XXX
 SG_ AUTO_BUTTON : 8|1@0+ (1,0) [0|1] "" XXX
 SG_ SYNC_BUTTON : 12|1@0+ (1,0) [0|1] "" XXX
 SG_ FR_DEFROST_BUTTON : 20|1@0+ (1,0) [0|1] "" XXX
 SG_ RR_DEFROST_BUTTON : 22|1@0+ (1,0) [0|1] "" XXX
 SG_ FAN_SPEED_UP_BUTTON : 24|1@0+ (1,0) [0|1] "" XXX
 SG_ FAN_SPEED_DOWN_BUTTON : 26|1@0+ (1,0) [0|1] "" XXX
 SG_ AIR_DIRECTION_BUTTON : 28|1@0+ (1,0) [0|1] "" XXX
 SG_ AC_BUTTON : 40|1@0+ (1,0) [0|1] "" XXX
 SG_ DRIVER_ONLY_BUTTON : 44|1@0+ (1,0) [0|1] "" XXX
 SG_ RECIRC_BUTTON : 48|1@0+ (1,0) [0|1] "" XXX
 SG_ HEAT_BUTTON : 52|1@0+ (1,0) [0|1] "" XXX

BO_ 1259 LOCAL_TIME2: 8 XXX
 SG_ HOURS : 15|5@0+ (1,0) [0|31] "" XXX
 SG_ MINUTES : 21|6@0+ (1,0) [0|63] "" XXX
 SG_ SECONDS : 24|6@1+ (1,0) [0|63] "" XXX
 SG_ NEW_SIGNAL_3 : 39|1@0+ (1,0) [0|1] "" XXX

BO_ 1264 LOCAL_TIME: 8 XXX
 SG_ HOURS : 12|5@0+ (1,0) [0|31] "" XXX
 SG_ MINUTES : 21|6@0+ (1,0) [0|63] "" XXX
 SG_ SECONDS : 31|8@0+ (1,0) [0|59] "" XXX

CM_ 272 "Alternative LKAS message, used on cars such as 2023 Ioniq 6, 2nd gen Kona. Matches LKAS except size is 32 bytes";
BA_
 CAT_DEF_
 CAT_
 FILTER
 BA_DEF_DEF_
 EV_DATA_
 ENVVAR_DATA_
 SGTYPE_
 SGTYPE_VAL_
 BA_DEF_SGTYPE_
 BA_SGTYPE_
 SIG_TYPE_REF_
 VAL_TABLE_
 SIG_GROUP_
 SIG_VALTYPE_
 SIGTYPE_VALTYPE_
 BO_TX_BU_
 BA_DEF_REL_
 BA_REL_
 BA_DEF_DEF_REL_
 BU_SG_REL_
 BU_EV_REL_
 BU_BO_REL_
 SG_MUL_VAL_

BS_:

BU_: IAP ODS _4WD BCM HUD DATC MDPS AAF_Tester AEMC SMK _4WD EPB CUBIS MTS TMU EVP CGW TPMS LPI DI_BOX SPAS EMS LCA TCU IBOX FATC AFLS FPCM SCC AHLS AVM ABS SNV OPI PGS SAS AAF Dummy LDWS_LKAS LVR ESC PSB CLU ECS ACU REA

BO_ 387 REA11: 8 REA
 SG_ CF_EndBst_PwmDuH : 0|1@1+ (1.0,0.0) [0.0|1.0] ""  EMS
 SG_ CF_EndBst_PwmDuL : 1|1@1+ (1.0,0.0) [0.0|1.0] ""  EMS
 SG_ CF_EndBst_PwmFqOutRng : 2|1@1+ (1.0,0.0) [0.0|1.0] ""  EMS
 SG_ CF_EndBst_HbriOverCur : 3|1@1+ (1.0,0.0) [0.0|1.0] ""  EMS
 SG_ CF_EndBst_HbriOverTemp : 4|1@1+ (1.0,0.0) [0.0|1.0] ""  EMS
 SG_ CF_EndBst_PosSnsKOR : 6|1@1+ (1.0,0.0) [0.0|1.0] ""  EMS
 SG_ CF_EndBst_PosSnsOSOR : 7|1@1+ (1.0,0.0) [0.0|1.0] ""  EMS
 SG_ CF_EndBst_EepFlt : 8|1@1+ (1.0,0.0) [0.0|1.0] ""  EMS
 SG_ CF_EndBst_RomFlt : 9|1@1+ (1.0,0.0) [0.0|1.0] ""  EMS
 SG_ CF_EndBst_RamFlt : 10|1@1+ (1.0,0.0) [0.0|1.0] ""  EMS
 SG_ CF_EndBst_CanFlt : 11|1@1+ (1.0,0.0) [0.0|1.0] ""  EMS
 SG_ CF_EndBst_AgH : 12|1@1+ (1.0,0.0) [0.0|1.0] ""  EMS
 SG_ CF_EndBst_AgL : 13|1@1+ (1.0,0.0) [0.0|1.0] ""  EMS
 SG_ CF_EndBst_ORVol : 14|1@1+ (1.0,0.0) [0.0|1.0] ""  EMS
 SG_ CR_EndBst_ActPos : 16|16@1+ (0.117,0.0) [1.989|118.053] ""  EMS
 SG_ CR_EndBst_DemPos : 32|16@1+ (0.117,0.0) [0.0|119.691] ""  EMS
 SG_ CR_EndBst_HbriPwr : 48|16@1+ (0.045,0.0) [0.0|99.99] "%"  EMS

BO_ 1151 ESP11: 6 ESC
 SG_ AVH_STAT : 0|2@1+ (1.0,0.0) [0.0|3.0] ""  EMS,EPB,TCU
 SG_ LDM_STAT : 2|1@1+ (1.0,0.0) [0.0|1.0] ""  EPB,TCU
 SG_ REQ_EPB_ACT : 3|2@1+ (1.0,0.0) [0.0|3.0] ""  EPB,TCU
 SG_ REQ_EPB_STAT : 5|1@1+ (1.0,0.0) [0.0|1.0] ""  EPB
 SG_ ECD_ACT : 6|1@1+ (1.0,0.0) [0.0|1.0] ""  EPB
 SG_ _4WD_LIM_REQ : 7|1@1+ (1.0,0.0) [0.0|1.0] ""  _4WD,EMS
 SG_ ROL_CNT_ESP : 8|8@1+ (1.0,0.0) [0.0|255.0] ""  EPB,TCU
 SG_ _4WD_TQC_LIM : 16|16@1+ (1.0,0.0) [0.0|65535.0] "Nm"  _4WD,EMS
 SG_ _4WD_CLU_LIM : 32|8@1+ (0.390625,0.0) [0.0|99.609375] "%"  _4WD,EMS
 SG_ _4WD_OPEN : 40|2@1+ (1.0,0.0) [0.0|3.0] ""  _4WD,EMS
 SG_ _4WD_LIM_MODE : 42|1@1+ (1.0,0.0) [0.0|1.0] ""  _4WD

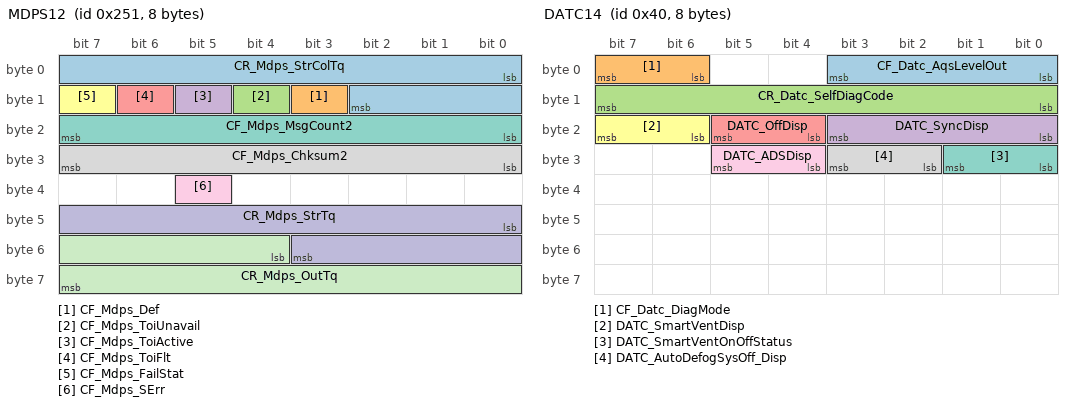
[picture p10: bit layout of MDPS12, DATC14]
BO_ 593 MDPS12: 8 MDPS
 SG_ CR_Mdps_StrColTq : 0|11@1+ (1.0,-1024.0) [-1024.0|1024.0] ""  LDWS_LKAS
 SG_ CF_Mdps_Def : 11|1@1+ (1.0,0.0) [0.0|1.0] ""  ESC
 SG_ CF_Mdps_ToiUnavail : 12|1@1+ (1.0,0.0) [0.0|1.0] ""  LDWS_LKAS
 SG_ CF_Mdps_ToiActive : 13|1@1+ (1.0,0.0) [0.0|1.0] ""  LDWS_LKAS
 SG_ CF_Mdps_ToiFlt : 14|1@1+ (1.0,0.0) [0.0|1.0] ""  LDWS_LKAS
 SG_ CF_Mdps_FailStat : 15|1@1+ (1.0,0.0) [0.0|1.0] ""  LDWS_LKAS
 SG_ CF_Mdps_MsgCount2 : 16|8@1+ (1.0,0.0) [0.0|255.0] ""  ESC,LDWS_LKAS
 SG_ CF_Mdps_Chksum2 : 24|8@1+ (1.0,0.0) [0.0|255.0] ""  ESC,LDWS_LKAS
 SG_ CF_Mdps_SErr : 37|1@1+ (1.0,0.0) [0.0|1.0] ""  ESC
 SG_ CR_Mdps_StrTq : 40|12@1+ (0.01,-20.48) [-20.48|20.47] "Nm"  ESC
 SG_ CR_Mdps_OutTq : 52|12@1+ (0.1,-204.8) [-204.8|204.7] ""  ESC,LDWS_LKAS

BO_ 64 DATC14: 8 DATC
 SG_ CF_Datc_AqsLevelOut : 0|4@1+ (1.0,0.0) [0.0|3.0] ""  CLU
 SG_ CF_Datc_DiagMode : 6|2@1+ (1.0,0.0) [0.0|3.0] ""  CLU
 SG_ CR_Datc_SelfDiagCode : 8|8@1+ (1.0,-1.0) [0.0|254.0] ""  CLU
 SG_ DATC_SyncDisp : 16|4@1+ (1.0,0.0) [0.0|3.0] ""  CLU
 SG_ DATC_OffDisp : 20|2@1+ (1.0,0.0) [0.0|3.0] ""  CLU
 SG_ DATC_SmartVentDisp : 22|2@1+ (1.0,0.0) [0.0|3.0] ""  CLU
 SG_ DATC_SmartVentOnOffStatus : 24|2@1+ (1.0,0.0) [0.0|3.0] ""  CLU
 SG_ DATC_AutoDefogSysOff_Disp : 26|2@1+ (1.0,0.0) [0.0|3.0] ""  CLU
 SG_ DATC_ADSDisp : 28|2@1+ (1.0,0.0) [0.0|3.0] ""  CLU

BO_ 512 EMS20: 6 EMS
 SG_ FCO : 0|16@1+ (0.128,0.0) [0.0|8388.48] "ul"  CLU,CUBIS,FPCM,IBOX
 SG_ CF_Ems_PumpTPres : 16|8@1+ (3.137254902,0.0) [0.0|800.0] "kPa"  FPCM,IBOX
 SG_ Split_Stat : 32|1@1+ (1.0,0.0) [0.0|1.0] ""  FPCM

BO_ 357 S_MDPS12: 8 XXX
 SG_ NEW_SIGNAL_1 : 0|12@1+ (1,0) [0|4095] "" XXX
 SG_ NEW_SIGNAL_2 : 12|12@1+ (1,0) [0|4095] "" XXX
 SG_ Counter : 48|4@1+ (1,0) [0|15] "" XXX
 SG_ Checksum : 63|8@0+ (1,0) [0|255] "" XXX

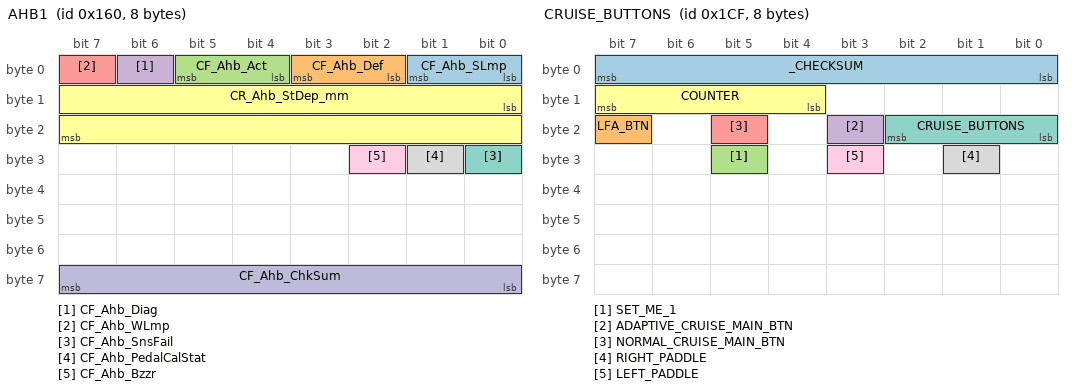
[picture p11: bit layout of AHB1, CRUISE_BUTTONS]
BO_ 352 AHB1: 8 iBAU
 SG_ CF_Ahb_SLmp : 0|2@1+ (1,0) [0|3] "" CLU
 SG_ CF_Ahb_Def : 2|2@1+ (1,0) [0|3] "" CGW
 SG_ CF_Ahb_Act : 4|2@1+ (1,0) [0|3] "" Vector__XXX
 SG_ CF_Ahb_Diag : 6|1@1+ (1,0) [0|1] "" Vector__XXX
 SG_ CF_Ahb_WLmp : 7|1@1+ (1,0) [0|1] "" CLU
 SG_ CR_Ahb_StDep_mm : 8|16@1- (0.1,0) [-3276.8|3276.7] "mm" Vector__XXX
 SG_ CF_Ahb_SnsFail : 24|1@1+ (1,0) [0|1] "" Vector__XXX
 SG_ CF_Ahb_PedalCalStat : 25|1@1+ (1,0) [0|1] "" Vector__XXX
 SG_ CF_Ahb_Bzzr : 26|1@1+ (1,0) [0|1] "" Vector__XXX
 SG_ CF_Ahb_ChkSum : 56|8@1+ (1,0) [0|255] "" Vector__XXX

BO_ 304 YRS11: 8 ACU
 SG_ CR_Yrs_Yr : 0|16@1+ (0.005,-163.84) [-163.84|163.83] "deg/s" CGW,iBAU
 SG_ CR_Yrs_LatAc : 16|16@1+ (0.000127465,-4.17677312) [-4.17677312|4.17651819] "g" iBAU
 SG_ CF_Yrs_YrStat : 32|4@1+ (1,0) [0|15] "" iBAU
 SG_ CF_Yrs_LatAcStat : 36|4@1+ (1,0) [0|15] "" iBAU
 SG_ CF_Yrs_MCUStat : 40|4@1+ (1,0) [0|15] "" iBAU
 SG_ CR_Yrs_MsgCnt1 : 48|4@1+ (1,0) [0|15] "" iBAU
 SG_ CR_Yrs_Crc1 : 56|8@1+ (1,0) [0|255] "" iBAU

CM_ "BO_ E_EMS11: All (plug-in) hybrids use this gas signal: CR_Vcu_AccPedDep_Pos, and all EVs use the Accel_Pedal_Pos signal. See hyundai/values.py for a specific car list";
BA_DEF_
    BA_
    CAT_DEF_
    CAT_
    FILTER
    BA_DEF_DEF_
    EV_DATA_
    ENVVAR_DATA_
    SGTYPE_
    SGTYPE_VAL_
    BA_DEF_SGTYPE_
    BA_SGTYPE_
    SIG_TYPE_REF_
    VAL_TABLE_
    SIG_GROUP_
    SIG_VALTYPE_
    SIGTYPE_VALTYPE_
    BO_TX_BU_
    BA_DEF_REL_
    BA_REL_
    BA_DEF_DEF_REL_
    BU_SG_REL_
    BU_EV_REL_
    BU_BO_REL_
    SG_MUL_VAL_

BS_:

BU_: XXX CAMERA FRONT_RADAR ADRV APRK

BO_ 53 ACCELERATOR: 32 XXX
 SG_ CHECKSUM : 0|16@1+ (1,0) [0|65535] "" XXX
 SG_ COUNTER : 16|8@1+ (1,0) [0|255] "" XXX
 SG_ GEAR : 192|3@1+ (1,0) [0|7] "" XXX
 SG_ ACCELERATOR_PEDAL : 40|8@1+ (1,0) [0|255] "" XXX

BO_ 64 GEAR_ALT: 32 XXX
 SG_ CHECKSUM : 0|16@1+ (1,0) [0|65535] "" XXX
 SG_ COUNTER : 16|8@1+ (1,0) [0|255] "" XXX
 SG_ GEAR : 32|3@1+ (1,0) [0|7] "" XXX

BO_ 69 GEAR: 24 XXX
 SG_ CHECKSUM : 0|16@1+ (1,0) [0|65535] "" XXX
 SG_ COUNTER : 16|8@1+ (1,0) [0|255] "" XXX
 SG_ GEAR : 44|3@1+ (1,0) [0|7] "" XXX

BO_ 80 LKAS: 16 XXX
 SG_ STEER_REQ : 52|1@1+ (1,0) [0|1] "" XXX
 SG_ TORQUE_REQUEST : 41|11@1+ (1,-1024) [0|4095] "" XXX
 SG_ LKA_ICON : 38|2@1+ (1,0) [0|255] "" XXX
 SG_ NEW_SIGNAL_1 : 27|2@1+ (1,0) [0|255] "" XXX
 SG_ LFA_BUTTON : 56|1@1+ (1,0) [0|255] "" XXX
 SG_ COUNTER : 16|8@1+ (1,0) [0|255] "" XXX
 SG_ CHECKSUM : 0|16@1+ (1,0) [0|65535] "" XXX
 SG_ STEER_MODE : 65|3@1+ (1,0) [0|1] "" XXX
 SG_ LKA_WARNING : 32|1@1+ (1,0) [0|1] "" XXX
 SG_ LKA_ASSIST : 62|1@1+ (1,0) [0|1] "" XXX
 SG_ LKA_MODE : 24|3@1+ (1,0) [0|7] "" XXX
 SG_ NEW_SIGNAL_2 : 70|2@0+ (1,0) [0|3] "" XXX
 SG_ HAS_LANE_SAFETY : 80|1@0+ (1,0) [0|1] "" XXX
 SG_ NEW_SIGNAL_3 : 111|8@0+ (1,0) [0|255] "" XXX
 SG_ FCA_SYSWARN : 40|1@0+ (1,0) [0|1] "" XXX

BO_ 81 ADRV_0x51: 32 ADRV
 SG_ COUNTER : 16|8@1+ (1,0) [0|255] "" XXX
 SG_ CHECKSUM : 0|16@1+ (1,0) [0|65535] "" XXX

BO_ 96 ESP_STATUS: 32 XXX
 SG_ CHECKSUM : 0|16@1+ (1,0) [0|65535] "" XXX
 SG_ COUNTER : 16|8@1+ (1,0) [0|255] "" XXX
 SG_ TRACTION_AND_STABILITY_CONTROL : 42|3@1+ (1,0) [0|63] "" XXX
 SG_ BRAKE_PRESSURE : 128|10@1+ (1,0) [0|65535] "" XXX
 SG_ BRAKE_PRESSED : 148|1@1+ (1,0) [0|3] "" XXX

BO_ 101 BRAKE: 32 XXX
 SG_ CHECKSUM : 0|16@1+ (1,0) [0|65535] "" XXX
 SG_ COUNTER : 16|8@1+ (1,0) [0|255] "" XXX
 SG_ BRAKE_POSITION : 40|16@1- (1,0) [0|65535] "" XXX
 SG_ BRAKE_PRESSED : 57|1@1+ (1,0) [0|3] "" XXX

BO_ 112 GEAR_ALT_2: 32 XXX
 SG_ CHECKSUM : 0|16@1+ (1,0) [0|65535] "" XXX
 SG_ COUNTER : 16|8@1+ (1,0) [0|255] "" XXX
 SG_ GEAR : 60|3@1+ (1,0) [0|7] "" XXX

BO_ 160 WHEEL_SPEEDS: 24 XXX
 SG_ CHECKSUM : 0|16@1+ (1,0) [0|65535] "" XXX
 SG_ COUNTER : 16|8@1+ (1,0) [0|255] "" XXX
 SG_ MOVING_FORWARD : 56|1@0+ (1,0) [0|1] "" XXX
 SG_ MOVING_BACKWARD : 57|1@0+ (1,0) [0|1] "" XXX
 SG_ MOVING_FORWARD2 : 58|1@0+ (1,0) [0|1] "" XXX
 SG_ MOVING_BACKWARD2 : 59|1@0+ (1,0) [0|1] "" XXX
 SG_ WHEEL_SPEED_1 : 64|16@1+ (0.03125,0) [0|65535] "kph" XXX
 SG_ WHEEL_SPEED_2 : 80|16@1+ (0.03125,0) [0|65535] "kph" XXX
 SG_ WHEEL_SPEED_3 : 96|16@1+ (0.03125,0) [0|65535] "kph" XXX
 SG_ WHEEL_SPEED_4 : 112|16@1+ (0.03125,0) [0|65535] "kph" XXX

BO_ 234 MDPS: 24 XXX
 SG_ CHECKSUM : 0|16@1+ (1,0) [0|65535] "" XXX
 SG_ COUNTER : 16|8@1+ (1,0) [0|255] "" XXX
 SG_ LKA_ACTIVE : 48|1@0+ (1,0) [0|16777215] "" XXX
 SG_ LKA_FAULT : 54|1@0+ (1,0) [0|1] "" XXX
 SG_ STEERING_OUT_TORQUE : 64|12@1+ (0.1,-204.8) [0|65535] "" XXX
 SG_ STEERING_COL_TORQUE : 80|13@1+ (1,-4095) [0|4095] "" XXX
 SG_ STEERING_ANGLE : 96|16@1- (-0.1,0) [0|255] "deg" XXX
 SG_ STEERING_ANGLE_2 : 128|16@1- (-0.1,0) [0|65535] "deg" XXX

BO_ 256 ACCELERATOR_BRAKE_ALT: 32 XXX
 SG_ CHECKSUM : 0|16@1+ (1,0) [0|65535] "" XXX
 SG_ COUNTER : 16|8@1+ (1,0) [0|255] "" XXX
 SG_ BRAKE_PRESSED : 32|1@1+ (1,0) [0|1] "" XXX
 SG_ ACCELERATOR_PEDAL_PRESSED : 176|1@1+ (1,0) [0|1] "" XXX

BO_ 261 ACCELERATOR_ALT: 32 XXX
 SG_ CHECKSUM : 0|16@1+ (1,0) [0|65535] "" XXX
 SG_ COUNTER : 16|8@1+ (1,0) [0|255] "" XXX
 SG_ ACCELERATOR_PEDAL : 103|10@1+ (0.25,0) [0|1022] "" XXX

BO_ 272 LKAS_ALT: 32 XXX
 SG_ STEER_REQ : 52|1@1+ (1,0) [0|1] "" XXX
 SG_ TORQUE_REQUEST : 41|11@1+ (1,-1024) [0|4095] "" XXX
 SG_ LKA_ICON : 38|2@1+ (1,0) [0|255] "" XXX
 SG_ NEW_SIGNAL_1 : 27|2@1+ (1,0) [0|255] "" XXX
 SG_ LFA_BUTTON : 56|1@1+ (1,0) [0|255] "" XXX
 SG_ COUNTER : 16|8@1+ (1,0) [0|255] "" XXX
 SG_ CHECKSUM : 0|16@1+ (1,0) [0|65535] "" XXX
 SG_ STEER_MODE : 65|3@1+ (1,0) [0|1] "" XXX
 SG_ LKA_WARNING : 32|1@1+ (1,0) [0|1] "" XXX
 SG_ LKA_ASSIST : 62|1@1+ (1,0) [0|1] "" XXX
 SG_ LKA_MODE : 24|3@1+ (1,0) [0|7] "" XXX
 SG_ NEW_SIGNAL_2 : 70|2@0+ (1,0) [0|3] "" XXX
 SG_ HAS_LANE_SAFETY : 80|1@0+ (1,0) [0|1] "" XXX
 SG_ NEW_SIGNAL_3 : 111|8@0+ (1,0) [0|255] "" XXX
 SG_ FCA_SYSWARN : 40|1@0+ (1,0) [0|1] "" XXX

BO_ 293 STEERING_SENSORS: 16 XXX
 SG_ CHECKSUM : 0|16@1+ (1,0) [0|65535] "" XXX
 SG_ COUNTER : 16|8@1+ (1,0) [0|255] "" XXX
 SG_ STEERING_RATE : 40|8@1+ (4,0) [0|1016] "deg/s" XXX
 SG_ STEERING_ANGLE : 24|16@1- (-0.1,0) [0|255] "deg" XXX

BO_ 298 LFA: 16 ADRV
 SG_ STEER_REQ : 52|1@1+ (1,0) [0|1] "" XXX
 SG_ TORQUE_REQUEST : 41|11@1+ (1,-1024) [0|4095] "" XXX
 SG_ LKA_ICON : 38|2@1+ (1,0) [0|255] "" XXX
 SG_ NEW_SIGNAL_1 : 27|2@1+ (1,0) [0|255] "" XXX
 SG_ LFA_BUTTON : 56|1@1+ (1,0) [0|255] "" XXX
 SG_ COUNTER : 16|8@1+ (1,0) [0|255] "" XXX
 SG_ CHECKSUM : 0|16@1+ (1,0) [0|65535] "" XXX
 SG_ STEER_MODE : 65|3@1+ (1,0) [0|1] "" XXX
 SG_ LKA_WARNING : 32|1@1+ (1,0) [0|1] "" XXX
 SG_ LKA_ASSIST : 62|1@1+ (1,0) [0|1] "" XXX
 SG_ LKA_MODE : 24|3@1+ (1,0) [0|7] "" XXX
 SG_ NEW_SIGNAL_2 : 70|2@0+ (1,0) [0|3] "" XXX
 SG_ HAS_LANE_SAFETY : 80|1@0+ (1,0) [0|1] "" XXX
 SG_ NEW_SIGNAL_3 : 111|8@0+ (1,0) [0|255] "" XXX

BO_ 304 GEAR_SHIFTER: 16 XXX
 SG_ CHECKSUM : 0|16@1+ (1,0) [0|65535] "" XXX
 SG_ COUNTER : 16|8@1+ (1,0) [0|255] "" XXX
 SG_ PARK_BUTTON : 32|2@1+ (1,0) [0|3] "" XXX
 SG_ GEAR : 64|3@1+ (1,0) [0|7] "" XXX
 SG_ KNOB_POSITION : 40|3@1+ (1,0) [0|3] "" XXX

BO_ 357 SPAS1: 24 APRK
 SG_ CHECKSUM : 0|16@1+ (1,0) [0|65535] "" XXX
 SG_ COUNTER : 16|8@1+ (1,0) [0|0] "" XXX
 SG_ NEW_SIGNAL_1 : 96|16@1- (0.1,0) [0|0] "" XXX
 SG_ NEW_SIGNAL_2 : 90|3@1+ (1,0) [0|0] "" XXX

BO_ 362 SPAS2: 32 APRK
 SG_ CHECKSUM : 0|16@1+ (1,0) [0|65535] "" XXX
 SG_ COUNTER : 16|8@1+ (1,0) [0|0] "" XXX
 SG_ BLINKER_CONTROL : 133|3@1+ (1,0) [0|0] "" XXX

BO_ 373 TCS: 24 XXX
 SG_ CHECKSUM : 0|16@1+ (1,0) [0|65535] "" XXX
 SG_ COUNTER : 16|8@1+ (1,0) [0|255] "" XXX
 SG_ NEW_SIGNAL_1 : 80|1@0+ (1,0) [0|1] "" XXX
 SG_ NEW_SIGNAL_2 : 74|1@0+ (1,0) [0|1] "" XXX
 SG_ NEW_SIGNAL_3 : 76|1@0+ (1,0) [0|1] "" XXX
 SG_ NEW_SIGNAL_4 : 24|7@1+ (1,0) [0|127] "" XXX
 SG_ aBasis : 32|11@1+ (0.01,-10.23) [0|7] "m/s^2" XXX
 SG_ NEW_SIGNAL_5 : 72|1@0+ (1,0) [0|1] "" XXX
 SG_ NEW_SIGNAL_6 : 128|4@1+ (1,0) [0|15] "" XXX
 SG_ NEW_SIGNAL_7 : 135|2@0+ (1,0) [0|3] "" XXX
 SG_ PROBABLY_EQUIP : 136|2@1+ (1,0) [0|3] "" XXX
 SG_ AEB_EQUIP_MAYBE : 96|1@0+ (1,0) [0|1] "" XXX
 SG_ EQUIP_MAYBE : 64|1@0+ (1,0) [0|1] "" XXX
 SG_ DriverBraking : 81|1@0+ (1,0) [0|1] "" XXX
 SG_ DriverBrakingLowSens : 84|1@1+ (1,0) [0|1] "" XXX
 SG_ ACC_REQ : 68|1@0+ (1,0) [0|1] "" XXX
 SG_ ACCEL_REF_ACC : 48|11@1- (1,0) [0|1023] "" XXX
 SG_ ACCEnable : 67|2@0+ (1,0) [0|3] "" XXX

BO_ 352 ADRV_0x160: 16 ADRV
 SG_ CHECKSUM : 0|16@1+ (1,0) [0|65535] "" XXX
 SG_ COUNTER : 16|8@1+ (1,0) [0|255] "" XXX
 SG_ SET_ME_FF : 64|8@1+ (1,0) [0|255] "" XXX
 SG_ SET_ME_FC : 72|8@1+ (1,0) [0|255] "" XXX
 SG_ SET_ME_2 : 56|8@1+ (1,0) [0|1] "" XXX
 SG_ AEB_SETTING : 24|2@1+ (1,0) [0|255] "" XXX
 SG_ SET_ME_9 : 80|8@1+ (1,0) [0|255] "" XXX

BO_ 384 CAM_0x180: 32 CAMERA
 SG_ CHECKSUM : 0|16@1+ (1,0) [0|65535] "" XXX
 SG_ COUNTER : 16|8@1+ (1,0) [0|255] "" XXX

BO_ 385 CAM_0x181: 32 CAMERA
 SG_ CHECKSUM : 0|16@1+ (1,0) [0|65535] "" XXX
 SG_ COUNTER : 16|8@1+ (1,0) [0|255] "" XXX

BO_ 386 CAM_0x182: 32 CAMERA
 SG_ CHECKSUM : 0|16@1+ (1,0) [0|65535] "" XXX
 SG_ COUNTER : 16|8@1+ (1,0) [0|255] "" XXX

BO_ 387 CAM_0x183: 32 CAMERA
 SG_ CHECKSUM : 0|16@1+ (1,0) [0|65535] "" XXX
 SG_ COUNTER : 16|8@1+ (1,0) [0|255] "" XXX

BO_ 388 CAM_0x184: 32 CAMERA
 SG_ CHECKSUM : 0|16@1+ (1,0) [0|65535] "" XXX
 SG_ COUNTER : 16|8@1+ (1,0) [0|255] "" XXX

BO_ 389 CAM_0x185: 8 CAMERA
 SG_ CHECKSUM : 0|16@1+ (1,0) [0|65535] "" XXX
 SG_ COUNTER : 16|8@1+ (1,0) [0|255] "" XXX

BO_ 416 SCC_CONTROL: 32 ADRV
 SG_ CHECKSUM : 0|16@1+ (1,0) [0|65535] "" XXX
 SG_ NEW_SIGNAL_1 : 64|2@1+ (1,0) [0|3] "" XXX
 SG_ NEW_SIGNAL_8 : 170|4@1+ (1,0) [0|15] "" XXX
 SG_ ZEROS : 215|48@0+ (1,0) [0|281474976710655] "" XXX
 SG_ ZEROS_3 : 191|7@0+ (1,0) [0|127] "" XXX
 SG_ ZEROS_4 : 183|4@0+ (1,0) [0|63] "" XXX
 SG_ ZEROS_6 : 119|16@0+ (1,0) [0|65535] "" XXX
 SG_ ZEROS_8 : 95|5@0+ (1,0) [0|31] "" XXX
 SG_ NEW_SIGNAL_3 : 109|2@0+ (1,0) [0|1] "" XXX
 SG_ SET_ME_TMP_64 : 55|8@0+ (1,0) [0|63] "" XXX
 SG_ SET_ME_2 : 105|3@1+ (1,0) [0|7] "" XXX
 SG_ NEW_SIGNAL_6 : 104|1@0+ (1,0) [0|1] "" XXX
 SG_ COUNTER : 16|8@1+ (1,0) [0|255] "" XXX
 SG_ ZEROS_9 : 71|5@1+ (1,0) [0|15] "" XXX
 SG_ ZEROS_10 : 111|2@0+ (1,0) [0|3] "" XXX
 SG_ SET_ME_3 : 45|2@0+ (1,0) [0|3] "" XXX
 SG_ ObjValid : 46|1@0+ (1,0) [0|3] "" XXX
 SG_ NEW_SIGNAL_2 : 168|2@1+ (1,0) [0|3] "" XXX
 SG_ OBJ_STATUS : 176|3@1+ (1,0) [0|7] "" XXX
 SG_ ACC_ObjDist : 24|11@1+ (0.1,0) [0|204.7] "m" XXX
 SG_ ZEROS_5 : 77|11@1+ (1,0) [0|2047] "" XXX
 SG_ DISTANCE_SETTING : 88|3@1+ (1,0) [0|3] "" XXX
 SG_ ZEROS_2 : 207|5@0+ (1,0) [0|63] "" XXX
 SG_ CRUISE_STANDSTILL : 76|1@1+ (1,0) [0|1] "" XXX
 SG_ aReqRaw : 140|11@1+ (0.01,-10.23) [-10.23|10.24] "m/s^2" XXX
 SG_ aReqValue : 128|11@1+ (0.01,-10.23) [-10.23|10.24] "m/s^2" XXX
 SG_ ZEROS_7 : 63|8@0+ (1,0) [0|255] "" XXX
 SG_ ACCMode : 68|3@1+ (1,0) [0|7] "" XXX
 SG_ ACC_ObjRelSpd : 35|9@1+ (0.1,-16.4) [-16.4|34.7] "m/s" XXX
 SG_ JerkLowerLimit : 166|7@0+ (0.1,0) [0|12.7] "m/s^3" XXX
 SG_ StopReq : 184|1@0+ (1,0) [0|1] "" XXX
 SG_ NEW_SIGNAL_15 : 192|11@1+ (0.1,0) [0|204.7] "m" XXX
 SG_ VSetDis : 103|8@0+ (1,0) [0|255] "km/h or mph" XXX
 SG_ MainMode_ACC : 66|1@1+ (1,0) [0|1] "" XXX
 SG_ JerkUpperLimit : 158|7@0+ (0.1,0) [0|0] "" XXX

BO_ 426 CRUISE_BUTTONS_ALT: 16 XXX
 SG_ CHECKSUM : 0|16@1+ (1,0) [0|65535] "" XXX
 SG_ COUNTER : 16|8@1+ (1,0) [0|255] "" XXX
 SG_ NEW_SIGNAL_1 : 24|4@1+ (1,0) [0|15] "" XXX
 SG_ SET_ME_1 : 28|2@1+ (1,0) [0|3] "" XXX
 SG_ DISTANCE_UNIT : 30|1@1+ (1,0) [0|1] "" XXX
 SG_ NEW_SIGNAL_2 : 31|3@1+ (1,0) [0|7] "" XXX
 SG_ ADAPTIVE_CRUISE_MAIN_BTN : 34|1@1+ (1,0) [0|1] "" XXX
 SG_ NEW_SIGNAL_3 : 35|1@1+ (1,0) [0|1] "" XXX
 SG_ LFA_BTN : 39|1@1+ (1,0) [0|1] "" XXX
 SG_ CRUISE_BUTTONS : 36|3@1+ (1,0) [0|4] "" XXX
 SG_ NEW_SIGNAL_4 : 40|1@1+ (1,0) [0|1] "" XXX
 SG_ NORMAL_CRUISE_MAIN_BTN : 41|1@1+ (1,0) [0|1] "" XXX
 SG_ NEW_SIGNAL_5 : 42|2@1+ (1,0) [0|3] "" XXX
 SG_ SET_ME_2 : 44|3@1+ (1,0) [0|7] "" XXX
 SG_ NEW_SIGNAL_6 : 47|1@1+ (1,0) [0|1] "" XXX
 SG_ BYTE6 : 48|8@1+ (1,0) [0|255] "" XXX
 SG_ BYTE7 : 56|8@1+ (1,0) [0|255] "" XXX
 SG_ BYTE8 : 64|8@1+ (1,0) [0|255] "" XXX
 SG_ BYTE9 : 72|8@1+ (1,0) [0|255] "" XXX
 SG_ BYTE10 : 80|8@1+ (1,0) [0|255] "" XXX
 SG_ BYTE11 : 88|8@1+ (1,0) [0|255] "" XXX
 SG_ BYTE12 : 96|8@1+ (1,0) [0|255] "" XXX
 SG_ BYTE13 : 104|8@1+ (1,0) [0|255] "" XXX
 SG_ BYTE14 : 112|8@1+ (1,0) [0|255] "" XXX
 SG_ BYTE15 : 120|8@1+ (1,0) [0|255] "" XXX

BO_ 438 CAM_0x1b6: 32 CAMERA
 SG_ CHECKSUM : 0|16@1+ (1,0) [0|65535] "" XXX
 SG_ COUNTER : 16|8@1+ (1,0) [0|255] "" XXX

BO_ 439 CAM_0x1b7: 32 CAMERA
 SG_ CHECKSUM : 0|16@1+ (1,0) [0|65535] "" XXX
 SG_ COUNTER : 16|8@1+ (1,0) [0|255] "" XXX

BO_ 440 CAM_0x1b8: 32 CAMERA
 SG_ CHECKSUM : 0|16@1+ (1,0) [0|65535] "" XXX
 SG_ COUNTER : 16|8@1+ (1,0) [0|255] "" XXX

BO_ 441 CAM_0x1b9: 32 CAMERA
 SG_ CHECKSUM : 0|16@1+ (1,0) [0|65535] "" XXX
 SG_ COUNTER : 16|8@1+ (1,0) [0|255] "" XXX

BO_ 463 CRUISE_BUTTONS: 8 XXX
 SG_ _CHECKSUM : 0|8@1+ (1,0) [0|65535] "" XXX
 SG_ LFA_BTN : 23|1@1+ (1,0) [0|1] "" XXX
 SG_ SET_ME_1 : 29|1@1+ (1,0) [0|1] "" XXX
 SG_ ADAPTIVE_CRUISE_MAIN_BTN : 19|1@1+ (1,0) [0|1] "" XXX
 SG_ NORMAL_CRUISE_MAIN_BTN : 21|1@1+ (1,0) [0|1] "" XXX
 SG_ COUNTER : 12|4@1+ (1,0) [0|255] "" XXX
 SG_ CRUISE_BUTTONS : 16|3@1+ (1,0) [0|3] "" XXX
 SG_ RIGHT_PADDLE : 25|1@1+ (1,0) [0|1] "" XXX
 SG_ LEFT_PADDLE : 27|1@1+ (1,0) [0|1] "" XXX

BO_ 474 ADRV_0x1da: 32 ADRV
 SG_ CHECKSUM : 0|16@1+ (1,0) [0|65535] "" XXX
 SG_ COUNTER : 16|8@1+ (1,0) [0|255] "" XXX
 SG_ SET_ME_22 : 31|8@0+ (1,0) [0|255] "" XXX
 SG_ SET_ME_41 : 47|8@0+ (1,0) [0|255] "" XXX

BO_ 480 LFAHDA_CLUSTER: 16 ADRV
 SG_ CHECKSUM : 0|16@1+ (1,0) [0|65535] "" XXX
 SG_ COUNTER : 16|8@1+ (1,0) [0|255] "" XXX
 SG_ HDA_ICON : 31|1@1+ (1,0) [0|1] "" XXX
 SG_ LFA_ICON : 47|2@1+ (1,0) [0|3] "" XXX
 SG_ NEW_SIGNAL_1 : 32|3@1+ (1,0) [0|7] "" XXX
 SG_ NEW_SIGNAL_2 : 30|1@0+ (1,0) [0|1] "" XXX
 SG_ NEW_SIGNAL_3 : 49|1@0+ (1,0) [0|1] "" XXX
 SG_ NEW_SIGNAL_4 : 24|1@0+ (1,0) [0|1] "" XXX

BO_ 490 ADRV_0x1ea: 32 ADRV
 SG_ CHECKSUM : 0|16@1+ (1,0) [0|65535] "" XXX
 SG_ COUNTER : 16|8@1+ (1,0) [0|255] "" XXX
 SG_ SET_ME_1C : 31|8@0+ (1,0) [0|255] "" XXX
 SG_ NEW_SIGNAL_1 : 32|2@1+ (1,0) [0|3] "" XXX
 SG_ NEW_SIGNAL_2 : 47|2@0+ (1,0) [0|3] "" XXX
 SG_ NEW_SIGNAL_3 : 55|8@0+ (1,0) [0|255] "" XXX
 SG_ NEW_SIGNAL_4 : 64|6@1+ (1,0) [0|31] "" XXX
 SG_ NEW_SIGNAL_5 : 72|2@1+ (1,0) [0|3] "" XXX
 SG_ NEW_SIGNAL_6 : 75|5@1+ (1,0) [0|31] "" XXX
 SG_ NEW_SIGNAL_7 : 80|5@1+ (1,0) [0|31] "" XXX
 SG_ NEW_SIGNAL_8 : 88|7@1+ (1,0) [0|127] "" XXX
 SG_ NEW_SIGNAL_9 : 96|1@0+ (1,0) [0|1] "" XXX
 SG_ NEW_SIGNAL_10 : 143|5@0+ (1,0) [0|31] "" XXX
 SG_ NEW_SIGNAL_11 : 144|3@1+ (1,0) [0|7] "" XXX
 SG_ NEW_SIGNAL_12 : 152|6@1+ (1,0) [0|63] "" XXX
 SG_ NEW_SIGNAL_13 : 160|1@0+ (1,0) [0|1] "" XXX
 SG_ NEW_SIGNAL_14 : 163|5@1+ (1,0) [0|31] "" XXX
 SG_ NEW_SIGNAL_15 : 175|4@0+ (1,0) [0|63] "" XXX
 SG_ NEW_SIGNAL_16 : 168|3@1+ (1,0) [0|7] "" XXX
 SG_ NEW_SIGNAL_17 : 176|2@1+ (1,0) [0|3] "" XXX
 SG_ NEW_SIGNAL_18 : 184|1@0+ (1,0) [0|1] "" XXX
 SG_ NEW_SIGNAL_19 : 208|3@1+ (1,0) [0|7] "" XXX
 SG_ NEW_SIGNAL_20 : 212|1@0+ (1,0) [0|1] "" XXX
 SG_ SET_ME_FF : 120|8@1+ (1,0) [0|255] "" XXX
 SG_ SET_ME_TMP_F : 232|5@1+ (1,0) [0|31] "" XXX
 SG_ SET_ME_TMP_F_2 : 240|5@1+ (1,0) [0|31] "" XXX

BO_ 507 CAM_0x1fb: 32 CAMERA
 SG_ CHECKSUM : 0|16@1+ (1,0) [0|65535] "" XXX
 SG_ COUNTER : 16|8@1+ (1,0) [0|255] "" XXX

BO_ 512 ADRV_0x200: 8 ADRV
 SG_ CHECKSUM : 0|16@1+ (1,0) [0|65535] "" XXX
 SG_ COUNTER : 16|8@1+ (1,0) [0|255] "" XXX
 SG_ SET_ME_E1 : 24|8@1+ (1,0) [0|255] "" XXX
 SG_ SET_ME_3A : 32|8@1+ (1,0) [0|255] "" XXX

BO_ 513 RADAR_0x201: 32 FRONT_RADAR
 SG_ CHECKSUM : 0|16@1+ (1,0) [0|65535] "" XXX
 SG_ COUNTER : 16|8@1+ (1,0) [0|255] "" XXX

BO_ 528 RADAR_0x210: 32 FRONT_RADAR
 SG_ CHECKSUM : 0|16@1+ (1,0) [0|65535] "" XXX
 SG_ COUNTER : 16|8@1+ (1,0) [0|255] "" XXX

BO_ 529 RADAR_0x211: 32 FRONT_RADAR
 SG_ CHECKSUM : 0|16@1+ (1,0) [0|65535] "" XXX
 SG_ COUNTER : 16|8@1+ (1,0) [0|255] "" XXX

BO_ 530 RADAR_0x212: 32 FRONT_RADAR
 SG_ CHECKSUM : 0|16@1+ (1,0) [0|65535] "" XXX
 SG_ COUNTER : 16|8@1+ (1,0) [0|255] "" XXX

BO_ 531 RADAR_0x213: 32 FRONT_RADAR
 SG_ CHECKSUM : 0|16@1+ (1,0) [0|65535] "" XXX
 SG_ COUNTER : 16|8@1+ (1,0) [0|255] "" XXX

BO_ 532 RADAR_0x214: 32 FRONT_RADAR
 SG_ CHECKSUM : 0|16@1+ (1,0) [0|65535] "" XXX
 SG_ COUNTER : 16|8@1+ (1,0) [0|255] "" XXX

BO_ 533 RADAR_0x215: 32 FRONT_RADAR
 SG_ CHECKSUM : 0|16@1+ (1,0) [0|65535] "" XXX
 SG_ COUNTER : 16|8@1+ (1,0) [0|255] "" XXX

BO_ 534 RADAR_0x216: 32 FRONT_RADAR
 SG_ CHECKSUM : 0|16@1+ (1,0) [0|65535] "" XXX
 SG_ COUNTER : 16|8@1+ (1,0) [0|255] "" XXX

BO_ 535 RADAR_0x217: 32 FRONT_RADAR
 SG_ CHECKSUM : 0|16@1+ (1,0) [0|65535] "" XXX
 SG_ COUNTER : 16|8@1+ (1,0) [0|255] "" XXX

BO_ 536 RADAR_0x218: 32 FRONT_RADAR
 SG_ CHECKSUM : 0|16@1+ (1,0) [0|65535] "" XXX
 SG_ COUNTER : 16|8@1+ (1,0) [0|255] "" XXX

BO_ 537 RADAR_0x219: 32 FRONT_RADAR
 SG_ CHECKSUM : 0|16@1+ (1,0) [0|65535] "" XXX
 SG_ COUNTER : 16|8@1+ (1,0) [0|255] "" XXX

BO_ 538 RADAR_0x21a: 32 FRONT_RADAR
 SG_ CHECKSUM : 0|16@1+ (1,0) [0|65535] "" XXX
 SG_ COUNTER : 16|8@1+ (1,0) [0|255] "" XXX

BO_ 539 RADAR_0x21b: 32 FRONT_RADAR
 SG_ CHECKSUM : 0|16@1+ (1,0) [0|65535] "" XXX
 SG_ COUNTER : 16|8@1+ (1,0) [0|255] "" XXX

BO_ 540 RADAR_0x21c: 32 FRONT_RADAR
 SG_ CHECKSUM : 0|16@1+ (1,0) [0|65535] "" XXX
 SG_ COUNTER : 16|8@1+ (1,0) [0|255] "" XXX

BO_ 541 RADAR_0x21d: 32 FRONT_RADAR
 SG_ CHECKSUM : 0|16@1+ (1,0) [0|65535] "" XXX
 SG_ COUNTER : 16|8@1+ (1,0) [0|255] "" XXX

BO_ 542 RADAR_0x21e: 32 FRONT_RADAR
 SG_ CHECKSUM : 0|16@1+ (1,0) [0|65535] "" XXX
 SG_ COUNTER : 16|8@1+ (1,0) [0|255] "" XXX

BO_ 543 RADAR_0x21f: 32 FRONT_RADAR
 SG_ CHECKSUM : 0|16@1+ (1,0) [0|65535] "" XXX
 SG_ COUNTER : 16|8@1+ (1,0) [0|255] "" XXX

BO_ 576 RADAR_0x240: 16 FRONT_RADAR
 SG_ CHECKSUM : 0|16@1+ (1,0) [0|65535] "" XXX
 SG_ COUNTER : 16|8@1+ (1,0) [0|255] "" XXX

BO_ 593 RADAR_0x251: 16 FRONT_RADAR
 SG_ CHECKSUM : 0|16@1+ (1,0) [0|65535] "" XXX
 SG_ COUNTER : 16|8@1+ (1,0) [0|255] "" XXX

BO_ 674 CAM_0x2a2: 32 CAMERA
 SG_ CHECKSUM : 0|16@1+ (1,0) [0|65535] "" XXX
 SG_ COUNTER : 16|8@1+ (1,0) [0|255] "" XXX

BO_ 675 CAM_0x2a3: 32 CAMERA
 SG_ CHECKSUM : 0|16@1+ (1,0) [0|65535] "" XXX
 SG_ COUNTER : 16|8@1+ (1,0) [0|255] "" XXX

BO_ 676 CAM_0x2a4: 24 XXX
 SG_ CHECKSUM : 0|16@1+ (1,0) [0|65535] "" XXX
 SG_ COUNTER : 16|8@1+ (1,0) [0|255] "" XXX
 SG_ BYTE3 : 24|8@1+ (1,0) [0|255] "" XXX
 SG_ BYTE4 : 32|8@1+ (1,0) [0|255] "" XXX
 SG_ BYTE5 : 40|8@1+ (1,0) [0|255] "" XXX
 SG_ BYTE6 : 48|8@1+ (1,0) [0|255] "" XXX
 SG_ LEFT_LANE_LINE : 56|2@1+ (1,0) [0|3] "" XXX
 SG_ SET_ME_0 : 58|2@1+ (1,0) [0|3] "" XXX
 SG_ RIGHT_LANE_LINE : 60|2@1+ (1,0) [0|3] "" XXX
 SG_ SET_ME_0_2 : 62|2@1+ (1,0) [0|3] "" XXX
 SG_ BYTE8 : 64|8@1+ (1,0) [0|255] "" XXX
 SG_ BYTE9 : 72|8@1+ (1,0) [0|255] "" XXX
 SG_ BYTE10 : 80|8@1+ (1,0) [0|255] "" XXX
 SG_ BYTE11 : 88|8@1+ (1,0) [0|255] "" XXX
 SG_ BYTE12 : 96|8@1+ (1,0) [0|255] "" XXX
 SG_ BYTE13 : 104|8@1+ (1,0) [0|255] "" XXX
 SG_ BYTE14 : 112|8@1+ (1,0) [0|255] "" XXX
 SG_ BYTE15 : 120|8@1+ (1,0) [0|255] "" XXX
 SG_ BYTE16 : 128|8@1+ (1,0) [0|255] "" XXX
 SG_ BYTE17 : 136|8@1+ (1,0) [0|255] "" XXX
 SG_ BYTE18 : 144|8@1+ (1,0) [0|255] "" XXX
 SG_ BYTE19 : 152|8@1+ (1,0) [0|255] "" XXX
 SG_ BYTE20 : 160|8@1+ (1,0) [0|255] "" XXX
 SG_ BYTE21 : 168|8@1+ (1,0) [0|255] "" XXX
 SG_ BYTE22 : 176|8@1+ (1,0) [0|255] "" XXX
 SG_ BYTE23 : 184|8@1+ (1,0) [0|255] "" XXX

BO_ 699 CAM_0x2bb: 32 CAMERA
 SG_ CHECKSUM : 0|16@1+ (1,0) [0|65535] "" XXX
 SG_ COUNTER : 16|8@1+ (1,0) [0|255] "" XXX

BO_ 700 CAM_0x2bc: 32 CAMERA
 SG_ CHECKSUM : 0|16@1+ (1,0) [0|65535] "" XXX
 SG_ COUNTER : 16|8@1+ (1,0) [0|255] "" XXX

BO_ 701 CAM_0x2bd: 32 CAMERA
 SG_ CHECKSUM : 0|16@1+ (1,0) [0|65535] "" XXX
 SG_ COUNTER : 16|8@1+ (1,0) [0|255] "" XXX

BO_ 702 CAM_0x2be: 32 CAMERA
 SG_ CHECKSUM : 0|16@1+ (1,0) [0|65535] "" XXX
 SG_ COUNTER : 16|8@1+ (1,0) [0|255] "" XXX

BO_ 736 MANUAL_SPEED_LIMIT_ASSIST: 32 XXX
 SG_ CHECKSUM : 0|16@1+ (1,0) [0|65535] "" XXX
 SG_ COUNTER : 16|8@1+ (1,0) [0|255] "" XXX
 SG_ MSLA_STATUS : 26|2@1+ (1,0) [0|3] "" XXX
 SG_ MSLA_ENABLED : 38|1@1+ (1,0) [0|1] "" XXX
 SG_ MAX_SPEED : 55|8@0+ (1,0) [0|255] "" XXX
 SG_ MAX_SPEED_COPY : 144|8@1+ (1,0) [0|255] "" XXX

BO_ 837 ADRV_0x345: 8 ADRV
 SG_ CHECKSUM : 0|16@1+ (1,0) [0|65535] "" XXX
 SG_ COUNTER : 16|8@1+ (1,0) [0|255] "" XXX
 SG_ SET_ME_15 : 24|8@1+ (1,0) [0|255] "" XXX

BO_ 866 CAM_0x362: 32 CAMERA
 SG_ CHECKSUM : 0|16@1+ (1,0) [0|65535] "" XXX
 SG_ COUNTER : 16|8@1+ (1,0) [0|255] "" XXX
 SG_ BYTE3 : 24|8@1+ (1,0) [0|255] "" XXX
 SG_ BYTE4 : 32|8@1+ (1,0) [0|255] "" XXX
 SG_ BYTE5 : 40|8@1+ (1,0) [0|255] "" XXX
 SG_ BYTE6 : 48|8@1+ (1,0) [0|255] "" XXX
 SG_ LEFT_LANE_LINE : 56|2@1+ (1,0) [0|3] "" XXX
 SG_ SET_ME_0 : 58|2@1+ (1,0) [0|3] "" XXX
 SG_ RIGHT_LANE_LINE : 60|2@1+ (1,0) [0|3] "" XXX
 SG_ SET_ME_0_2 : 62|2@1+ (1,0) [0|3] "" XXX
 SG_ BYTE8 : 64|8@1+ (1,0) [0|255] "" XXX
 SG_ BYTE9 : 72|8@1+ (1,0) [0|255] "" XXX
 SG_ BYTE10 : 80|8@1+ (1,0) [0|255] "" XXX
 SG_ BYTE11 : 88|8@1+ (1,0) [0|255] "" XXX
 SG_ BYTE12 : 96|8@1+ (1,0) [0|255] "" XXX
 SG_ BYTE13 : 104|8@1+ (1,0) [0|255] "" XXX
 SG_ BYTE14 : 112|8@1+ (1,0) [0|255] "" XXX
 SG_ BYTE15 : 120|8@1+ (1,0) [0|255] "" XXX
 SG_ BYTE16 : 128|8@1+ (1,0) [0|255] "" XXX
 SG_ BYTE17 : 136|8@1+ (1,0) [0|255] "" XXX
 SG_ BYTE18 : 144|8@1+ (1,0) [0|255] "" XXX
 SG_ BYTE19 : 152|8@1+ (1,0) [0|255] "" XXX
 SG_ BYTE20 : 160|8@1+ (1,0) [0|255] "" XXX
 SG_ BYTE21 : 168|8@1+ (1,0) [0|255] "" XXX
 SG_ BYTE22 : 176|8@1+ (1,0) [0|255] "" XXX
 SG_ BYTE23 : 184|8@1+ (1,0) [0|255] "" XXX
 SG_ BYTE24 : 192|8@1+ (1,0) [0|255] "" XXX
 SG_ BYTE25 : 200|8@1+ (1,0) [0|255] "" XXX
 SG_ BYTE26 : 208|8@1+ (1,0) [0|255] "" XXX
 SG_ BYTE27 : 216|8@1+ (1,0) [0|255] "" XXX
 SG_ BYTE28 : 224|8@1+ (1,0) [0|255] "" XXX
 SG_ BYTE29 : 232|8@1+ (1,0) [0|255] "" XXX
 SG_ BYTE30 : 240|8@1+ (1,0) [0|255] "" XXX
 SG_ BYTE31 : 248|8@1+ (1,0) [0|255] "" XXX

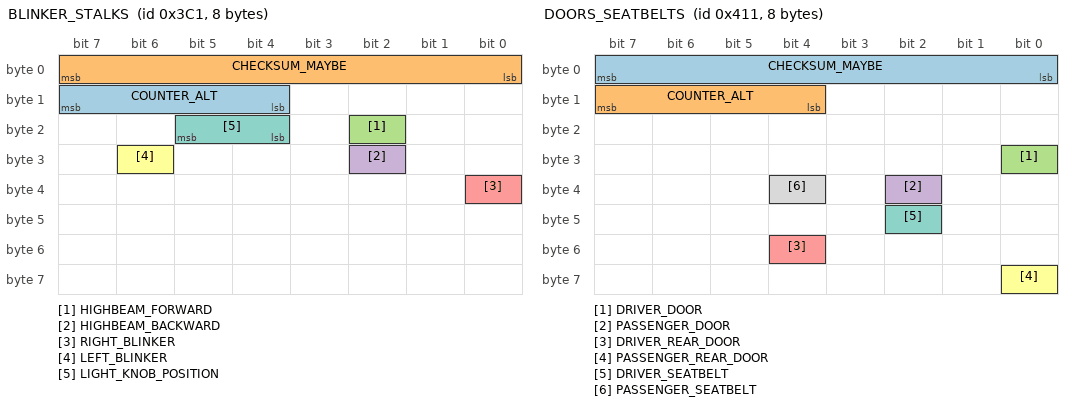
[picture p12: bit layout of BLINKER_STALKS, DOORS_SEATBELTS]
BO_ 961 BLINKER_STALKS: 8 XXX
 SG_ COUNTER_ALT : 15|4@0+ (1,0) [0|15] "" XXX
 SG_ CHECKSUM_MAYBE : 7|8@0+ (1,0) [0|255] "" XXX
 SG_ HIGHBEAM_FORWARD : 18|1@0+ (1,0) [0|1] "" XXX
 SG_ HIGHBEAM_BACKWARD : 26|1@0+ (1,0) [0|1] "" XXX
 SG_ RIGHT_BLINKER : 32|1@0+ (1,0) [0|1] "" XXX
 SG_ LEFT_BLINKER : 30|1@0+ (1,0) [0|1] "" XXX
 SG_ LIGHT_KNOB_POSITION : 21|2@0+ (1,0) [0|3] "" XXX

BO_ 1041 DOORS_SEATBELTS: 8 XXX
 SG_ CHECKSUM_MAYBE : 7|8@0+ (1,0) [0|65535] "" XXX
 SG_ COUNTER_ALT : 15|4@0+ (1,0) [0|15] "" XXX
 SG_ DRIVER_DOOR : 24|1@1+ (1,0) [0|1] "" XXX
 SG_ PASSENGER_DOOR : 34|1@0+ (1,0) [0|1] "" XXX
 SG_ DRIVER_REAR_DOOR : 52|1@0+ (1,0) [0|1] "" XXX
 SG_ PASSENGER_REAR_DOOR : 56|1@0+ (1,0) [0|1] "" XXX
 SG_ DRIVER_SEATBELT : 42|1@0+ (1,0) [0|1] "" XXX
 SG_ PASSENGER_SEATBELT : 36|1@0+ (1,0) [0|1] "" XXX

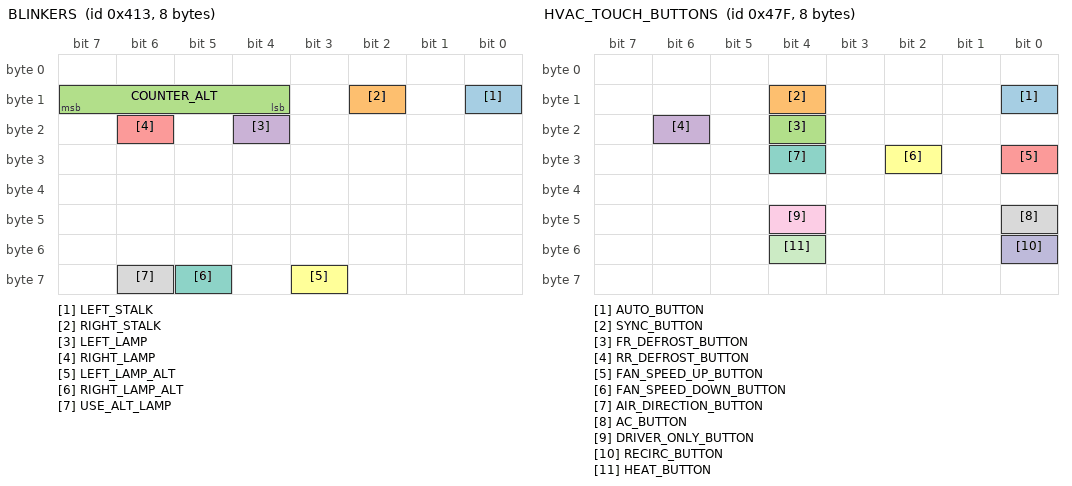
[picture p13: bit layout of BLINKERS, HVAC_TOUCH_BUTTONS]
BO_ 1043 BLINKERS: 8 XXX
 SG_ LEFT_STALK : 8|1@0+ (1,0) [0|1] "" XXX
 SG_ RIGHT_STALK : 10|1@0+ (1,0) [0|1] "" XXX
 SG_ COUNTER_ALT : 15|4@0+ (1,0) [0|15] "" XXX
 SG_ LEFT_LAMP : 20|1@0+ (1,0) [0|1] "" XXX
 SG_ RIGHT_LAMP : 22|1@0+ (1,0) [0|1] "" XXX
 SG_ LEFT_LAMP_ALT : 59|1@0+ (1,0) [0|1] "" XXX
 SG_ RIGHT_LAMP_ALT : 61|1@0+ (1,0) [0|1] "" XXX
 SG_ USE_ALT_LAMP : 62|1@0+ (1,0) [0|1] "" XXX

BO_ 1240 CLUSTER_INFO: 8 XXX
 SG_ DISTANCE_UNIT : 0|1@1+ (1,0) [0|1] "" XXX

BO_ 442 BLINDSPOTS_REAR_CORNERS: 24 XXX
 SG_ COUNTER : 16|8@1+ (1,0) [0|255] "" XXX
 SG_ CHECKSUM : 0|16@1+ (1,0) [0|65535] "" XXX
 SG_ NEW_SIGNAL_2 : 96|1@0+ (1,0) [0|1] "" XXX
 SG_ COLLISION_AVOIDANCE_ACTIVE : 68|1@0+ (1,0) [0|1] "" XXX
 SG_ LEFT_MB : 30|1@0+ (1,0) [0|3] "" XXX
 SG_ LEFT_BLOCKED : 24|1@0+ (1,0) [0|1] "" XXX
 SG_ MORE_LEFT_PROB : 32|1@1+ (1,0) [0|3] "" XXX
 SG_ FL_INDICATOR : 46|6@0+ (1,0) [0|1] "" XXX
 SG_ FR_INDICATOR : 54|6@0+ (1,0) [0|63] "" XXX
 SG_ RIGHT_BLOCKED : 64|1@0+ (1,0) [0|1] "" XXX
 SG_ FL_INDICATOR_ALT : 138|1@0+ (1,0) [0|1] "" XXX
 SG_ FR_INDICATOR_ALT : 141|1@0+ (1,0) [0|1] "" XXX

BO_ 874 BLINDSPOTS_FRONT_CORNER_2: 16 XXX
 SG_ COUNTER : 16|8@1+ (1,0) [0|255] "" XXX
 SG_ CHECKSUM : 0|16@1+ (1,0) [0|65535] "" XXX

BO_ 485 BLINDSPOTS_FRONT_CORNER_1: 16 XXX
 SG_ COUNTER : 16|8@1+ (1,0) [0|255] "" XXX
 SG_ CHECKSUM : 0|16@1+ (1,0) [0|65535] "" XXX
 SG_ NEW_SIGNAL_1 : 108|2@0+ (1,0) [0|3] "" XXX
 SG_ NEW_SIGNAL_2 : 96|1@0+ (1,0) [0|1] "" XXX
 SG_ NEW_SIGNAL_3 : 88|1@0+ (1,0) [0|1] "" XXX
 SG_ NEW_SIGNAL_4 : 80|1@0+ (1,0) [0|1] "" XXX
 SG_ NEW_SIGNAL_5 : 31|2@0+ (1,0) [0|3] "" XXX
 SG_ REVERSING : 24|1@0+ (1,0) [0|1] "" XXX
 SG_ NEW_SIGNAL_7 : 32|2@1+ (1,0) [0|3] "" XXX
 SG_ NEW_SIGNAL_8 : 47|8@0+ (1,0) [0|255] "" XXX
 SG_ NEW_SIGNAL_9 : 55|8@0+ (1,0) [0|255] "" XXX

BO_ 506 CLUSTER_SPEED_LIMIT: 32 XXX
 SG_ SPEED_LIMIT_3 : 119|8@0+ (1,0) [0|255] "" XXX
 SG_ SPEED_LIMIT_2 : 47|7@0+ (1,0) [0|255] "" XXX
 SG_ SPEED_LIMIT_1 : 39|7@0+ (1,0) [0|255] "" XXX
 SG_ SPEED_CHANGE_BLINKING : 129|1@1+ (1,0) [0|3] "" XXX
 SG_ CHIME_2 : 122|2@1+ (1,0) [0|7] "" XXX
 SG_ CHIME_1 : 133|1@0+ (1,0) [0|1] "" XXX
 SG_ ARROW_DOWN : 120|1@0+ (1,0) [0|1] "" XXX
 SG_ ARROW_UP : 121|1@0+ (1,0) [0|1] "" XXX
 SG_ SECONDARY_LIMIT_1 : 79|8@0+ (1,0) [0|127] "" XXX
 SG_ SECONDARY_LIMIT_2 : 103|8@0+ (1,0) [0|127] "" XXX
 SG_ SCHOOL_ZONE : 155|1@0+ (1,0) [0|1] "" XXX

BO_ 1144 DRIVE_MODE: 8 XXX
 SG_ DRIVE_MODE : 0|16@1+ (1,-61611) [0|61611] "" XXX
 SG_ DRIVE_MODE2 : 28|3@1+ (1,0) [1|3] "" XXX

BO_ 1151 HVAC_TOUCH_BUTTONS: 8 XXX
 SG_ AUTO_BUTTON : 8|1@0+ (1,0) [0|1] "" XXX
 SG_ SYNC_BUTTON : 12|1@0+ (1,0) [0|1] "" XXX
 SG_ FR_DEFROST_BUTTON : 20|1@0+ (1,0) [0|1] "" XXX
 SG_ RR_DEFROST_BUTTON : 22|1@0+ (1,0) [0|1] "" XXX
 SG_ FAN_SPEED_UP_BUTTON : 24|1@0+ (1,0) [0|1] "" XXX
 SG_ FAN_SPEED_DOWN_BUTTON : 26|1@0+ (1,0) [0|1] "" XXX
 SG_ AIR_DIRECTION_BUTTON : 28|1@0+ (1,0) [0|1] "" XXX
 SG_ AC_BUTTON : 40|1@0+ (1,0) [0|1] "" XXX
 SG_ DRIVER_ONLY_BUTTON : 44|1@0+ (1,0) [0|1] "" XXX
 SG_ RECIRC_BUTTON : 48|1@0+ (1,0) [0|1] "" XXX
 SG_ HEAT_BUTTON : 52|1@0+ (1,0) [0|1] "" XXX

BO_ 1259 LOCAL_TIME2: 8 XXX
 SG_ HOURS : 15|5@0+ (1,0) [0|31] "" XXX
 SG_ MINUTES : 21|6@0+ (1,0) [0|63] "" XXX
 SG_ SECONDS : 24|6@1+ (1,0) [0|63] "" XXX
 SG_ NEW_SIGNAL_3 : 39|1@0+ (1,0) [0|1] "" XXX

BO_ 1264 LOCAL_TIME: 8 XXX
 SG_ HOURS : 12|5@0+ (1,0) [0|31] "" XXX
 SG_ MINUTES : 21|6@0+ (1,0) [0|63] "" XXX
 SG_ SECONDS : 31|8@0+ (1,0) [0|59] "" XXX

CM_ 272 "Alternative LKAS message, used on cars such as 2023 Ioniq 6, 2nd gen Kona. Matches LKAS except size is 32 bytes";
BA_DEF_
 BA_
 CAT_DEF_
 CAT_
 FILTER
 BA_DEF_DEF_
 EV_DATA_
 ENVVAR_DATA_
 SGTYPE_
 SGTYPE_VAL_
 BA_DEF_SGTYPE_
 BA_SGTYPE_
 SIG_TYPE_REF_
 VAL_TABLE_
 SIG_GROUP_
 SIG_VALTYPE_
 SIGTYPE_VALTYPE_
 BO_TX_BU_
 BA_DEF_REL_
 BA_REL_
 BA_DEF_DEF_REL_
 BU_SG_REL_
 BU_EV_REL_
 BU_BO_REL_
 SG_MUL_VAL_

BS_:

BU_: IAP ODS _4WD BCM HUD DATC MDPS AAF_Tester AEMC SMK _4WD EPB CUBIS MTS TMU EVP CGW TPMS LPI DI_BOX SPAS EMS LCA TCU IBOX FATC AFLS FPCM SCC AHLS AVM ABS SNV OPI PGS SAS AAF Dummy LDWS_LKAS LVR ESC PSB CLU ECS ACU REA

BO_ 387 REA11: 8 REA
 SG_ CF_EndBst_PwmDuH : 0|1@1+ (1.0,0.0) [0.0|1.0] ""  EMS
 SG_ CF_EndBst_PwmDuL : 1|1@1+ (1.0,0.0) [0.0|1.0] ""  EMS
 SG_ CF_EndBst_PwmFqOutRng : 2|1@1+ (1.0,0.0) [0.0|1.0] ""  EMS
 SG_ CF_EndBst_HbriOverCur : 3|1@1+ (1.0,0.0) [0.0|1.0] ""  EMS
 SG_ CF_EndBst_HbriOverTemp : 4|1@1+ (1.0,0.0) [0.0|1.0] ""  EMS
 SG_ CF_EndBst_PosSnsKOR : 6|1@1+ (1.0,0.0) [0.0|1.0] ""  EMS
 SG_ CF_EndBst_PosSnsOSOR : 7|1@1+ (1.0,0.0) [0.0|1.0] ""  EMS
 SG_ CF_EndBst_EepFlt : 8|1@1+ (1.0,0.0) [0.0|1.0] ""  EMS
 SG_ CF_EndBst_RomFlt : 9|1@1+ (1.0,0.0) [0.0|1.0] ""  EMS
 SG_ CF_EndBst_RamFlt : 10|1@1+ (1.0,0.0) [0.0|1.0] ""  EMS
 SG_ CF_EndBst_CanFlt : 11|1@1+ (1.0,0.0) [0.0|1.0] ""  EMS
 SG_ CF_EndBst_AgH : 12|1@1+ (1.0,0.0) [0.0|1.0] ""  EMS
 SG_ CF_EndBst_AgL : 13|1@1+ (1.0,0.0) [0.0|1.0] ""  EMS
 SG_ CF_EndBst_ORVol : 14|1@1+ (1.0,0.0) [0.0|1.0] ""  EMS
 SG_ CR_EndBst_ActPos : 16|16@1+ (0.117,0.0) [1.989|118.053] ""  EMS
 SG_ CR_EndBst_DemPos : 32|16@1+ (0.117,0.0) [0.0|119.691] ""  EMS
 SG_ CR_EndBst_HbriPwr : 48|16@1+ (0.045,0.0) [0.0|99.99] "%"  EMS

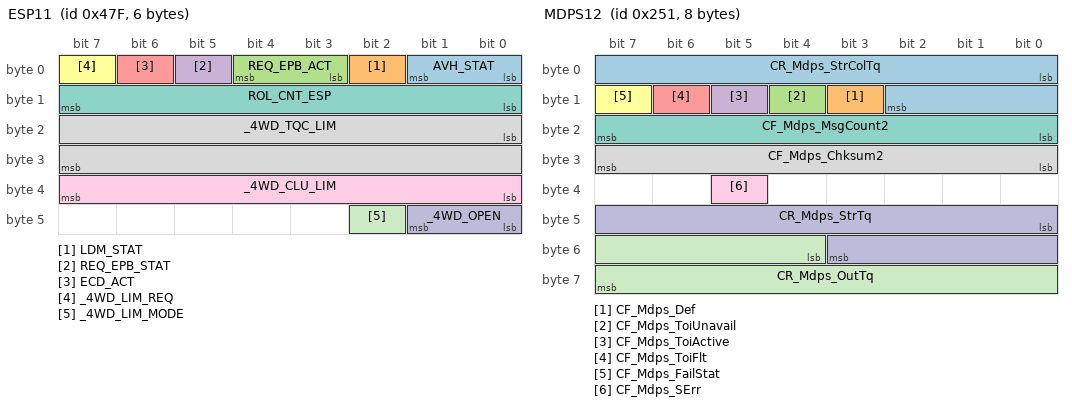
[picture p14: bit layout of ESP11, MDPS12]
BO_ 1151 ESP11: 6 ESC
 SG_ AVH_STAT : 0|2@1+ (1.0,0.0) [0.0|3.0] ""  EMS,EPB,TCU
 SG_ LDM_STAT : 2|1@1+ (1.0,0.0) [0.0|1.0] ""  EPB,TCU
 SG_ REQ_EPB_ACT : 3|2@1+ (1.0,0.0) [0.0|3.0] ""  EPB,TCU
 SG_ REQ_EPB_STAT : 5|1@1+ (1.0,0.0) [0.0|1.0] ""  EPB
 SG_ ECD_ACT : 6|1@1+ (1.0,0.0) [0.0|1.0] ""  EPB
 SG_ _4WD_LIM_REQ : 7|1@1+ (1.0,0.0) [0.0|1.0] ""  _4WD,EMS
 SG_ ROL_CNT_ESP : 8|8@1+ (1.0,0.0) [0.0|255.0] ""  EPB,TCU
 SG_ _4WD_TQC_LIM : 16|16@1+ (1.0,0.0) [0.0|65535.0] "Nm"  _4WD,EMS
 SG_ _4WD_CLU_LIM : 32|8@1+ (0.390625,0.0) [0.0|99.609375] "%"  _4WD,EMS
 SG_ _4WD_OPEN : 40|2@1+ (1.0,0.0) [0.0|3.0] ""  _4WD,EMS
 SG_ _4WD_LIM_MODE : 42|1@1+ (1.0,0.0) [0.0|1.0] ""  _4WD

BO_ 593 MDPS12: 8 MDPS
 SG_ CR_Mdps_StrColTq : 0|11@1+ (1.0,-1024.0) [-1024.0|1024.0] ""  LDWS_LKAS
 SG_ CF_Mdps_Def : 11|1@1+ (1.0,0.0) [0.0|1.0] ""  ESC
 SG_ CF_Mdps_ToiUnavail : 12|1@1+ (1.0,0.0) [0.0|1.0] ""  LDWS_LKAS
 SG_ CF_Mdps_ToiActive : 13|1@1+ (1.0,0.0) [0.0|1.0] ""  LDWS_LKAS
 SG_ CF_Mdps_ToiFlt : 14|1@1+ (1.0,0.0) [0.0|1.0] ""  LDWS_LKAS
 SG_ CF_Mdps_FailStat : 15|1@1+ (1.0,0.0) [0.0|1.0] ""  LDWS_LKAS
 SG_ CF_Mdps_MsgCount2 : 16|8@1+ (1.0,0.0) [0.0|255.0] ""  ESC,LDWS_LKAS
 SG_ CF_Mdps_Chksum2 : 24|8@1+ (1.0,0.0) [0.0|255.0] ""  ESC,LDWS_LKAS
 SG_ CF_Mdps_SErr : 37|1@1+ (1.0,0.0) [0.0|1.0] ""  ESC
 SG_ CR_Mdps_StrTq : 40|12@1+ (0.01,-20.48) [-20.48|20.47] "Nm"  ESC
 SG_ CR_Mdps_OutTq : 52|12@1+ (0.1,-204.8) [-204.8|204.7] ""  ESC,LDWS_LKAS

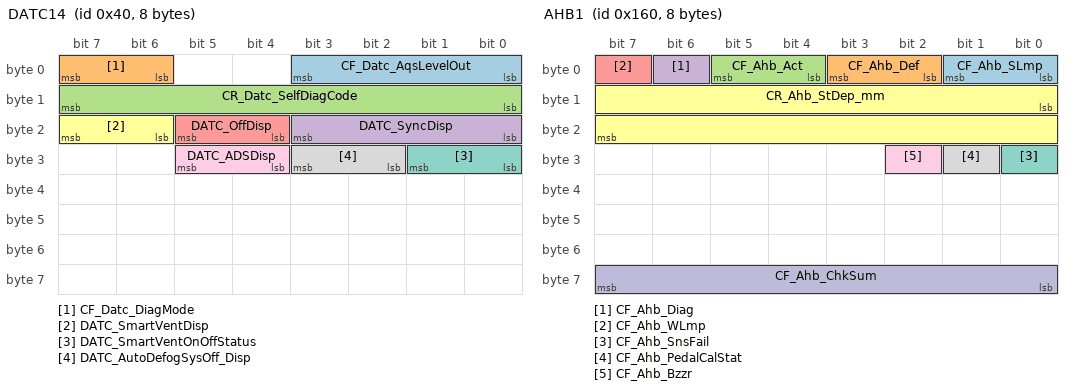
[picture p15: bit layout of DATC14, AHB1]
BO_ 64 DATC14: 8 DATC
 SG_ CF_Datc_AqsLevelOut : 0|4@1+ (1.0,0.0) [0.0|3.0] ""  CLU
 SG_ CF_Datc_DiagMode : 6|2@1+ (1.0,0.0) [0.0|3.0] ""  CLU
 SG_ CR_Datc_SelfDiagCode : 8|8@1+ (1.0,-1.0) [0.0|254.0] ""  CLU
 SG_ DATC_SyncDisp : 16|4@1+ (1.0,0.0) [0.0|3.0] ""  CLU
 SG_ DATC_OffDisp : 20|2@1+ (1.0,0.0) [0.0|3.0] ""  CLU
 SG_ DATC_SmartVentDisp : 22|2@1+ (1.0,0.0) [0.0|3.0] ""  CLU
 SG_ DATC_SmartVentOnOffStatus : 24|2@1+ (1.0,0.0) [0.0|3.0] ""  CLU
 SG_ DATC_AutoDefogSysOff_Disp : 26|2@1+ (1.0,0.0) [0.0|3.0] ""  CLU
 SG_ DATC_ADSDisp : 28|2@1+ (1.0,0.0) [0.0|3.0] ""  CLU

BO_ 512 EMS20: 6 EMS
 SG_ FCO : 0|16@1+ (0.128,0.0) [0.0|8388.48] "ul"  CLU,CUBIS,FPCM,IBOX
 SG_ CF_Ems_PumpTPres : 16|8@1+ (3.137254902,0.0) [0.0|800.0] "kPa"  FPCM,IBOX
 SG_ Split_Stat : 32|1@1+ (1.0,0.0) [0.0|1.0] ""  FPCM

BO_ 357 S_MDPS12: 8 XXX
 SG_ NEW_SIGNAL_1 : 0|12@1+ (1,0) [0|4095] "" XXX
 SG_ NEW_SIGNAL_2 : 12|12@1+ (1,0) [0|4095] "" XXX
 SG_ Counter : 48|4@1+ (1,0) [0|15] "" XXX
 SG_ Checksum : 63|8@0+ (1,0) [0|255] "" XXX

BO_ 352 AHB1: 8 iBAU
 SG_ CF_Ahb_SLmp : 0|2@1+ (1,0) [0|3] "" CLU
 SG_ CF_Ahb_Def : 2|2@1+ (1,0) [0|3] "" CGW
 SG_ CF_Ahb_Act : 4|2@1+ (1,0) [0|3] "" Vector__XXX
 SG_ CF_Ahb_Diag : 6|1@1+ (1,0) [0|1] "" Vector__XXX
 SG_ CF_Ahb_WLmp : 7|1@1+ (1,0) [0|1] "" CLU
 SG_ CR_Ahb_StDep_mm : 8|16@1- (0.1,0) [-3276.8|3276.7] "mm" Vector__XXX
 SG_ CF_Ahb_SnsFail : 24|1@1+ (1,0) [0|1] "" Vector__XXX
 SG_ CF_Ahb_PedalCalStat : 25|1@1+ (1,0) [0|1] "" Vector__XXX
 SG_ CF_Ahb_Bzzr : 26|1@1+ (1,0) [0|1] "" Vector__XXX
 SG_ CF_Ahb_ChkSum : 56|8@1+ (1,0) [0|255] "" Vector__XXX

BO_ 304 YRS11: 8 ACU
 SG_ CR_Yrs_Yr : 0|16@1+ (0.005,-163.84) [-163.84|163.83] "deg/s" CGW,iBAU
 SG_ CR_Yrs_LatAc : 16|16@1+ (0.000127465,-4.17677312) [-4.17677312|4.17651819] "g" iBAU
 SG_ CF_Yrs_YrStat : 32|4@1+ (1,0) [0|15] "" iBAU
 SG_ CF_Yrs_LatAcStat : 36|4@1+ (1,0) [0|15] "" iBAU
 SG_ CF_Yrs_MCUStat : 40|4@1+ (1,0) [0|15] "" iBAU
 SG_ CR_Yrs_MsgCnt1 : 48|4@1+ (1,0) [0|15] "" iBAU
 SG_ CR_Yrs_Crc1 : 56|8@1+ (1,0) [0|255] "" iBAU

CM_ "BO_ E_EMS11: All (plug-in) hybrids use this gas signal: CR_Vcu_AccPedDep_Pos, and all EVs use the Accel_Pedal_Pos signal. See hyundai/values.py for a specific car list";

CM_
    BA_DEF_
    BA_
    CAT_DEF_
    CAT_
    FILTER
    BA_DEF_DEF_
    EV_DATA_
    ENVVAR_DATA_
    SGTYPE_
    SGTYPE_VAL_
    BA_DEF_SGTYPE_
    BA_SGTYPE_
    SIG_TYPE_REF_
    VAL_TABLE_
    SIG_GROUP_
    SIG_VALTYPE_
    SIGTYPE_VALTYPE_
    BO_TX_BU_
    BA_DEF_REL_
    BA_REL_
    BA_DEF_DEF_REL_
    BU_SG_REL_
    BU_EV_REL_
    BU_BO_REL_
    SG_MUL_VAL_

BS_:

BU_: XXX CAMERA FRONT_RADAR ADRV APRK

BO_ 53 ACCELERATOR: 32 XXX
 SG_ CHECKSUM : 0|16@1+ (1,0) [0|65535] "" XXX
 SG_ COUNTER : 16|8@1+ (1,0) [0|255] "" XXX
 SG_ GEAR : 192|3@1+ (1,0) [0|7] "" XXX
 SG_ ACCELERATOR_PEDAL : 40|8@1+ (1,0) [0|255] "" XXX

BO_ 64 GEAR_ALT: 32 XXX
 SG_ CHECKSUM : 0|16@1+ (1,0) [0|65535] "" XXX
 SG_ COUNTER : 16|8@1+ (1,0) [0|255] "" XXX
 SG_ GEAR : 32|3@1+ (1,0) [0|7] "" XXX

BO_ 69 GEAR: 24 XXX
 SG_ CHECKSUM : 0|16@1+ (1,0) [0|65535] "" XXX
 SG_ COUNTER : 16|8@1+ (1,0) [0|255] "" XXX
 SG_ GEAR : 44|3@1+ (1,0) [0|7] "" XXX

BO_ 80 LKAS: 16 XXX
 SG_ STEER_REQ : 52|1@1+ (1,0) [0|1] "" XXX
 SG_ TORQUE_REQUEST : 41|11@1+ (1,-1024) [0|4095] "" XXX
 SG_ LKA_ICON : 38|2@1+ (1,0) [0|255] "" XXX
 SG_ NEW_SIGNAL_1 : 27|2@1+ (1,0) [0|255] "" XXX
 SG_ LFA_BUTTON : 56|1@1+ (1,0) [0|255] "" XXX
 SG_ COUNTER : 16|8@1+ (1,0) [0|255] "" XXX
 SG_ CHECKSUM : 0|16@1+ (1,0) [0|65535] "" XXX
 SG_ STEER_MODE : 65|3@1+ (1,0) [0|1] "" XXX
 SG_ LKA_WARNING : 32|1@1+ (1,0) [0|1] "" XXX
 SG_ LKA_ASSIST : 62|1@1+ (1,0) [0|1] "" XXX
 SG_ LKA_MODE : 24|3@1+ (1,0) [0|7] "" XXX
 SG_ NEW_SIGNAL_2 : 70|2@0+ (1,0) [0|3] "" XXX
 SG_ HAS_LANE_SAFETY : 80|1@0+ (1,0) [0|1] "" XXX
 SG_ NEW_SIGNAL_3 : 111|8@0+ (1,0) [0|255] "" XXX
 SG_ FCA_SYSWARN : 40|1@0+ (1,0) [0|1] "" XXX

BO_ 81 ADRV_0x51: 32 ADRV
 SG_ COUNTER : 16|8@1+ (1,0) [0|255] "" XXX
 SG_ CHECKSUM : 0|16@1+ (1,0) [0|65535] "" XXX

BO_ 96 ESP_STATUS: 32 XXX
 SG_ CHECKSUM : 0|16@1+ (1,0) [0|65535] "" XXX
 SG_ COUNTER : 16|8@1+ (1,0) [0|255] "" XXX
 SG_ TRACTION_AND_STABILITY_CONTROL : 42|3@1+ (1,0) [0|63] "" XXX
 SG_ BRAKE_PRESSURE : 128|10@1+ (1,0) [0|65535] "" XXX
 SG_ BRAKE_PRESSED : 148|1@1+ (1,0) [0|3] "" XXX

BO_ 101 BRAKE: 32 XXX
 SG_ CHECKSUM : 0|16@1+ (1,0) [0|65535] "" XXX
 SG_ COUNTER : 16|8@1+ (1,0) [0|255] "" XXX
 SG_ BRAKE_POSITION : 40|16@1- (1,0) [0|65535] "" XXX
 SG_ BRAKE_PRESSED : 57|1@1+ (1,0) [0|3] "" XXX

BO_ 112 GEAR_ALT_2: 32 XXX
 SG_ CHECKSUM : 0|16@1+ (1,0) [0|65535] "" XXX
 SG_ COUNTER : 16|8@1+ (1,0) [0|255] "" XXX
 SG_ GEAR : 60|3@1+ (1,0) [0|7] "" XXX

BO_ 160 WHEEL_SPEEDS: 24 XXX
 SG_ CHECKSUM : 0|16@1+ (1,0) [0|65535] "" XXX
 SG_ COUNTER : 16|8@1+ (1,0) [0|255] "" XXX
 SG_ MOVING_FORWARD : 56|1@0+ (1,0) [0|1] "" XXX
 SG_ MOVING_BACKWARD : 57|1@0+ (1,0) [0|1] "" XXX
 SG_ MOVING_FORWARD2 : 58|1@0+ (1,0) [0|1] "" XXX
 SG_ MOVING_BACKWARD2 : 59|1@0+ (1,0) [0|1] "" XXX
 SG_ WHEEL_SPEED_1 : 64|16@1+ (0.03125,0) [0|65535] "kph" XXX
 SG_ WHEEL_SPEED_2 : 80|16@1+ (0.03125,0) [0|65535] "kph" XXX
 SG_ WHEEL_SPEED_3 : 96|16@1+ (0.03125,0) [0|65535] "kph" XXX
 SG_ WHEEL_SPEED_4 : 112|16@1+ (0.03125,0) [0|65535] "kph" XXX

BO_ 234 MDPS: 24 XXX
 SG_ CHECKSUM : 0|16@1+ (1,0) [0|65535] "" XXX
 SG_ COUNTER : 16|8@1+ (1,0) [0|255] "" XXX
 SG_ LKA_ACTIVE : 48|1@0+ (1,0) [0|16777215] "" XXX
 SG_ LKA_FAULT : 54|1@0+ (1,0) [0|1] "" XXX
 SG_ STEERING_OUT_TORQUE : 64|12@1+ (0.1,-204.8) [0|65535] "" XXX
 SG_ STEERING_COL_TORQUE : 80|13@1+ (1,-4095) [0|4095] "" XXX
 SG_ STEERING_ANGLE : 96|16@1- (-0.1,0) [0|255] "deg" XXX
 SG_ STEERING_ANGLE_2 : 128|16@1- (-0.1,0) [0|65535] "deg" XXX

BO_ 256 ACCELERATOR_BRAKE_ALT: 32 XXX
 SG_ CHECKSUM : 0|16@1+ (1,0) [0|65535] "" XXX
 SG_ COUNTER : 16|8@1+ (1,0) [0|255] "" XXX
 SG_ BRAKE_PRESSED : 32|1@1+ (1,0) [0|1] "" XXX
 SG_ ACCELERATOR_PEDAL_PRESSED : 176|1@1+ (1,0) [0|1] "" XXX

BO_ 261 ACCELERATOR_ALT: 32 XXX
 SG_ CHECKSUM : 0|16@1+ (1,0) [0|65535] "" XXX
 SG_ COUNTER : 16|8@1+ (1,0) [0|255] "" XXX
 SG_ ACCELERATOR_PEDAL : 103|10@1+ (0.25,0) [0|1022] "" XXX

BO_ 272 LKAS_ALT: 32 XXX
 SG_ STEER_REQ : 52|1@1+ (1,0) [0|1] "" XXX
 SG_ TORQUE_REQUEST : 41|11@1+ (1,-1024) [0|4095] "" XXX
 SG_ LKA_ICON : 38|2@1+ (1,0) [0|255] "" XXX
 SG_ NEW_SIGNAL_1 : 27|2@1+ (1,0) [0|255] "" XXX
 SG_ LFA_BUTTON : 56|1@1+ (1,0) [0|255] "" XXX
 SG_ COUNTER : 16|8@1+ (1,0) [0|255] "" XXX
 SG_ CHECKSUM : 0|16@1+ (1,0) [0|65535] "" XXX
 SG_ STEER_MODE : 65|3@1+ (1,0) [0|1] "" XXX
 SG_ LKA_WARNING : 32|1@1+ (1,0) [0|1] "" XXX
 SG_ LKA_ASSIST : 62|1@1+ (1,0) [0|1] "" XXX
 SG_ LKA_MODE : 24|3@1+ (1,0) [0|7] "" XXX
 SG_ NEW_SIGNAL_2 : 70|2@0+ (1,0) [0|3] "" XXX
 SG_ HAS_LANE_SAFETY : 80|1@0+ (1,0) [0|1] "" XXX
 SG_ NEW_SIGNAL_3 : 111|8@0+ (1,0) [0|255] "" XXX
 SG_ FCA_SYSWARN : 40|1@0+ (1,0) [0|1] "" XXX

BO_ 293 STEERING_SENSORS: 16 XXX
 SG_ CHECKSUM : 0|16@1+ (1,0) [0|65535] "" XXX
 SG_ COUNTER : 16|8@1+ (1,0) [0|255] "" XXX
 SG_ STEERING_RATE : 40|8@1+ (4,0) [0|1016] "deg/s" XXX
 SG_ STEERING_ANGLE : 24|16@1- (-0.1,0) [0|255] "deg" XXX

BO_ 298 LFA: 16 ADRV
 SG_ STEER_REQ : 52|1@1+ (1,0) [0|1] "" XXX
 SG_ TORQUE_REQUEST : 41|11@1+ (1,-1024) [0|4095] "" XXX
 SG_ LKA_ICON : 38|2@1+ (1,0) [0|255] "" XXX
 SG_ NEW_SIGNAL_1 : 27|2@1+ (1,0) [0|255] "" XXX
 SG_ LFA_BUTTON : 56|1@1+ (1,0) [0|255] "" XXX
 SG_ COUNTER : 16|8@1+ (1,0) [0|255] "" XXX
 SG_ CHECKSUM : 0|16@1+ (1,0) [0|65535] "" XXX
 SG_ STEER_MODE : 65|3@1+ (1,0) [0|1] "" XXX
 SG_ LKA_WARNING : 32|1@1+ (1,0) [0|1] "" XXX
 SG_ LKA_ASSIST : 62|1@1+ (1,0) [0|1] "" XXX
 SG_ LKA_MODE : 24|3@1+ (1,0) [0|7] "" XXX
 SG_ NEW_SIGNAL_2 : 70|2@0+ (1,0) [0|3] "" XXX
 SG_ HAS_LANE_SAFETY : 80|1@0+ (1,0) [0|1] "" XXX
 SG_ NEW_SIGNAL_3 : 111|8@0+ (1,0) [0|255] "" XXX

BO_ 304 GEAR_SHIFTER: 16 XXX
 SG_ CHECKSUM : 0|16@1+ (1,0) [0|65535] "" XXX
 SG_ COUNTER : 16|8@1+ (1,0) [0|255] "" XXX
 SG_ PARK_BUTTON : 32|2@1+ (1,0) [0|3] "" XXX
 SG_ GEAR : 64|3@1+ (1,0) [0|7] "" XXX
 SG_ KNOB_POSITION : 40|3@1+ (1,0) [0|3] "" XXX

BO_ 357 SPAS1: 24 APRK
 SG_ CHECKSUM : 0|16@1+ (1,0) [0|65535] "" XXX
 SG_ COUNTER : 16|8@1+ (1,0) [0|0] "" XXX
 SG_ NEW_SIGNAL_1 : 96|16@1- (0.1,0) [0|0] "" XXX
 SG_ NEW_SIGNAL_2 : 90|3@1+ (1,0) [0|0] "" XXX

BO_ 362 SPAS2: 32 APRK
 SG_ CHECKSUM : 0|16@1+ (1,0) [0|65535] "" XXX
 SG_ COUNTER : 16|8@1+ (1,0) [0|0] "" XXX
 SG_ BLINKER_CONTROL : 133|3@1+ (1,0) [0|0] "" XXX

BO_ 373 TCS: 24 XXX
 SG_ CHECKSUM : 0|16@1+ (1,0) [0|65535] "" XXX
 SG_ COUNTER : 16|8@1+ (1,0) [0|255] "" XXX
 SG_ NEW_SIGNAL_1 : 80|1@0+ (1,0) [0|1] "" XXX
 SG_ NEW_SIGNAL_2 : 74|1@0+ (1,0) [0|1] "" XXX
 SG_ NEW_SIGNAL_3 : 76|1@0+ (1,0) [0|1] "" XXX
 SG_ NEW_SIGNAL_4 : 24|7@1+ (1,0) [0|127] "" XXX
 SG_ aBasis : 32|11@1+ (0.01,-10.23) [0|7] "m/s^2" XXX
 SG_ NEW_SIGNAL_5 : 72|1@0+ (1,0) [0|1] "" XXX
 SG_ NEW_SIGNAL_6 : 128|4@1+ (1,0) [0|15] "" XXX
 SG_ NEW_SIGNAL_7 : 135|2@0+ (1,0) [0|3] "" XXX
 SG_ PROBABLY_EQUIP : 136|2@1+ (1,0) [0|3] "" XXX
 SG_ AEB_EQUIP_MAYBE : 96|1@0+ (1,0) [0|1] "" XXX
 SG_ EQUIP_MAYBE : 64|1@0+ (1,0) [0|1] "" XXX
 SG_ DriverBraking : 81|1@0+ (1,0) [0|1] "" XXX
 SG_ DriverBrakingLowSens : 84|1@1+ (1,0) [0|1] "" XXX
 SG_ ACC_REQ : 68|1@0+ (1,0) [0|1] "" XXX
 SG_ ACCEL_REF_ACC : 48|11@1- (1,0) [0|1023] "" XXX
 SG_ ACCEnable : 67|2@0+ (1,0) [0|3] "" XXX

BO_ 352 ADRV_0x160: 16 ADRV
 SG_ CHECKSUM : 0|16@1+ (1,0) [0|65535] "" XXX
 SG_ COUNTER : 16|8@1+ (1,0) [0|255] "" XXX
 SG_ SET_ME_FF : 64|8@1+ (1,0) [0|255] "" XXX
 SG_ SET_ME_FC : 72|8@1+ (1,0) [0|255] "" XXX
 SG_ SET_ME_2 : 56|8@1+ (1,0) [0|1] "" XXX
 SG_ AEB_SETTING : 24|2@1+ (1,0) [0|255] "" XXX
 SG_ SET_ME_9 : 80|8@1+ (1,0) [0|255] "" XXX

BO_ 384 CAM_0x180: 32 CAMERA
 SG_ CHECKSUM : 0|16@1+ (1,0) [0|65535] "" XXX
 SG_ COUNTER : 16|8@1+ (1,0) [0|255] "" XXX

BO_ 385 CAM_0x181: 32 CAMERA
 SG_ CHECKSUM : 0|16@1+ (1,0) [0|65535] "" XXX
 SG_ COUNTER : 16|8@1+ (1,0) [0|255] "" XXX

BO_ 386 CAM_0x182: 32 CAMERA
 SG_ CHECKSUM : 0|16@1+ (1,0) [0|65535] "" XXX
 SG_ COUNTER : 16|8@1+ (1,0) [0|255] "" XXX

BO_ 387 CAM_0x183: 32 CAMERA
 SG_ CHECKSUM : 0|16@1+ (1,0) [0|65535] "" XXX
 SG_ COUNTER : 16|8@1+ (1,0) [0|255] "" XXX

BO_ 388 CAM_0x184: 32 CAMERA
 SG_ CHECKSUM : 0|16@1+ (1,0) [0|65535] "" XXX
 SG_ COUNTER : 16|8@1+ (1,0) [0|255] "" XXX

BO_ 389 CAM_0x185: 8 CAMERA
 SG_ CHECKSUM : 0|16@1+ (1,0) [0|65535] "" XXX
 SG_ COUNTER : 16|8@1+ (1,0) [0|255] "" XXX

BO_ 416 SCC_CONTROL: 32 ADRV
 SG_ CHECKSUM : 0|16@1+ (1,0) [0|65535] "" XXX
 SG_ NEW_SIGNAL_1 : 64|2@1+ (1,0) [0|3] "" XXX
 SG_ NEW_SIGNAL_8 : 170|4@1+ (1,0) [0|15] "" XXX
 SG_ ZEROS : 215|48@0+ (1,0) [0|281474976710655] "" XXX
 SG_ ZEROS_3 : 191|7@0+ (1,0) [0|127] "" XXX
 SG_ ZEROS_4 : 183|4@0+ (1,0) [0|63] "" XXX
 SG_ ZEROS_6 : 119|16@0+ (1,0) [0|65535] "" XXX
 SG_ ZEROS_8 : 95|5@0+ (1,0) [0|31] "" XXX
 SG_ NEW_SIGNAL_3 : 109|2@0+ (1,0) [0|1] "" XXX
 SG_ SET_ME_TMP_64 : 55|8@0+ (1,0) [0|63] "" XXX
 SG_ SET_ME_2 : 105|3@1+ (1,0) [0|7] "" XXX
 SG_ NEW_SIGNAL_6 : 104|1@0+ (1,0) [0|1] "" XXX
 SG_ COUNTER : 16|8@1+ (1,0) [0|255] "" XXX
 SG_ ZEROS_9 : 71|5@1+ (1,0) [0|15] "" XXX
 SG_ ZEROS_10 : 111|2@0+ (1,0) [0|3] "" XXX
 SG_ SET_ME_3 : 45|2@0+ (1,0) [0|3] "" XXX
 SG_ ObjValid : 46|1@0+ (1,0) [0|3] "" XXX
 SG_ NEW_SIGNAL_2 : 168|2@1+ (1,0) [0|3] "" XXX
 SG_ OBJ_STATUS : 176|3@1+ (1,0) [0|7] "" XXX
 SG_ ACC_ObjDist : 24|11@1+ (0.1,0) [0|204.7] "m" XXX
 SG_ ZEROS_5 : 77|11@1+ (1,0) [0|2047] "" XXX
 SG_ DISTANCE_SETTING : 88|3@1+ (1,0) [0|3] "" XXX
 SG_ ZEROS_2 : 207|5@0+ (1,0) [0|63] "" XXX
 SG_ CRUISE_STANDSTILL : 76|1@1+ (1,0) [0|1] "" XXX
 SG_ aReqRaw : 140|11@1+ (0.01,-10.23) [-10.23|10.24] "m/s^2" XXX
 SG_ aReqValue : 128|11@1+ (0.01,-10.23) [-10.23|10.24] "m/s^2" XXX
 SG_ ZEROS_7 : 63|8@0+ (1,0) [0|255] "" XXX
 SG_ ACCMode : 68|3@1+ (1,0) [0|7] "" XXX
 SG_ ACC_ObjRelSpd : 35|9@1+ (0.1,-16.4) [-16.4|34.7] "m/s" XXX
 SG_ JerkLowerLimit : 166|7@0+ (0.1,0) [0|12.7] "m/s^3" XXX
 SG_ StopReq : 184|1@0+ (1,0) [0|1] "" XXX
 SG_ NEW_SIGNAL_15 : 192|11@1+ (0.1,0) [0|204.7] "m" XXX
 SG_ VSetDis : 103|8@0+ (1,0) [0|255] "km/h or mph" XXX
 SG_ MainMode_ACC : 66|1@1+ (1,0) [0|1] "" XXX
 SG_ JerkUpperLimit : 158|7@0+ (0.1,0) [0|0] "" XXX

BO_ 426 CRUISE_BUTTONS_ALT: 16 XXX
 SG_ CHECKSUM : 0|16@1+ (1,0) [0|65535] "" XXX
 SG_ COUNTER : 16|8@1+ (1,0) [0|255] "" XXX
 SG_ NEW_SIGNAL_1 : 24|4@1+ (1,0) [0|15] "" XXX
 SG_ SET_ME_1 : 28|2@1+ (1,0) [0|3] "" XXX
 SG_ DISTANCE_UNIT : 30|1@1+ (1,0) [0|1] "" XXX
 SG_ NEW_SIGNAL_2 : 31|3@1+ (1,0) [0|7] "" XXX
 SG_ ADAPTIVE_CRUISE_MAIN_BTN : 34|1@1+ (1,0) [0|1] "" XXX
 SG_ NEW_SIGNAL_3 : 35|1@1+ (1,0) [0|1] "" XXX
 SG_ LFA_BTN : 39|1@1+ (1,0) [0|1] "" XXX
 SG_ CRUISE_BUTTONS : 36|3@1+ (1,0) [0|4] "" XXX
 SG_ NEW_SIGNAL_4 : 40|1@1+ (1,0) [0|1] "" XXX
 SG_ NORMAL_CRUISE_MAIN_BTN : 41|1@1+ (1,0) [0|1] "" XXX
 SG_ NEW_SIGNAL_5 : 42|2@1+ (1,0) [0|3] "" XXX
 SG_ SET_ME_2 : 44|3@1+ (1,0) [0|7] "" XXX
 SG_ NEW_SIGNAL_6 : 47|1@1+ (1,0) [0|1] "" XXX
 SG_ BYTE6 : 48|8@1+ (1,0) [0|255] "" XXX
 SG_ BYTE7 : 56|8@1+ (1,0) [0|255] "" XXX
 SG_ BYTE8 : 64|8@1+ (1,0) [0|255] "" XXX
 SG_ BYTE9 : 72|8@1+ (1,0) [0|255] "" XXX
 SG_ BYTE10 : 80|8@1+ (1,0) [0|255] "" XXX
 SG_ BYTE11 : 88|8@1+ (1,0) [0|255] "" XXX
 SG_ BYTE12 : 96|8@1+ (1,0) [0|255] "" XXX
 SG_ BYTE13 : 104|8@1+ (1,0) [0|255] "" XXX
 SG_ BYTE14 : 112|8@1+ (1,0) [0|255] "" XXX
 SG_ BYTE15 : 120|8@1+ (1,0) [0|255] "" XXX

BO_ 438 CAM_0x1b6: 32 CAMERA
 SG_ CHECKSUM : 0|16@1+ (1,0) [0|65535] "" XXX
 SG_ COUNTER : 16|8@1+ (1,0) [0|255] "" XXX

BO_ 439 CAM_0x1b7: 32 CAMERA
 SG_ CHECKSUM : 0|16@1+ (1,0) [0|65535] "" XXX
 SG_ COUNTER : 16|8@1+ (1,0) [0|255] "" XXX

BO_ 440 CAM_0x1b8: 32 CAMERA
 SG_ CHECKSUM : 0|16@1+ (1,0) [0|65535] "" XXX
 SG_ COUNTER : 16|8@1+ (1,0) [0|255] "" XXX

BO_ 441 CAM_0x1b9: 32 CAMERA
 SG_ CHECKSUM : 0|16@1+ (1,0) [0|65535] "" XXX
 SG_ COUNTER : 16|8@1+ (1,0) [0|255] "" XXX

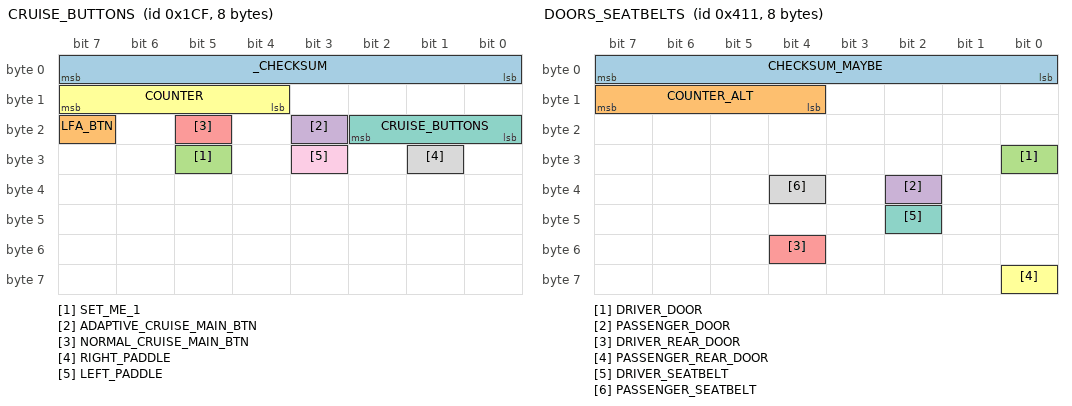
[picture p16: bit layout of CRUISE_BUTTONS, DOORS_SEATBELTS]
BO_ 463 CRUISE_BUTTONS: 8 XXX
 SG_ _CHECKSUM : 0|8@1+ (1,0) [0|65535] "" XXX
 SG_ LFA_BTN : 23|1@1+ (1,0) [0|1] "" XXX
 SG_ SET_ME_1 : 29|1@1+ (1,0) [0|1] "" XXX
 SG_ ADAPTIVE_CRUISE_MAIN_BTN : 19|1@1+ (1,0) [0|1] "" XXX
 SG_ NORMAL_CRUISE_MAIN_BTN : 21|1@1+ (1,0) [0|1] "" XXX
 SG_ COUNTER : 12|4@1+ (1,0) [0|255] "" XXX
 SG_ CRUISE_BUTTONS : 16|3@1+ (1,0) [0|3] "" XXX
 SG_ RIGHT_PADDLE : 25|1@1+ (1,0) [0|1] "" XXX
 SG_ LEFT_PADDLE : 27|1@1+ (1,0) [0|1] "" XXX

BO_ 474 ADRV_0x1da: 32 ADRV
 SG_ CHECKSUM : 0|16@1+ (1,0) [0|65535] "" XXX
 SG_ COUNTER : 16|8@1+ (1,0) [0|255] "" XXX
 SG_ SET_ME_22 : 31|8@0+ (1,0) [0|255] "" XXX
 SG_ SET_ME_41 : 47|8@0+ (1,0) [0|255] "" XXX

BO_ 480 LFAHDA_CLUSTER: 16 ADRV
 SG_ CHECKSUM : 0|16@1+ (1,0) [0|65535] "" XXX
 SG_ COUNTER : 16|8@1+ (1,0) [0|255] "" XXX
 SG_ HDA_ICON : 31|1@1+ (1,0) [0|1] "" XXX
 SG_ LFA_ICON : 47|2@1+ (1,0) [0|3] "" XXX
 SG_ NEW_SIGNAL_1 : 32|3@1+ (1,0) [0|7] "" XXX
 SG_ NEW_SIGNAL_2 : 30|1@0+ (1,0) [0|1] "" XXX
 SG_ NEW_SIGNAL_3 : 49|1@0+ (1,0) [0|1] "" XXX
 SG_ NEW_SIGNAL_4 : 24|1@0+ (1,0) [0|1] "" XXX

BO_ 490 ADRV_0x1ea: 32 ADRV
 SG_ CHECKSUM : 0|16@1+ (1,0) [0|65535] "" XXX
 SG_ COUNTER : 16|8@1+ (1,0) [0|255] "" XXX
 SG_ SET_ME_1C : 31|8@0+ (1,0) [0|255] "" XXX
 SG_ NEW_SIGNAL_1 : 32|2@1+ (1,0) [0|3] "" XXX
 SG_ NEW_SIGNAL_2 : 47|2@0+ (1,0) [0|3] "" XXX
 SG_ NEW_SIGNAL_3 : 55|8@0+ (1,0) [0|255] "" XXX
 SG_ NEW_SIGNAL_4 : 64|6@1+ (1,0) [0|31] "" XXX
 SG_ NEW_SIGNAL_5 : 72|2@1+ (1,0) [0|3] "" XXX
 SG_ NEW_SIGNAL_6 : 75|5@1+ (1,0) [0|31] "" XXX
 SG_ NEW_SIGNAL_7 : 80|5@1+ (1,0) [0|31] "" XXX
 SG_ NEW_SIGNAL_8 : 88|7@1+ (1,0) [0|127] "" XXX
 SG_ NEW_SIGNAL_9 : 96|1@0+ (1,0) [0|1] "" XXX
 SG_ NEW_SIGNAL_10 : 143|5@0+ (1,0) [0|31] "" XXX
 SG_ NEW_SIGNAL_11 : 144|3@1+ (1,0) [0|7] "" XXX
 SG_ NEW_SIGNAL_12 : 152|6@1+ (1,0) [0|63] "" XXX
 SG_ NEW_SIGNAL_13 : 160|1@0+ (1,0) [0|1] "" XXX
 SG_ NEW_SIGNAL_14 : 163|5@1+ (1,0) [0|31] "" XXX
 SG_ NEW_SIGNAL_15 : 175|4@0+ (1,0) [0|63] "" XXX
 SG_ NEW_SIGNAL_16 : 168|3@1+ (1,0) [0|7] "" XXX
 SG_ NEW_SIGNAL_17 : 176|2@1+ (1,0) [0|3] "" XXX
 SG_ NEW_SIGNAL_18 : 184|1@0+ (1,0) [0|1] "" XXX
 SG_ NEW_SIGNAL_19 : 208|3@1+ (1,0) [0|7] "" XXX
 SG_ NEW_SIGNAL_20 : 212|1@0+ (1,0) [0|1] "" XXX
 SG_ SET_ME_FF : 120|8@1+ (1,0) [0|255] "" XXX
 SG_ SET_ME_TMP_F : 232|5@1+ (1,0) [0|31] "" XXX
 SG_ SET_ME_TMP_F_2 : 240|5@1+ (1,0) [0|31] "" XXX

BO_ 507 CAM_0x1fb: 32 CAMERA
 SG_ CHECKSUM : 0|16@1+ (1,0) [0|65535] "" XXX
 SG_ COUNTER : 16|8@1+ (1,0) [0|255] "" XXX

BO_ 512 ADRV_0x200: 8 ADRV
 SG_ CHECKSUM : 0|16@1+ (1,0) [0|65535] "" XXX
 SG_ COUNTER : 16|8@1+ (1,0) [0|255] "" XXX
 SG_ SET_ME_E1 : 24|8@1+ (1,0) [0|255] "" XXX
 SG_ SET_ME_3A : 32|8@1+ (1,0) [0|255] "" XXX

BO_ 513 RADAR_0x201: 32 FRONT_RADAR
 SG_ CHECKSUM : 0|16@1+ (1,0) [0|65535] "" XXX
 SG_ COUNTER : 16|8@1+ (1,0) [0|255] "" XXX

BO_ 528 RADAR_0x210: 32 FRONT_RADAR
 SG_ CHECKSUM : 0|16@1+ (1,0) [0|65535] "" XXX
 SG_ COUNTER : 16|8@1+ (1,0) [0|255] "" XXX

BO_ 529 RADAR_0x211: 32 FRONT_RADAR
 SG_ CHECKSUM : 0|16@1+ (1,0) [0|65535] "" XXX
 SG_ COUNTER : 16|8@1+ (1,0) [0|255] "" XXX

BO_ 530 RADAR_0x212: 32 FRONT_RADAR
 SG_ CHECKSUM : 0|16@1+ (1,0) [0|65535] "" XXX
 SG_ COUNTER : 16|8@1+ (1,0) [0|255] "" XXX

BO_ 531 RADAR_0x213: 32 FRONT_RADAR
 SG_ CHECKSUM : 0|16@1+ (1,0) [0|65535] "" XXX
 SG_ COUNTER : 16|8@1+ (1,0) [0|255] "" XXX

BO_ 532 RADAR_0x214: 32 FRONT_RADAR
 SG_ CHECKSUM : 0|16@1+ (1,0) [0|65535] "" XXX
 SG_ COUNTER : 16|8@1+ (1,0) [0|255] "" XXX

BO_ 533 RADAR_0x215: 32 FRONT_RADAR
 SG_ CHECKSUM : 0|16@1+ (1,0) [0|65535] "" XXX
 SG_ COUNTER : 16|8@1+ (1,0) [0|255] "" XXX

BO_ 534 RADAR_0x216: 32 FRONT_RADAR
 SG_ CHECKSUM : 0|16@1+ (1,0) [0|65535] "" XXX
 SG_ COUNTER : 16|8@1+ (1,0) [0|255] "" XXX

BO_ 535 RADAR_0x217: 32 FRONT_RADAR
 SG_ CHECKSUM : 0|16@1+ (1,0) [0|65535] "" XXX
 SG_ COUNTER : 16|8@1+ (1,0) [0|255] "" XXX

BO_ 536 RADAR_0x218: 32 FRONT_RADAR
 SG_ CHECKSUM : 0|16@1+ (1,0) [0|65535] "" XXX
 SG_ COUNTER : 16|8@1+ (1,0) [0|255] "" XXX

BO_ 537 RADAR_0x219: 32 FRONT_RADAR
 SG_ CHECKSUM : 0|16@1+ (1,0) [0|65535] "" XXX
 SG_ COUNTER : 16|8@1+ (1,0) [0|255] "" XXX

BO_ 538 RADAR_0x21a: 32 FRONT_RADAR
 SG_ CHECKSUM : 0|16@1+ (1,0) [0|65535] "" XXX
 SG_ COUNTER : 16|8@1+ (1,0) [0|255] "" XXX

BO_ 539 RADAR_0x21b: 32 FRONT_RADAR
 SG_ CHECKSUM : 0|16@1+ (1,0) [0|65535] "" XXX
 SG_ COUNTER : 16|8@1+ (1,0) [0|255] "" XXX

BO_ 540 RADAR_0x21c: 32 FRONT_RADAR
 SG_ CHECKSUM : 0|16@1+ (1,0) [0|65535] "" XXX
 SG_ COUNTER : 16|8@1+ (1,0) [0|255] "" XXX

BO_ 541 RADAR_0x21d: 32 FRONT_RADAR
 SG_ CHECKSUM : 0|16@1+ (1,0) [0|65535] "" XXX
 SG_ COUNTER : 16|8@1+ (1,0) [0|255] "" XXX

BO_ 542 RADAR_0x21e: 32 FRONT_RADAR
 SG_ CHECKSUM : 0|16@1+ (1,0) [0|65535] "" XXX
 SG_ COUNTER : 16|8@1+ (1,0) [0|255] "" XXX

BO_ 543 RADAR_0x21f: 32 FRONT_RADAR
 SG_ CHECKSUM : 0|16@1+ (1,0) [0|65535] "" XXX
 SG_ COUNTER : 16|8@1+ (1,0) [0|255] "" XXX

BO_ 576 RADAR_0x240: 16 FRONT_RADAR
 SG_ CHECKSUM : 0|16@1+ (1,0) [0|65535] "" XXX
 SG_ COUNTER : 16|8@1+ (1,0) [0|255] "" XXX

BO_ 593 RADAR_0x251: 16 FRONT_RADAR
 SG_ CHECKSUM : 0|16@1+ (1,0) [0|65535] "" XXX
 SG_ COUNTER : 16|8@1+ (1,0) [0|255] "" XXX

BO_ 674 CAM_0x2a2: 32 CAMERA
 SG_ CHECKSUM : 0|16@1+ (1,0) [0|65535] "" XXX
 SG_ COUNTER : 16|8@1+ (1,0) [0|255] "" XXX

BO_ 675 CAM_0x2a3: 32 CAMERA
 SG_ CHECKSUM : 0|16@1+ (1,0) [0|65535] "" XXX
 SG_ COUNTER : 16|8@1+ (1,0) [0|255] "" XXX

BO_ 676 CAM_0x2a4: 24 XXX
 SG_ CHECKSUM : 0|16@1+ (1,0) [0|65535] "" XXX
 SG_ COUNTER : 16|8@1+ (1,0) [0|255] "" XXX
 SG_ BYTE3 : 24|8@1+ (1,0) [0|255] "" XXX
 SG_ BYTE4 : 32|8@1+ (1,0) [0|255] "" XXX
 SG_ BYTE5 : 40|8@1+ (1,0) [0|255] "" XXX
 SG_ BYTE6 : 48|8@1+ (1,0) [0|255] "" XXX
 SG_ LEFT_LANE_LINE : 56|2@1+ (1,0) [0|3] "" XXX
 SG_ SET_ME_0 : 58|2@1+ (1,0) [0|3] "" XXX
 SG_ RIGHT_LANE_LINE : 60|2@1+ (1,0) [0|3] "" XXX
 SG_ SET_ME_0_2 : 62|2@1+ (1,0) [0|3] "" XXX
 SG_ BYTE8 : 64|8@1+ (1,0) [0|255] "" XXX
 SG_ BYTE9 : 72|8@1+ (1,0) [0|255] "" XXX
 SG_ BYTE10 : 80|8@1+ (1,0) [0|255] "" XXX
 SG_ BYTE11 : 88|8@1+ (1,0) [0|255] "" XXX
 SG_ BYTE12 : 96|8@1+ (1,0) [0|255] "" XXX
 SG_ BYTE13 : 104|8@1+ (1,0) [0|255] "" XXX
 SG_ BYTE14 : 112|8@1+ (1,0) [0|255] "" XXX
 SG_ BYTE15 : 120|8@1+ (1,0) [0|255] "" XXX
 SG_ BYTE16 : 128|8@1+ (1,0) [0|255] "" XXX
 SG_ BYTE17 : 136|8@1+ (1,0) [0|255] "" XXX
 SG_ BYTE18 : 144|8@1+ (1,0) [0|255] "" XXX
 SG_ BYTE19 : 152|8@1+ (1,0) [0|255] "" XXX
 SG_ BYTE20 : 160|8@1+ (1,0) [0|255] "" XXX
 SG_ BYTE21 : 168|8@1+ (1,0) [0|255] "" XXX
 SG_ BYTE22 : 176|8@1+ (1,0) [0|255] "" XXX
 SG_ BYTE23 : 184|8@1+ (1,0) [0|255] "" XXX

BO_ 699 CAM_0x2bb: 32 CAMERA
 SG_ CHECKSUM : 0|16@1+ (1,0) [0|65535] "" XXX
 SG_ COUNTER : 16|8@1+ (1,0) [0|255] "" XXX

BO_ 700 CAM_0x2bc: 32 CAMERA
 SG_ CHECKSUM : 0|16@1+ (1,0) [0|65535] "" XXX
 SG_ COUNTER : 16|8@1+ (1,0) [0|255] "" XXX

BO_ 701 CAM_0x2bd: 32 CAMERA
 SG_ CHECKSUM : 0|16@1+ (1,0) [0|65535] "" XXX
 SG_ COUNTER : 16|8@1+ (1,0) [0|255] "" XXX

BO_ 702 CAM_0x2be: 32 CAMERA
 SG_ CHECKSUM : 0|16@1+ (1,0) [0|65535] "" XXX
 SG_ COUNTER : 16|8@1+ (1,0) [0|255] "" XXX

BO_ 736 MANUAL_SPEED_LIMIT_ASSIST: 32 XXX
 SG_ CHECKSUM : 0|16@1+ (1,0) [0|65535] "" XXX
 SG_ COUNTER : 16|8@1+ (1,0) [0|255] "" XXX
 SG_ MSLA_STATUS : 26|2@1+ (1,0) [0|3] "" XXX
 SG_ MSLA_ENABLED : 38|1@1+ (1,0) [0|1] "" XXX
 SG_ MAX_SPEED : 55|8@0+ (1,0) [0|255] "" XXX
 SG_ MAX_SPEED_COPY : 144|8@1+ (1,0) [0|255] "" XXX

BO_ 837 ADRV_0x345: 8 ADRV
 SG_ CHECKSUM : 0|16@1+ (1,0) [0|65535] "" XXX
 SG_ COUNTER : 16|8@1+ (1,0) [0|255] "" XXX
 SG_ SET_ME_15 : 24|8@1+ (1,0) [0|255] "" XXX

BO_ 866 CAM_0x362: 32 CAMERA
 SG_ CHECKSUM : 0|16@1+ (1,0) [0|65535] "" XXX
 SG_ COUNTER : 16|8@1+ (1,0) [0|255] "" XXX
 SG_ BYTE3 : 24|8@1+ (1,0) [0|255] "" XXX
 SG_ BYTE4 : 32|8@1+ (1,0) [0|255] "" XXX
 SG_ BYTE5 : 40|8@1+ (1,0) [0|255] "" XXX
 SG_ BYTE6 : 48|8@1+ (1,0) [0|255] "" XXX
 SG_ LEFT_LANE_LINE : 56|2@1+ (1,0) [0|3] "" XXX
 SG_ SET_ME_0 : 58|2@1+ (1,0) [0|3] "" XXX
 SG_ RIGHT_LANE_LINE : 60|2@1+ (1,0) [0|3] "" XXX
 SG_ SET_ME_0_2 : 62|2@1+ (1,0) [0|3] "" XXX
 SG_ BYTE8 : 64|8@1+ (1,0) [0|255] "" XXX
 SG_ BYTE9 : 72|8@1+ (1,0) [0|255] "" XXX
 SG_ BYTE10 : 80|8@1+ (1,0) [0|255] "" XXX
 SG_ BYTE11 : 88|8@1+ (1,0) [0|255] "" XXX
 SG_ BYTE12 : 96|8@1+ (1,0) [0|255] "" XXX
 SG_ BYTE13 : 104|8@1+ (1,0) [0|255] "" XXX
 SG_ BYTE14 : 112|8@1+ (1,0) [0|255] "" XXX
 SG_ BYTE15 : 120|8@1+ (1,0) [0|255] "" XXX
 SG_ BYTE16 : 128|8@1+ (1,0) [0|255] "" XXX
 SG_ BYTE17 : 136|8@1+ (1,0) [0|255] "" XXX
 SG_ BYTE18 : 144|8@1+ (1,0) [0|255] "" XXX
 SG_ BYTE19 : 152|8@1+ (1,0) [0|255] "" XXX
 SG_ BYTE20 : 160|8@1+ (1,0) [0|255] "" XXX
 SG_ BYTE21 : 168|8@1+ (1,0) [0|255] "" XXX
 SG_ BYTE22 : 176|8@1+ (1,0) [0|255] "" XXX
 SG_ BYTE23 : 184|8@1+ (1,0) [0|255] "" XXX
 SG_ BYTE24 : 192|8@1+ (1,0) [0|255] "" XXX
 SG_ BYTE25 : 200|8@1+ (1,0) [0|255] "" XXX
 SG_ BYTE26 : 208|8@1+ (1,0) [0|255] "" XXX
 SG_ BYTE27 : 216|8@1+ (1,0) [0|255] "" XXX
 SG_ BYTE28 : 224|8@1+ (1,0) [0|255] "" XXX
 SG_ BYTE29 : 232|8@1+ (1,0) [0|255] "" XXX
 SG_ BYTE30 : 240|8@1+ (1,0) [0|255] "" XXX
 SG_ BYTE31 : 248|8@1+ (1,0) [0|255] "" XXX

BO_ 961 BLINKER_STALKS: 8 XXX
 SG_ COUNTER_ALT : 15|4@0+ (1,0) [0|15] "" XXX
 SG_ CHECKSUM_MAYBE : 7|8@0+ (1,0) [0|255] "" XXX
 SG_ HIGHBEAM_FORWARD : 18|1@0+ (1,0) [0|1] "" XXX
 SG_ HIGHBEAM_BACKWARD : 26|1@0+ (1,0) [0|1] "" XXX
 SG_ RIGHT_BLINKER : 32|1@0+ (1,0) [0|1] "" XXX
 SG_ LEFT_BLINKER : 30|1@0+ (1,0) [0|1] "" XXX
 SG_ LIGHT_KNOB_POSITION : 21|2@0+ (1,0) [0|3] "" XXX

BO_ 1041 DOORS_SEATBELTS: 8 XXX
 SG_ CHECKSUM_MAYBE : 7|8@0+ (1,0) [0|65535] "" XXX
 SG_ COUNTER_ALT : 15|4@0+ (1,0) [0|15] "" XXX
 SG_ DRIVER_DOOR : 24|1@1+ (1,0) [0|1] "" XXX
 SG_ PASSENGER_DOOR : 34|1@0+ (1,0) [0|1] "" XXX
 SG_ DRIVER_REAR_DOOR : 52|1@0+ (1,0) [0|1] "" XXX
 SG_ PASSENGER_REAR_DOOR : 56|1@0+ (1,0) [0|1] "" XXX
 SG_ DRIVER_SEATBELT : 42|1@0+ (1,0) [0|1] "" XXX
 SG_ PASSENGER_SEATBELT : 36|1@0+ (1,0) [0|1] "" XXX

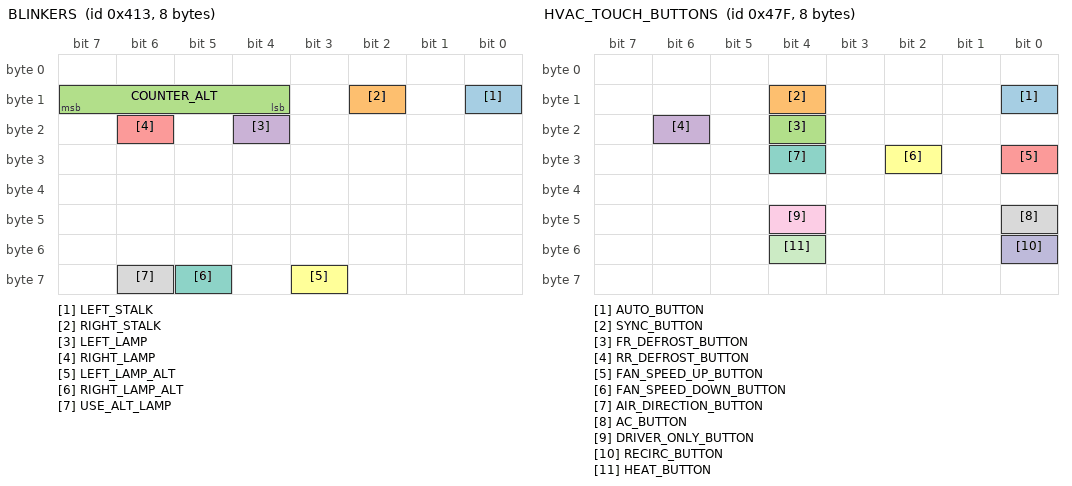
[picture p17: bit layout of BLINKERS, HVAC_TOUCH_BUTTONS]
BO_ 1043 BLINKERS: 8 XXX
 SG_ LEFT_STALK : 8|1@0+ (1,0) [0|1] "" XXX
 SG_ RIGHT_STALK : 10|1@0+ (1,0) [0|1] "" XXX
 SG_ COUNTER_ALT : 15|4@0+ (1,0) [0|15] "" XXX
 SG_ LEFT_LAMP : 20|1@0+ (1,0) [0|1] "" XXX
 SG_ RIGHT_LAMP : 22|1@0+ (1,0) [0|1] "" XXX
 SG_ LEFT_LAMP_ALT : 59|1@0+ (1,0) [0|1] "" XXX
 SG_ RIGHT_LAMP_ALT : 61|1@0+ (1,0) [0|1] "" XXX
 SG_ USE_ALT_LAMP : 62|1@0+ (1,0) [0|1] "" XXX

BO_ 1240 CLUSTER_INFO: 8 XXX
 SG_ DISTANCE_UNIT : 0|1@1+ (1,0) [0|1] "" XXX

BO_ 442 BLINDSPOTS_REAR_CORNERS: 24 XXX
 SG_ COUNTER : 16|8@1+ (1,0) [0|255] "" XXX
 SG_ CHECKSUM : 0|16@1+ (1,0) [0|65535] "" XXX
 SG_ NEW_SIGNAL_2 : 96|1@0+ (1,0) [0|1] "" XXX
 SG_ COLLISION_AVOIDANCE_ACTIVE : 68|1@0+ (1,0) [0|1] "" XXX
 SG_ LEFT_MB : 30|1@0+ (1,0) [0|3] "" XXX
 SG_ LEFT_BLOCKED : 24|1@0+ (1,0) [0|1] "" XXX
 SG_ MORE_LEFT_PROB : 32|1@1+ (1,0) [0|3] "" XXX
 SG_ FL_INDICATOR : 46|6@0+ (1,0) [0|1] "" XXX
 SG_ FR_INDICATOR : 54|6@0+ (1,0) [0|63] "" XXX
 SG_ RIGHT_BLOCKED : 64|1@0+ (1,0) [0|1] "" XXX
 SG_ FL_INDICATOR_ALT : 138|1@0+ (1,0) [0|1] "" XXX
 SG_ FR_INDICATOR_ALT : 141|1@0+ (1,0) [0|1] "" XXX

BO_ 874 BLINDSPOTS_FRONT_CORNER_2: 16 XXX
 SG_ COUNTER : 16|8@1+ (1,0) [0|255] "" XXX
 SG_ CHECKSUM : 0|16@1+ (1,0) [0|65535] "" XXX

BO_ 485 BLINDSPOTS_FRONT_CORNER_1: 16 XXX
 SG_ COUNTER : 16|8@1+ (1,0) [0|255] "" XXX
 SG_ CHECKSUM : 0|16@1+ (1,0) [0|65535] "" XXX
 SG_ NEW_SIGNAL_1 : 108|2@0+ (1,0) [0|3] "" XXX
 SG_ NEW_SIGNAL_2 : 96|1@0+ (1,0) [0|1] "" XXX
 SG_ NEW_SIGNAL_3 : 88|1@0+ (1,0) [0|1] "" XXX
 SG_ NEW_SIGNAL_4 : 80|1@0+ (1,0) [0|1] "" XXX
 SG_ NEW_SIGNAL_5 : 31|2@0+ (1,0) [0|3] "" XXX
 SG_ REVERSING : 24|1@0+ (1,0) [0|1] "" XXX
 SG_ NEW_SIGNAL_7 : 32|2@1+ (1,0) [0|3] "" XXX
 SG_ NEW_SIGNAL_8 : 47|8@0+ (1,0) [0|255] "" XXX
 SG_ NEW_SIGNAL_9 : 55|8@0+ (1,0) [0|255] "" XXX

BO_ 506 CLUSTER_SPEED_LIMIT: 32 XXX
 SG_ SPEED_LIMIT_3 : 119|8@0+ (1,0) [0|255] "" XXX
 SG_ SPEED_LIMIT_2 : 47|7@0+ (1,0) [0|255] "" XXX
 SG_ SPEED_LIMIT_1 : 39|7@0+ (1,0) [0|255] "" XXX
 SG_ SPEED_CHANGE_BLINKING : 129|1@1+ (1,0) [0|3] "" XXX
 SG_ CHIME_2 : 122|2@1+ (1,0) [0|7] "" XXX
 SG_ CHIME_1 : 133|1@0+ (1,0) [0|1] "" XXX
 SG_ ARROW_DOWN : 120|1@0+ (1,0) [0|1] "" XXX
 SG_ ARROW_UP : 121|1@0+ (1,0) [0|1] "" XXX
 SG_ SECONDARY_LIMIT_1 : 79|8@0+ (1,0) [0|127] "" XXX
 SG_ SECONDARY_LIMIT_2 : 103|8@0+ (1,0) [0|127] "" XXX
 SG_ SCHOOL_ZONE : 155|1@0+ (1,0) [0|1] "" XXX

BO_ 1144 DRIVE_MODE: 8 XXX
 SG_ DRIVE_MODE : 0|16@1+ (1,-61611) [0|61611] "" XXX
 SG_ DRIVE_MODE2 : 28|3@1+ (1,0) [1|3] "" XXX

BO_ 1151 HVAC_TOUCH_BUTTONS: 8 XXX
 SG_ AUTO_BUTTON : 8|1@0+ (1,0) [0|1] "" XXX
 SG_ SYNC_BUTTON : 12|1@0+ (1,0) [0|1] "" XXX
 SG_ FR_DEFROST_BUTTON : 20|1@0+ (1,0) [0|1] "" XXX
 SG_ RR_DEFROST_BUTTON : 22|1@0+ (1,0) [0|1] "" XXX
 SG_ FAN_SPEED_UP_BUTTON : 24|1@0+ (1,0) [0|1] "" XXX
 SG_ FAN_SPEED_DOWN_BUTTON : 26|1@0+ (1,0) [0|1] "" XXX
 SG_ AIR_DIRECTION_BUTTON : 28|1@0+ (1,0) [0|1] "" XXX
 SG_ AC_BUTTON : 40|1@0+ (1,0) [0|1] "" XXX
 SG_ DRIVER_ONLY_BUTTON : 44|1@0+ (1,0) [0|1] "" XXX
 SG_ RECIRC_BUTTON : 48|1@0+ (1,0) [0|1] "" XXX
 SG_ HEAT_BUTTON : 52|1@0+ (1,0) [0|1] "" XXX

BO_ 1259 LOCAL_TIME2: 8 XXX
 SG_ HOURS : 15|5@0+ (1,0) [0|31] "" XXX
 SG_ MINUTES : 21|6@0+ (1,0) [0|63] "" XXX
 SG_ SECONDS : 24|6@1+ (1,0) [0|63] "" XXX
 SG_ NEW_SIGNAL_3 : 39|1@0+ (1,0) [0|1] "" XXX

BO_ 1264 LOCAL_TIME: 8 XXX
 SG_ HOURS : 12|5@0+ (1,0) [0|31] "" XXX
 SG_ MINUTES : 21|6@0+ (1,0) [0|63] "" XXX
 SG_ SECONDS : 31|8@0+ (1,0) [0|59] "" XXX

CM_ 272 "Alternative LKAS message, used on cars such as 2023 Ioniq 6, 2nd gen Kona. Matches LKAS except size is 32 bytes";
CM_
 BA_DEF_
 BA_
 CAT_DEF_
 CAT_
 FILTER
 BA_DEF_DEF_
 EV_DATA_
 ENVVAR_DATA_
 SGTYPE_
 SGTYPE_VAL_
 BA_DEF_SGTYPE_
 BA_SGTYPE_
 SIG_TYPE_REF_
 VAL_TABLE_
 SIG_GROUP_
 SIG_VALTYPE_
 SIGTYPE_VALTYPE_
 BO_TX_BU_
 BA_DEF_REL_
 BA_REL_
 BA_DEF_DEF_REL_
 BU_SG_REL_
 BU_EV_REL_
 BU_BO_REL_
 SG_MUL_VAL_

BS_:

BU_: IAP ODS _4WD BCM HUD DATC MDPS AAF_Tester AEMC SMK _4WD EPB CUBIS MTS TMU EVP CGW TPMS LPI DI_BOX SPAS EMS LCA TCU IBOX FATC AFLS FPCM SCC AHLS AVM ABS SNV OPI PGS SAS AAF Dummy LDWS_LKAS LVR ESC PSB CLU ECS ACU REA

BO_ 387 REA11: 8 REA
 SG_ CF_EndBst_PwmDuH : 0|1@1+ (1.0,0.0) [0.0|1.0] ""  EMS
 SG_ CF_EndBst_PwmDuL : 1|1@1+ (1.0,0.0) [0.0|1.0] ""  EMS
 SG_ CF_EndBst_PwmFqOutRng : 2|1@1+ (1.0,0.0) [0.0|1.0] ""  EMS
 SG_ CF_EndBst_HbriOverCur : 3|1@1+ (1.0,0.0) [0.0|1.0] ""  EMS
 SG_ CF_EndBst_HbriOverTemp : 4|1@1+ (1.0,0.0) [0.0|1.0] ""  EMS
 SG_ CF_EndBst_PosSnsKOR : 6|1@1+ (1.0,0.0) [0.0|1.0] ""  EMS
 SG_ CF_EndBst_PosSnsOSOR : 7|1@1+ (1.0,0.0) [0.0|1.0] ""  EMS
 SG_ CF_EndBst_EepFlt : 8|1@1+ (1.0,0.0) [0.0|1.0] ""  EMS
 SG_ CF_EndBst_RomFlt : 9|1@1+ (1.0,0.0) [0.0|1.0] ""  EMS
 SG_ CF_EndBst_RamFlt : 10|1@1+ (1.0,0.0) [0.0|1.0] ""  EMS
 SG_ CF_EndBst_CanFlt : 11|1@1+ (1.0,0.0) [0.0|1.0] ""  EMS
 SG_ CF_EndBst_AgH : 12|1@1+ (1.0,0.0) [0.0|1.0] ""  EMS
 SG_ CF_EndBst_AgL : 13|1@1+ (1.0,0.0) [0.0|1.0] ""  EMS
 SG_ CF_EndBst_ORVol : 14|1@1+ (1.0,0.0) [0.0|1.0] ""  EMS
 SG_ CR_EndBst_ActPos : 16|16@1+ (0.117,0.0) [1.989|118.053] ""  EMS
 SG_ CR_EndBst_DemPos : 32|16@1+ (0.117,0.0) [0.0|119.691] ""  EMS
 SG_ CR_EndBst_HbriPwr : 48|16@1+ (0.045,0.0) [0.0|99.99] "%"  EMS

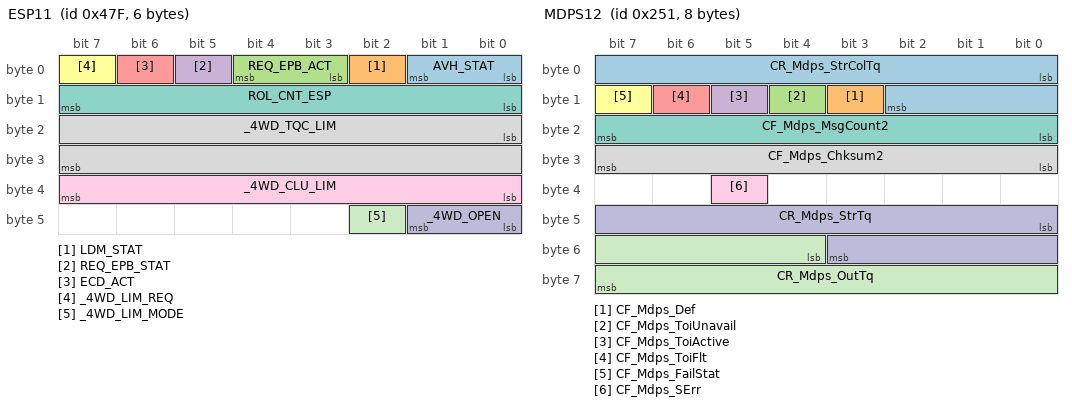
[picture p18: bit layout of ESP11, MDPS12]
BO_ 1151 ESP11: 6 ESC
 SG_ AVH_STAT : 0|2@1+ (1.0,0.0) [0.0|3.0] ""  EMS,EPB,TCU
 SG_ LDM_STAT : 2|1@1+ (1.0,0.0) [0.0|1.0] ""  EPB,TCU
 SG_ REQ_EPB_ACT : 3|2@1+ (1.0,0.0) [0.0|3.0] ""  EPB,TCU
 SG_ REQ_EPB_STAT : 5|1@1+ (1.0,0.0) [0.0|1.0] ""  EPB
 SG_ ECD_ACT : 6|1@1+ (1.0,0.0) [0.0|1.0] ""  EPB
 SG_ _4WD_LIM_REQ : 7|1@1+ (1.0,0.0) [0.0|1.0] ""  _4WD,EMS
 SG_ ROL_CNT_ESP : 8|8@1+ (1.0,0.0) [0.0|255.0] ""  EPB,TCU
 SG_ _4WD_TQC_LIM : 16|16@1+ (1.0,0.0) [0.0|65535.0] "Nm"  _4WD,EMS
 SG_ _4WD_CLU_LIM : 32|8@1+ (0.390625,0.0) [0.0|99.609375] "%"  _4WD,EMS
 SG_ _4WD_OPEN : 40|2@1+ (1.0,0.0) [0.0|3.0] ""  _4WD,EMS
 SG_ _4WD_LIM_MODE : 42|1@1+ (1.0,0.0) [0.0|1.0] ""  _4WD

BO_ 593 MDPS12: 8 MDPS
 SG_ CR_Mdps_StrColTq : 0|11@1+ (1.0,-1024.0) [-1024.0|1024.0] ""  LDWS_LKAS
 SG_ CF_Mdps_Def : 11|1@1+ (1.0,0.0) [0.0|1.0] ""  ESC
 SG_ CF_Mdps_ToiUnavail : 12|1@1+ (1.0,0.0) [0.0|1.0] ""  LDWS_LKAS
 SG_ CF_Mdps_ToiActive : 13|1@1+ (1.0,0.0) [0.0|1.0] ""  LDWS_LKAS
 SG_ CF_Mdps_ToiFlt : 14|1@1+ (1.0,0.0) [0.0|1.0] ""  LDWS_LKAS
 SG_ CF_Mdps_FailStat : 15|1@1+ (1.0,0.0) [0.0|1.0] ""  LDWS_LKAS
 SG_ CF_Mdps_MsgCount2 : 16|8@1+ (1.0,0.0) [0.0|255.0] ""  ESC,LDWS_LKAS
 SG_ CF_Mdps_Chksum2 : 24|8@1+ (1.0,0.0) [0.0|255.0] ""  ESC,LDWS_LKAS
 SG_ CF_Mdps_SErr : 37|1@1+ (1.0,0.0) [0.0|1.0] ""  ESC
 SG_ CR_Mdps_StrTq : 40|12@1+ (0.01,-20.48) [-20.48|20.47] "Nm"  ESC
 SG_ CR_Mdps_OutTq : 52|12@1+ (0.1,-204.8) [-204.8|204.7] ""  ESC,LDWS_LKAS

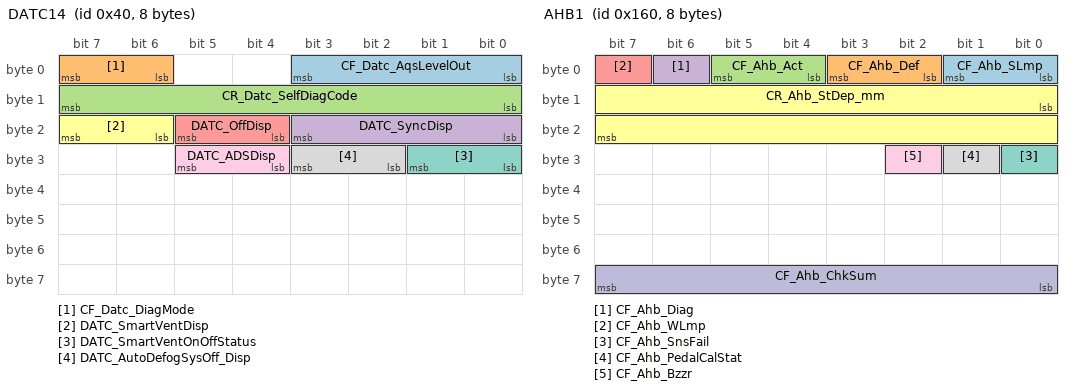
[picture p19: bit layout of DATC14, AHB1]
BO_ 64 DATC14: 8 DATC
 SG_ CF_Datc_AqsLevelOut : 0|4@1+ (1.0,0.0) [0.0|3.0] ""  CLU
 SG_ CF_Datc_DiagMode : 6|2@1+ (1.0,0.0) [0.0|3.0] ""  CLU
 SG_ CR_Datc_SelfDiagCode : 8|8@1+ (1.0,-1.0) [0.0|254.0] ""  CLU
 SG_ DATC_SyncDisp : 16|4@1+ (1.0,0.0) [0.0|3.0] ""  CLU
 SG_ DATC_OffDisp : 20|2@1+ (1.0,0.0) [0.0|3.0] ""  CLU
 SG_ DATC_SmartVentDisp : 22|2@1+ (1.0,0.0) [0.0|3.0] ""  CLU
 SG_ DATC_SmartVentOnOffStatus : 24|2@1+ (1.0,0.0) [0.0|3.0] ""  CLU
 SG_ DATC_AutoDefogSysOff_Disp : 26|2@1+ (1.0,0.0) [0.0|3.0] ""  CLU
 SG_ DATC_ADSDisp : 28|2@1+ (1.0,0.0) [0.0|3.0] ""  CLU

BO_ 512 EMS20: 6 EMS
 SG_ FCO : 0|16@1+ (0.128,0.0) [0.0|8388.48] "ul"  CLU,CUBIS,FPCM,IBOX
 SG_ CF_Ems_PumpTPres : 16|8@1+ (3.137254902,0.0) [0.0|800.0] "kPa"  FPCM,IBOX
 SG_ Split_Stat : 32|1@1+ (1.0,0.0) [0.0|1.0] ""  FPCM

BO_ 357 S_MDPS12: 8 XXX
 SG_ NEW_SIGNAL_1 : 0|12@1+ (1,0) [0|4095] "" XXX
 SG_ NEW_SIGNAL_2 : 12|12@1+ (1,0) [0|4095] "" XXX
 SG_ Counter : 48|4@1+ (1,0) [0|15] "" XXX
 SG_ Checksum : 63|8@0+ (1,0) [0|255] "" XXX

BO_ 352 AHB1: 8 iBAU
 SG_ CF_Ahb_SLmp : 0|2@1+ (1,0) [0|3] "" CLU
 SG_ CF_Ahb_Def : 2|2@1+ (1,0) [0|3] "" CGW
 SG_ CF_Ahb_Act : 4|2@1+ (1,0) [0|3] "" Vector__XXX
 SG_ CF_Ahb_Diag : 6|1@1+ (1,0) [0|1] "" Vector__XXX
 SG_ CF_Ahb_WLmp : 7|1@1+ (1,0) [0|1] "" CLU
 SG_ CR_Ahb_StDep_mm : 8|16@1- (0.1,0) [-3276.8|3276.7] "mm" Vector__XXX
 SG_ CF_Ahb_SnsFail : 24|1@1+ (1,0) [0|1] "" Vector__XXX
 SG_ CF_Ahb_PedalCalStat : 25|1@1+ (1,0) [0|1] "" Vector__XXX
 SG_ CF_Ahb_Bzzr : 26|1@1+ (1,0) [0|1] "" Vector__XXX
 SG_ CF_Ahb_ChkSum : 56|8@1+ (1,0) [0|255] "" Vector__XXX

BO_ 304 YRS11: 8 ACU
 SG_ CR_Yrs_Yr : 0|16@1+ (0.005,-163.84) [-163.84|163.83] "deg/s" CGW,iBAU
 SG_ CR_Yrs_LatAc : 16|16@1+ (0.000127465,-4.17677312) [-4.17677312|4.17651819] "g" iBAU
 SG_ CF_Yrs_YrStat : 32|4@1+ (1,0) [0|15] "" iBAU
 SG_ CF_Yrs_LatAcStat : 36|4@1+ (1,0) [0|15] "" iBAU
 SG_ CF_Yrs_MCUStat : 40|4@1+ (1,0) [0|15] "" iBAU
 SG_ CR_Yrs_MsgCnt1 : 48|4@1+ (1,0) [0|15] "" iBAU
 SG_ CR_Yrs_Crc1 : 56|8@1+ (1,0) [0|255] "" iBAU

CM_ "BO_ E_EMS11: All (plug-in) hybrids use this gas signal: CR_Vcu_AccPedDep_Pos, and all EVs use the Accel_Pedal_Pos signal. See hyundai/values.py for a specific car list";
CM_ "AUTOGENERATED FILE, DO NOT EDIT";
CM_ "hyundai_kia_mando_corner_radar.dbc starts here";
CM_ "hyundai_kia_mando_front_radar.dbc starts here";
CM_ 1043 "Lamp signals do not seem universal on cars that use LKAS_ALT, but stalk signals do.";
CM_ 676 "Contains signals with detailed lane line information. Used by ADAS ECU on HDA 2 vehicles to operate LFA.";
CM_ 866 "Contains signals with detailed lane line information. Used by ADAS ECU on HDA 2 vehicles to operate LFA. Used on cars that use message 272.";
CM_ SG_ 101 BRAKE_POSITION "User applied brake pedal position, max is ~700. Signed on some vehicles";
CM_ SG_ 1041 COUNTER_ALT "only increments on change";
CM_ SG_ 1043 COUNTER_ALT "only increments on change";
CM_ SG_ 1043 USE_ALT_LAMP "likely 1 on cars that use alt lamp signals";
CM_ SG_ 352 SET_ME_9 "has something to do with AEB settings";
CM_ SG_ 373 ACCEnable "Likely a copy of CAN's TCS13->ACCEnable";
CM_ SG_ 373 DriverBraking "Likely derived from BRAKE->BRAKE_POSITION";
CM_ SG_ 373 DriverBrakingLowSens "Higher threshold version of DriverBraking";
CM_ SG_ 373 PROBABLY_EQUIP "aeb equip?";
CM_ SG_ 416 VSetDis "set speed in display units";
CM_ SG_ 676 LEFT_LANE_LINE "Left lane line confidence";
CM_ SG_ 676 RIGHT_LANE_LINE "Right lane line confidence";
CM_ SG_ 736 MAX_SPEED "Display units. Restricts car from driving above this speed unless accelerator pedal is depressed beyond pressure point";
CM_ SG_ 80 HAS_LANE_SAFETY "If 0, hides LKAS 'Lane Safety' menu from vehicle settings";
CM_ SG_ 866 LEFT_LANE_LINE "Left lane line confidence";
CM_ SG_ 866 RIGHT_LANE_LINE "Right lane line confidence";
CM_ SG_ 96 BRAKE_PRESSURE "User applied brake pedal pressure. Ramps from computer applied pressure on falling edge of cruise. Cruise cancels if !=0";
CM_ SG_ 961 COUNTER_ALT "only increments on change";

CM_ "File 1: hyundai_canfd.dbc (Priority: 3)";
CM_ "File 2: hyundai_kia_mando_corner_radar_generated.dbc (Priority: 1)";
CM_ "File 3: hyundai_kia_mando_front_radar_generated.dbc (Priority: 2)";
CM_ "File 4: hyundai_kia_generic.dbc (Priority: 4)";

CM_ "Conflict resolutions:";
CM_ "Conflict 1: Message ID 64 (0x40) - Used hyundai_canfd.dbc definition (GEAR_ALT)";
CM_ "Conflict 2: Message ID 256 (0x100) - Used hyundai_kia_mando_corner_radar_generated.dbc definition (RADAR_POINTS_METADATA_0x100)";
CM_ "Conflict 3: Message ID 304 (0x130) - Used hyundai_canfd.dbc definition (GEAR_SHIFTER)";
CM_ "Conflict 4: Message ID 357 (0x165) - Used hyundai_canfd.dbc definition (SPAS1)";
CM_ "Conflict 5: Message ID 352 (0x160) - Used hyundai_canfd.dbc definition (ADRV_0x160)";
CM_ "Conflict 6: Message ID 387 (0x183) - Used hyundai_canfd.dbc definition (CAM_0x183)";
CM_ "Conflict 7: Message ID 512 (0x200) - Used hyundai_kia_mando_corner_radar_generated.dbc definition (RADAR_POINTS_METADATA_0x200)";
CM_ "Conflict 8: Message ID 513 (0x201) - Used hyundai_kia_mando_corner_radar_generated.dbc definition (RADAR_POINTS_0x201)";
CM_ "Conflict 9: Message ID 593 (0x251) - Used hyundai_canfd.dbc definition (RADAR_0x251)";
CM_ "Conflict 10: Message ID 1151 (0x47F) - Used hyundai_canfd.dbc definition (HVAC_TOUCH_BUTTONS)";
CM_ "Conflict 11: Message ID 354 (0x162) - Used hyundai_canfd.dbc definition (MSG_162)";
CM_ "Conflict 12: Message ID 1280 (0x500) - Used hyundai_kia_mando_front_radar_generated.dbc definition (RADAR_TRACK_500)";
CM_ "Conflict 13: Message ID 1281 (0x501) - Used hyundai_kia_mando_front_radar_generated.dbc definition (RADAR_TRACK_501)";
CM_ "Conflict 14: Message ID 1282 (0x502) - Used hyundai_kia_mando_front_radar_generated.dbc definition (RADAR_TRACK_502)";
CM_ "Conflict 15: Message ID 1287 (0x507) - Used hyundai_kia_mando_front_radar_generated.dbc definition (RADAR_TRACK_507)";
CM_ "Conflict 16: Message ID 1290 (0x50A) - Used hyundai_kia_mando_front_radar_generated.dbc definition (RADAR_TRACK_50a)";
CM_ "Conflict 17: Message ID 1292 (0x50C) - Used hyundai_kia_mando_front_radar_generated.dbc definition (RADAR_TRACK_50c)";
CM_ "Conflict 18: Message ID 1301 (0x515) - Used hyundai_kia_mando_front_radar_generated.dbc definition (RADAR_TRACK_515)";
CM_ "Conflict 19: Message ID 1307 (0x51B) - Used hyundai_kia_mando_front_radar_generated.dbc definition (RADAR_TRACK_51b)";
